VERSION "HNNBNNNYNNNNNNNNNNNNNNNNNNNNNNNNNNNNNNNNNN/4/%%%/4/'%**4NNN///"

NS_ :

BS_ :

BU_:  Airbag BAP_Tester ICAS1_Gateway ICAS1_KommunikationsServer LE1 LE2 Motor_BEV Schaltbetaetigung

BO_ 246 Motor_55: 32 Motor_BEV
 SG_ Motor_55_CRC  : 0|8@1+ (1.000000,0.000000) [0.000000|255.000000] "" ICAS1_Gateway
 SG_ Motor_55_BZ  : 8|4@1+ (1.000000,0.000000) [0.000000|15.000000] "" ICAS1_Gateway
 SG_ TS_Faktor_Radmomente  : 12|2@1+ (1.000000,0.000000) [0.000000|3.000000] "" ICAS1_Gateway
 SG_ TS_Status_MomRad_Ist  : 14|2@1+ (1.000000,0.000000) [0.000000|3.000000] "" ICAS1_Gateway
 SG_ TS_MomRad_verfuegb_maxReku_Summe  : 16|12@1+ (3.000000,-12279.000000) [-12279.000000|0.000000] "" ICAS1_Gateway
 SG_ TS_MomRad_Ist  : 28|13@1+ (3.000000,-12279.000000) [-12279.000000|12279.000000] "Unit_None" ICAS1_Gateway
 SG_ TS_MomRad_Soll_Summe  : 41|13@1+ (3.000000,-12279.000000) [-12279.000000|12279.000000] "Unit_None" ICAS1_Gateway
 SG_ TS_MomRad_Wunsch  : 54|13@1+ (3.000000,-12279.000000) [-12279.000000|12279.000000] "Unit_None" ICAS1_Gateway
 SG_ TS_MomRad_Wunsch_sek  : 67|13@1+ (3.000000,-12279.000000) [-12279.000000|12279.000000] "Unit_None" ICAS1_Gateway
 SG_ TS_MomRad_verfuegb_max  : 80|12@1+ (3.000000,0.000000) [0.000000|12279.000000] "Unit_None" ICAS1_Gateway
 SG_ TS_MomRad_verfuegb_max_sek  : 92|12@1+ (3.000000,0.000000) [0.000000|12279.000000] "Unit_None" ICAS1_Gateway
 SG_ TS_MomRad_verfuegb_maxReku  : 104|12@1+ (3.000000,-12279.000000) [-12279.000000|0.000000] "Unit_None" ICAS1_Gateway
 SG_ TS_MomRad_verfuegb_maxReku_sek  : 116|12@1+ (3.000000,-12279.000000) [-12279.000000|0.000000] "Unit_None" ICAS1_Gateway
 SG_ TS_MomRad_Ist_sek  : 128|13@1+ (3.000000,-12279.000000) [-12279.000000|12279.000000] "Unit_None" ICAS1_Gateway
 SG_ TS_Allrad_Anteil_sek  : 141|9@1+ (0.200000,0.000000) [0.000000|100.000000] "Unit_PerCent" ICAS1_Gateway
 SG_ FDR_Allrad_Anteil_max_sek  : 150|9@1+ (0.200000,0.000000) [0.000000|100.000000] "Unit_PerCent" ICAS1_Gateway
 SG_ FDR_Allrad_Anteil_min_sek  : 159|9@1+ (0.200000,0.000000) [0.000000|100.000000] "Unit_PerCent" ICAS1_Gateway
 SG_ FDR_MomRad_Eingriff  : 168|13@1+ (3.000000,-12279.000000) [-12279.000000|12279.000000] "Unit_NewtoMeter" ICAS1_Gateway
 SG_ FDR_Status_Eingriff  : 181|1@1+ (1.000000,0.000000) [0.000000|1.000000] "" ICAS1_Gateway
 SG_ FDR_MomRad_Eingriff_sek  : 182|13@1+ (3.000000,-12279.000000) [-12279.000000|12279.000000] "Unit_NewtoMeter" ICAS1_Gateway
 SG_ FDR_Status_Eingriff_sek  : 195|1@1+ (1.000000,0.000000) [0.000000|1.000000] "" ICAS1_Gateway

BO_ 190 Motor_56: 48 Motor_BEV
 SG_ Motor_56_CRC  : 0|8@1+ (1.000000,0.000000) [0.000000|255.000000] "" ICAS1_Gateway LE1 LE2
 SG_ Motor_56_BZ  : 8|4@1+ (1.000000,0.000000) [0.000000|15.000000] "" ICAS1_Gateway LE1 LE2
 SG_ MO_EM1_MinDrehzahl  : 12|14@1+ (2.000000,-10000.000000) [-10000.000000|22764.000000] "Unit_MinutInver" ICAS1_Gateway LE1
 SG_ MO_EM1_MaxDrehzahl  : 26|14@1+ (2.000000,-10000.000000) [-10000.000000|22764.000000] "Unit_MinutInver" ICAS1_Gateway LE1
 SG_ MO_EM1_DynLimit_AR  : 40|8@1+ (1.000000,0.000000) [0.000000|254.000000] "Unit_NewtoMeter" ICAS1_Gateway LE1
 SG_ MO_EM1_Periode_AR  : 48|8@1+ (0.001953,0.000000) [0.000000|0.496094] "Unit_Secon" ICAS1_Gateway LE1
 SG_ MO_EM1_SollMoment  : 56|12@1+ (0.500000,-1023.000000) [-1023.000000|1023.500000] "Unit_NewtoMeter" ICAS1_Gateway LE1
 SG_ MO_EM1_Sollmodus  : 68|4@1+ (1.000000,0.000000) [0.000000|15.000000] "" ICAS1_Gateway LE1
 SG_ MO_EM1_Min_Leistung  : 72|14@1+ (100.000000,-819000.000000) [-819000.000000|819100.000000] "Unit_Watt" ICAS1_Gateway LE1
 SG_ MO_EM1_Max_Leistung  : 86|14@1+ (100.000000,-819000.000000) [-819000.000000|819100.000000] "Unit_Watt" ICAS1_Gateway LE1
 SG_ MO_EM1_Min_Strom_Lim  : 100|13@1+ (0.500000,-2047.000000) [-2047.000000|2047.500000] "Unit_Amper" ICAS1_Gateway LE1
 SG_ MO_EM1_Max_Strom_Lim  : 113|13@1+ (0.500000,-2047.000000) [-2047.000000|2047.500000] "Unit_Amper" ICAS1_Gateway LE1
 SG_ MO_EM1_AR_Anf  : 126|3@1+ (1.000000,0.000000) [0.000000|7.000000] "" ICAS1_Gateway LE1
 SG_ MO_EM1_Kp_AR  : 129|9@1+ (0.003906,0.000000) [0.000000|1.992188] "Unit_NewtoMeterPerRPM" ICAS1_Gateway LE1
 SG_ MO_EM1_SollSpannung  : 138|12@1+ (0.500000,0.000000) [0.000000|2047.000000] "Unit_Volt" ICAS1_Gateway LE1
 SG_ MO_EM2_MinDrehzahl  : 156|14@1+ (2.000000,-10000.000000) [-10000.000000|22764.000000] "Unit_MinutInver" ICAS1_Gateway LE2
 SG_ MO_EM2_MaxDrehzahl  : 170|14@1+ (2.000000,-10000.000000) [-10000.000000|22764.000000] "Unit_MinutInver" ICAS1_Gateway LE2
 SG_ MO_EM2_DynLimit_AR  : 184|8@1+ (1.000000,0.000000) [0.000000|254.000000] "Unit_NewtoMeter" ICAS1_Gateway LE2
 SG_ MO_EM2_Periode_AR  : 192|8@1+ (0.001953,0.000000) [0.000000|0.496094] "Unit_Secon" ICAS1_Gateway LE2
 SG_ MO_EM2_SollMoment  : 200|12@1+ (0.500000,-1023.000000) [-1023.000000|1023.500000] "Unit_NewtoMeter" ICAS1_Gateway LE2
 SG_ MO_EM2_Sollmodus  : 212|4@1+ (1.000000,0.000000) [0.000000|15.000000] "" ICAS1_Gateway LE2
 SG_ MO_EM2_Min_Leistung  : 216|14@1+ (100.000000,-819000.000000) [-819000.000000|819100.000000] "Unit_Watt" ICAS1_Gateway LE2
 SG_ MO_EM2_Max_Leistung  : 230|14@1+ (100.000000,-819000.000000) [-819000.000000|819100.000000] "Unit_Watt" ICAS1_Gateway LE2
 SG_ MO_EM2_Min_Strom_Lim  : 244|13@1+ (0.500000,-2047.000000) [-2047.000000|2047.500000] "Unit_Amper" ICAS1_Gateway LE2
 SG_ MO_EM2_Max_Strom_Lim  : 257|13@1+ (0.500000,-2047.000000) [-2047.000000|2047.500000] "Unit_Amper" ICAS1_Gateway LE2
 SG_ MO_EM2_AR_Anf  : 270|3@1+ (1.000000,0.000000) [0.000000|7.000000] "" ICAS1_Gateway LE2
 SG_ MO_EM2_SollSpannung  : 282|12@1+ (0.500000,0.000000) [0.000000|2047.000000] "Unit_Volt" ICAS1_Gateway LE2
 SG_ MO_DC_Max_Strom_HV  : 296|8@1+ (0.200000,0.000000) [0.000000|50.800000] "Unit_Amper" ICAS1_Gateway
 SG_ MO_DC_SollSpannung_HV  : 304|8@1+ (2.000000,0.000000) [0.000000|508.000000] "Unit_Volt" ICAS1_Gateway
 SG_ MO_EM1_Max_Moment  : 312|12@1+ (0.500000,-1023.000000) [-1023.000000|1023.500000] "Unit_NewtoMeter" ICAS1_Gateway LE1
 SG_ MO_EM1_Min_Moment  : 324|12@1+ (0.500000,-1023.000000) [-1023.000000|1023.500000] "Unit_NewtoMeter" ICAS1_Gateway LE1
 SG_ MO_EM2_Max_Moment  : 336|12@1+ (0.500000,-1023.000000) [-1023.000000|1023.500000] "Unit_NewtoMeter" ICAS1_Gateway LE2
 SG_ MO_EM2_Min_Moment  : 348|12@1+ (0.500000,-1023.000000) [-1023.000000|1023.500000] "Unit_NewtoMeter" ICAS1_Gateway LE2

BO_ 2463978666 Motor_57: 32 Motor_BEV
 SG_ MO_EM1_Min_Spannung_Lim  : 12|10@1+ (1.000000,0.000000) [0.000000|1021.000000] "Unit_Volt" ICAS1_Gateway LE1
 SG_ MO_EM1_Max_Spannung_Lim  : 22|10@1+ (1.000000,0.000000) [0.000000|1021.000000] "Unit_Volt" ICAS1_Gateway LE1
 SG_ MO_EM1_Min_Leistung_Gesamt  : 32|13@1+ (200.000000,-819000.000000) [-819000.000000|818800.000000] "Unit_Watt" ICAS1_Gateway LE1
 SG_ MO_EM1_Max_Leistung_Gesamt  : 45|13@1+ (200.000000,-819000.000000) [-819000.000000|818800.000000] "Unit_Watt" ICAS1_Gateway LE1
 SG_ MO_EM2_Min_Leistung_Gesamt  : 58|13@1+ (200.000000,-819000.000000) [-819000.000000|818800.000000] "Unit_Watt" ICAS1_Gateway LE2
 SG_ MO_EM2_Max_Leistung_Gesamt  : 71|13@1+ (200.000000,-819000.000000) [-819000.000000|818800.000000] "Unit_Watt" ICAS1_Gateway LE2
 SG_ MO_EM2_Min_Spannung_Lim  : 84|10@1+ (1.000000,0.000000) [0.000000|1021.000000] "Unit_Volt" ICAS1_Gateway LE2
 SG_ MO_EM2_Max_Spannung_Lim  : 94|10@1+ (1.000000,0.000000) [0.000000|1021.000000] "Unit_Volt" ICAS1_Gateway LE2
 SG_ MO_EM1_Generator_Leistung  : 104|8@1+ (100.000000,0.000000) [0.000000|25300.000000] "Unit_Watt" ICAS1_Gateway LE1
 SG_ MO_Verbrauch_EM_Ges  : 120|15@1+ (10.000000,0.000000) [0.000000|327670.000000] "Unit_WattSecond" ICAS1_Gateway ICAS1_KommunikationsServer
 SG_ MO_Verbrauch_EM_Ges_Ueberlauf  : 135|1@1+ (1.000000,0.000000) [0.000000|1.000000] "" ICAS1_Gateway ICAS1_KommunikationsServer
 SG_ MO_Rekuperation_Ges_EM  : 136|15@1+ (10.000000,0.000000) [0.000000|327670.000000] "Unit_WattSecond" ICAS1_Gateway ICAS1_KommunikationsServer
 SG_ MO_Rekuperation_EM_Ges_Ueberlauf  : 151|1@1+ (1.000000,0.000000) [0.000000|1.000000] "" ICAS1_Gateway ICAS1_KommunikationsServer
 SG_ MO_Drehzahl_EM  : 152|13@1+ (8.000000,-32768.000000) [-32768.000000|32744.000000] "Unit_RevPerMinute" ICAS1_Gateway
 SG_ MO_Uebersetzung_EM  : 165|10@1+ (0.031250,0.000000) [0.031250|31.906250] "" ICAS1_Gateway
 SG_ MO_Drehzahl_EM_sek  : 175|13@1+ (8.000000,-32768.000000) [-32768.000000|32744.000000] "Unit_RevPerMinute" ICAS1_Gateway
 SG_ MO_Uebersetzung_EM_sek  : 188|10@1+ (0.031250,0.000000) [0.031250|31.906250] "" ICAS1_Gateway

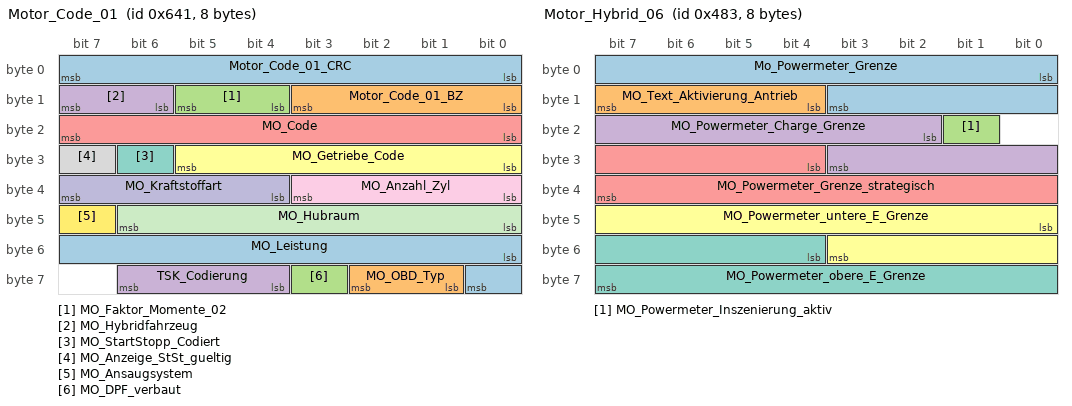
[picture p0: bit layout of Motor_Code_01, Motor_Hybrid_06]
BO_ 1601 Motor_Code_01: 8 Motor_BEV
 SG_ Motor_Code_01_CRC  : 0|8@1+ (1.000000,0.000000) [0.000000|255.000000] "" ICAS1_Gateway
 SG_ Motor_Code_01_BZ  : 8|4@1+ (1.000000,0.000000) [0.000000|15.000000] "" ICAS1_Gateway
 SG_ MO_Faktor_Momente_02  : 12|2@1+ (1.000000,0.000000) [1.000000|3.000000] "Unit_NewtoMeter" ICAS1_Gateway
 SG_ MO_Hybridfahrzeug  : 14|2@1+ (1.000000,0.000000) [0.000000|3.000000] "" ICAS1_Gateway
 SG_ MO_Code  : 16|8@1+ (1.000000,0.000000) [0.000000|255.000000] "" ICAS1_Gateway
 SG_ MO_Getriebe_Code  : 24|6@1+ (1.000000,0.000000) [0.000000|63.000000] "" ICAS1_Gateway
 SG_ MO_StartStopp_Codiert  : 30|1@1+ (1.000000,0.000000) [0.000000|1.000000] "" ICAS1_Gateway
 SG_ MO_Anzeige_StSt_gueltig  : 31|1@1+ (1.000000,0.000000) [0.000000|1.000000] "" ICAS1_Gateway
 SG_ MO_Anzahl_Zyl  : 32|4@1+ (1.000000,0.000000) [0.000000|15.000000] "" ICAS1_Gateway
 SG_ MO_Kraftstoffart  : 36|4@1+ (1.000000,0.000000) [0.000000|15.000000] "" ICAS1_Gateway ICAS1_KommunikationsServer
 SG_ MO_Hubraum  : 40|7@1+ (0.100000,0.000000) [0.000000|12.700000] "Unit_Liter" ICAS1_Gateway
 SG_ MO_Ansaugsystem  : 47|1@1+ (1.000000,0.000000) [0.000000|1.000000] "" ICAS1_Gateway
 SG_ MO_Leistung  : 48|9@1+ (1.000000,0.000000) [0.000000|511.000000] "Unit_KiloWatt" ICAS1_Gateway
 SG_ MO_OBD_Typ  : 57|2@1+ (1.000000,0.000000) [0.000000|3.000000] "" ICAS1_Gateway
 SG_ MO_DPF_verbaut  : 59|1@1+ (1.000000,0.000000) [0.000000|1.000000] "" ICAS1_Gateway
 SG_ TSK_Codierung  : 60|3@1+ (1.000000,0.000000) [0.000000|7.000000] "" ICAS1_Gateway

BO_ 1155 Motor_Hybrid_06: 8 Motor_BEV
 SG_ Mo_Powermeter_Grenze  : 0|12@1+ (1.000000,0.000000) [0.000000|4092.000000] "" ICAS1_KommunikationsServer
 SG_ MO_Text_Aktivierung_Antrieb  : 12|4@1+ (1.000000,0.000000) [0.000000|15.000000] "" ICAS1_KommunikationsServer
 SG_ MO_Powermeter_Inszenierung_aktiv  : 17|1@1+ (1.000000,0.000000) [0.000000|1.000000] "" Vector__XXX
 SG_ MO_Powermeter_Charge_Grenze  : 18|10@1+ (1.000000,0.000000) [0.000000|1021.000000] "Unit_None" ICAS1_KommunikationsServer
 SG_ MO_Powermeter_Grenze_strategisch  : 28|12@1+ (1.000000,0.000000) [0.000000|4093.000000] "Unit_None" ICAS1_KommunikationsServer
 SG_ MO_Powermeter_untere_E_Grenze  : 40|12@1+ (1.000000,0.000000) [0.000000|4093.000000] "Unit_None" Vector__XXX
 SG_ MO_Powermeter_obere_E_Grenze  : 52|12@1+ (1.000000,0.000000) [0.000000|4093.000000] "Unit_None" Vector__XXX

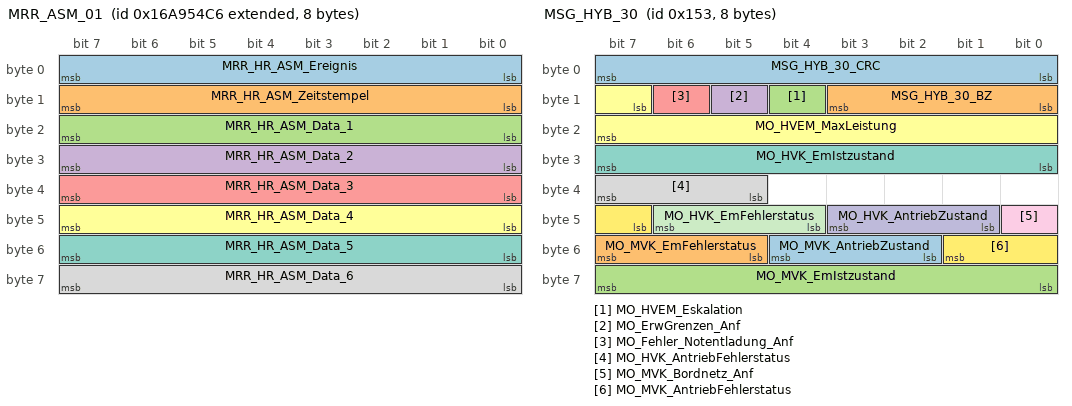
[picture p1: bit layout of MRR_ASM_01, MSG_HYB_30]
BO_ 2527679686 MRR_ASM_01: 8 ICAS1_Gateway
 SG_ MRR_HR_ASM_Ereignis  : 0|8@1+ (1.000000,0.000000) [1.000000|254.000000] "" Airbag
 SG_ MRR_HR_ASM_Zeitstempel  : 8|8@1+ (0.080000,0.000000) [0.000000|20.320000] "Unit_Secon" Airbag
 SG_ MRR_HR_ASM_Data_1  : 16|8@1+ (1.000000,0.000000) [0.000000|255.000000] "" Airbag
 SG_ MRR_HR_ASM_Data_2  : 24|8@1+ (1.000000,0.000000) [0.000000|255.000000] "" Airbag
 SG_ MRR_HR_ASM_Data_3  : 32|8@1+ (1.000000,0.000000) [0.000000|255.000000] "" Airbag
 SG_ MRR_HR_ASM_Data_4  : 40|8@1+ (1.000000,0.000000) [0.000000|255.000000] "" Airbag
 SG_ MRR_HR_ASM_Data_5  : 48|8@1+ (1.000000,0.000000) [0.000000|255.000000] "" Airbag
 SG_ MRR_HR_ASM_Data_6  : 56|8@1+ (1.000000,0.000000) [0.000000|255.000000] "" Airbag

BO_ 22 MSG3_WFS_Anfrage: 8 LE2
 SG_ WFS_MSG3_RND  : 0|32@1+ (1.000000,0.000000) [0.000000|4294967295.000000] "" ICAS1_Gateway
 SG_ WFS_MSG3_CRC  : 32|32@1+ (1.000000,0.000000) [0.000000|4294967295.000000] "" ICAS1_Gateway

BO_ 24 MSG4_WFS_Anfrage: 8 LE1
 SG_ WFS_MSG4_RND  : 0|32@1+ (1.000000,0.000000) [0.000000|4294967295.000000] "" ICAS1_Gateway
 SG_ WFS_MSG4_CRC  : 32|32@1+ (1.000000,0.000000) [0.000000|4294967295.000000] "" ICAS1_Gateway

BO_ 339 MSG_HYB_30: 8 Motor_BEV
 SG_ MSG_HYB_30_CRC  : 0|8@1+ (1.000000,0.000000) [0.000000|255.000000] "" Vector__XXX
 SG_ MSG_HYB_30_BZ  : 8|4@1+ (1.000000,0.000000) [0.000000|15.000000] "" Vector__XXX
 SG_ MO_HVEM_Eskalation  : 12|1@1+ (1.000000,0.000000) [0.000000|1.000000] "" ICAS1_Gateway
 SG_ MO_ErwGrenzen_Anf  : 13|1@1+ (1.000000,0.000000) [0.000000|1.000000] "" LE1 LE2
 SG_ MO_Fehler_Notentladung_Anf  : 14|1@1+ (1.000000,0.000000) [0.000000|1.000000] "" Vector__XXX
 SG_ MO_HVEM_MaxLeistung  : 15|9@1+ (50.000000,0.000000) [0.000000|25450.000000] "Unit_Watt" ICAS1_Gateway
 SG_ MO_HVK_EmIstzustand  : 24|8@1+ (1.000000,0.000000) [0.000000|255.000000] "" Vector__XXX
 SG_ MO_HVK_AntriebFehlerstatus  : 37|3@1+ (1.000000,0.000000) [0.000000|7.000000] "" Vector__XXX
 SG_ MO_MVK_Bordnetz_Anf  : 40|1@1+ (1.000000,0.000000) [0.000000|1.000000] "" Vector__XXX
 SG_ MO_HVK_AntriebZustand  : 41|3@1+ (1.000000,0.000000) [0.000000|7.000000] "" Vector__XXX
 SG_ MO_HVK_EmFehlerstatus  : 44|3@1+ (1.000000,0.000000) [0.000000|7.000000] "" Vector__XXX
 SG_ MO_MVK_AntriebFehlerstatus  : 47|3@1+ (1.000000,0.000000) [0.000000|7.000000] "" Vector__XXX
 SG_ MO_MVK_AntriebZustand  : 50|3@1+ (1.000000,0.000000) [0.000000|7.000000] "" Vector__XXX
 SG_ MO_MVK_EmFehlerstatus  : 53|3@1+ (1.000000,0.000000) [0.000000|7.000000] "" Vector__XXX
 SG_ MO_MVK_EmIstzustand  : 56|8@1+ (1.000000,0.000000) [0.000000|255.000000] "" Vector__XXX

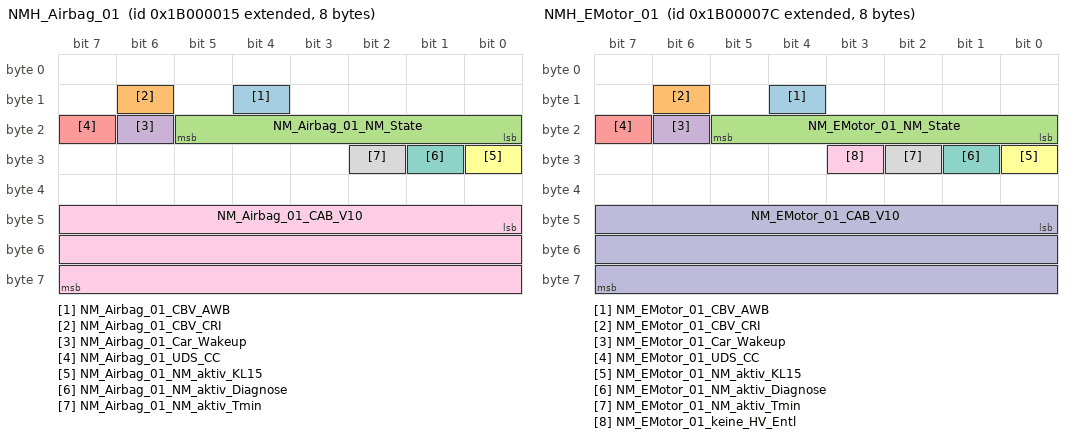
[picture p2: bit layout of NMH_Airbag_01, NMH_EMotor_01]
BO_ 2600468501 NMH_Airbag_01: 8 Airbag
 SG_ NM_Airbag_01_CBV_AWB  : 12|1@1+ (1.000000,0.000000) [0.000000|1.000000] "" ICAS1_Gateway
 SG_ NM_Airbag_01_CBV_CRI  : 14|1@1+ (1.000000,0.000000) [0.000000|1.000000] "" ICAS1_Gateway
 SG_ NM_Airbag_01_NM_State  : 16|6@1+ (1.000000,0.000000) [0.000000|63.000000] "" LE1 LE2 Motor_BEV Schaltbetaetigung
 SG_ NM_Airbag_01_Car_Wakeup  : 22|1@1+ (1.000000,0.000000) [0.000000|1.000000] "" ICAS1_Gateway
 SG_ NM_Airbag_01_UDS_CC  : 23|1@1+ (1.000000,0.000000) [0.000000|1.000000] "" Vector__XXX
 SG_ NM_Airbag_01_NM_aktiv_KL15  : 24|1@1+ (1.000000,0.000000) [0.000000|1.000000] "" Vector__XXX
 SG_ NM_Airbag_01_NM_aktiv_Diagnose  : 25|1@1+ (1.000000,0.000000) [0.000000|1.000000] "" Vector__XXX
 SG_ NM_Airbag_01_NM_aktiv_Tmin  : 26|1@1+ (1.000000,0.000000) [0.000000|1.000000] "" Vector__XXX
 SG_ NM_Airbag_01_CAB_V10  : 40|24@1+ (1.000000,0.000000) [0.000000|16777215.000000] "" ICAS1_Gateway

BO_ 2600468604 NMH_EMotor_01: 8 LE1
 SG_ NM_EMotor_01_CBV_AWB  : 12|1@1+ (1.000000,0.000000) [0.000000|1.000000] "" ICAS1_Gateway
 SG_ NM_EMotor_01_CBV_CRI  : 14|1@1+ (1.000000,0.000000) [0.000000|1.000000] "" ICAS1_Gateway
 SG_ NM_EMotor_01_NM_State  : 16|6@1+ (1.000000,0.000000) [0.000000|63.000000] "" Airbag LE2 Motor_BEV Schaltbetaetigung
 SG_ NM_EMotor_01_Car_Wakeup  : 22|1@1+ (1.000000,0.000000) [0.000000|1.000000] "" ICAS1_Gateway
 SG_ NM_EMotor_01_UDS_CC  : 23|1@1+ (1.000000,0.000000) [0.000000|1.000000] "" Vector__XXX
 SG_ NM_EMotor_01_NM_aktiv_KL15  : 24|1@1+ (1.000000,0.000000) [0.000000|1.000000] "" Vector__XXX
 SG_ NM_EMotor_01_NM_aktiv_Diagnose  : 25|1@1+ (1.000000,0.000000) [0.000000|1.000000] "" Vector__XXX
 SG_ NM_EMotor_01_NM_aktiv_Tmin  : 26|1@1+ (1.000000,0.000000) [0.000000|1.000000] "" Vector__XXX
 SG_ NM_EMotor_01_keine_HV_Entl  : 27|1@1+ (1.000000,0.000000) [0.000000|1.000000] "" Vector__XXX
 SG_ NM_EMotor_01_CAB_V10  : 40|24@1+ (1.000000,0.000000) [0.000000|16777215.000000] "" ICAS1_Gateway

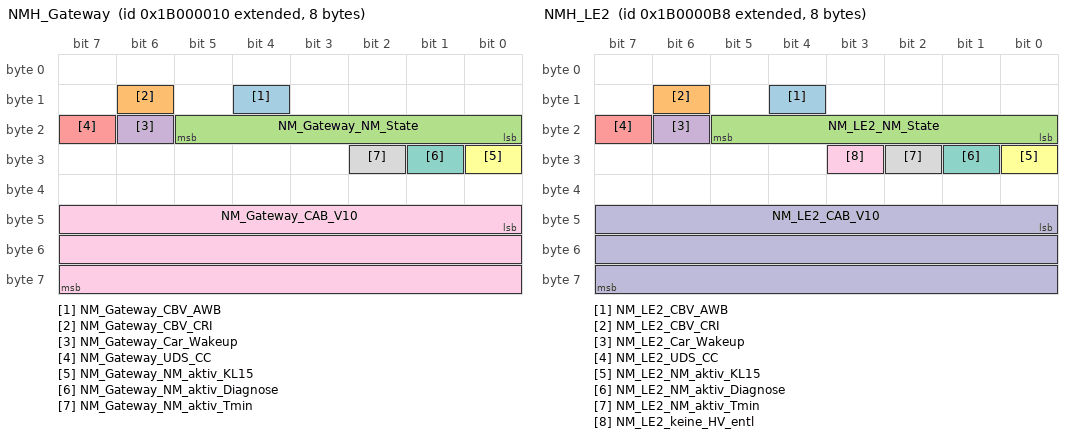
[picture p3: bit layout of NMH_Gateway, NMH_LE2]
BO_ 2600468496 NMH_Gateway: 8 ICAS1_Gateway
 SG_ NM_Gateway_CBV_AWB  : 12|1@1+ (1.000000,0.000000) [0.000000|1.000000] "" Vector__XXX
 SG_ NM_Gateway_CBV_CRI  : 14|1@1+ (1.000000,0.000000) [0.000000|1.000000] "" Vector__XXX
 SG_ NM_Gateway_NM_State  : 16|6@1+ (1.000000,0.000000) [0.000000|63.000000] "" Airbag LE1 LE2 Motor_BEV Schaltbetaetigung
 SG_ NM_Gateway_Car_Wakeup  : 22|1@1+ (1.000000,0.000000) [0.000000|1.000000] "" Vector__XXX
 SG_ NM_Gateway_UDS_CC  : 23|1@1+ (1.000000,0.000000) [0.000000|1.000000] "" Vector__XXX
 SG_ NM_Gateway_NM_aktiv_KL15  : 24|1@1+ (1.000000,0.000000) [0.000000|1.000000] "" Vector__XXX
 SG_ NM_Gateway_NM_aktiv_Diagnose  : 25|1@1+ (1.000000,0.000000) [0.000000|1.000000] "" Vector__XXX
 SG_ NM_Gateway_NM_aktiv_Tmin  : 26|1@1+ (1.000000,0.000000) [0.000000|1.000000] "" Vector__XXX
 SG_ NM_Gateway_CAB_V10  : 40|24@1+ (1.000000,0.000000) [0.000000|16777215.000000] "" Vector__XXX

BO_ 2600468664 NMH_LE2: 8 LE2
 SG_ NM_LE2_CBV_AWB  : 12|1@1+ (1.000000,0.000000) [0.000000|1.000000] "" ICAS1_Gateway
 SG_ NM_LE2_CBV_CRI  : 14|1@1+ (1.000000,0.000000) [0.000000|1.000000] "" ICAS1_Gateway
 SG_ NM_LE2_NM_State  : 16|6@1+ (1.000000,0.000000) [0.000000|63.000000] "" Airbag LE1 Motor_BEV Schaltbetaetigung
 SG_ NM_LE2_Car_Wakeup  : 22|1@1+ (1.000000,0.000000) [0.000000|1.000000] "" ICAS1_Gateway
 SG_ NM_LE2_UDS_CC  : 23|1@1+ (1.000000,0.000000) [0.000000|1.000000] "" Vector__XXX
 SG_ NM_LE2_NM_aktiv_KL15  : 24|1@1+ (1.000000,0.000000) [0.000000|1.000000] "" Vector__XXX
 SG_ NM_LE2_NM_aktiv_Diagnose  : 25|1@1+ (1.000000,0.000000) [0.000000|1.000000] "" Vector__XXX
 SG_ NM_LE2_NM_aktiv_Tmin  : 26|1@1+ (1.000000,0.000000) [0.000000|1.000000] "" Vector__XXX
 SG_ NM_LE2_keine_HV_entl  : 27|1@1+ (1.000000,0.000000) [0.000000|1.000000] "" Vector__XXX
 SG_ NM_LE2_CAB_V10  : 40|24@1+ (1.000000,0.000000) [0.000000|16777215.000000] "" ICAS1_Gateway

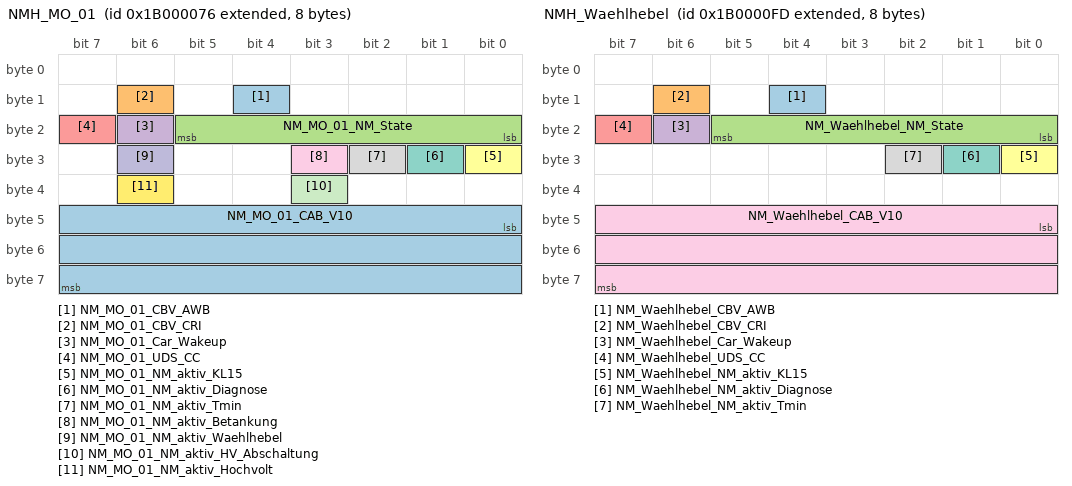
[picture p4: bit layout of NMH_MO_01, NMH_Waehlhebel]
BO_ 2600468598 NMH_MO_01: 8 Motor_BEV
 SG_ NM_MO_01_CBV_AWB  : 12|1@1+ (1.000000,0.000000) [0.000000|1.000000] "" ICAS1_Gateway
 SG_ NM_MO_01_CBV_CRI  : 14|1@1+ (1.000000,0.000000) [0.000000|1.000000] "" ICAS1_Gateway
 SG_ NM_MO_01_NM_State  : 16|6@1+ (1.000000,0.000000) [0.000000|63.000000] "" Airbag LE1 LE2 Schaltbetaetigung
 SG_ NM_MO_01_Car_Wakeup  : 22|1@1+ (1.000000,0.000000) [0.000000|1.000000] "" ICAS1_Gateway
 SG_ NM_MO_01_UDS_CC  : 23|1@1+ (1.000000,0.000000) [0.000000|1.000000] "" Vector__XXX
 SG_ NM_MO_01_NM_aktiv_KL15  : 24|1@1+ (1.000000,0.000000) [0.000000|1.000000] "" Vector__XXX
 SG_ NM_MO_01_NM_aktiv_Diagnose  : 25|1@1+ (1.000000,0.000000) [0.000000|1.000000] "" Vector__XXX
 SG_ NM_MO_01_NM_aktiv_Tmin  : 26|1@1+ (1.000000,0.000000) [0.000000|1.000000] "" Vector__XXX
 SG_ NM_MO_01_NM_aktiv_Betankung  : 27|1@1+ (1.000000,0.000000) [0.000000|1.000000] "" Vector__XXX
 SG_ NM_MO_01_NM_aktiv_Waehlhebel  : 30|1@1+ (1.000000,0.000000) [0.000000|1.000000] "" Vector__XXX
 SG_ NM_MO_01_NM_aktiv_HV_Abschaltung  : 35|1@1+ (1.000000,0.000000) [0.000000|1.000000] "" Vector__XXX
 SG_ NM_MO_01_NM_aktiv_Hochvolt  : 38|1@1+ (1.000000,0.000000) [0.000000|1.000000] "" Vector__XXX
 SG_ NM_MO_01_CAB_V10  : 40|24@1+ (1.000000,0.000000) [0.000000|16777215.000000] "" ICAS1_Gateway

BO_ 2600468733 NMH_Waehlhebel: 8 Schaltbetaetigung
 SG_ NM_Waehlhebel_CBV_AWB  : 12|1@1+ (1.000000,0.000000) [0.000000|1.000000] "" ICAS1_Gateway
 SG_ NM_Waehlhebel_CBV_CRI  : 14|1@1+ (1.000000,0.000000) [0.000000|1.000000] "" ICAS1_Gateway
 SG_ NM_Waehlhebel_NM_State  : 16|6@1+ (1.000000,0.000000) [0.000000|63.000000] "" Airbag LE1 LE2 Motor_BEV
 SG_ NM_Waehlhebel_Car_Wakeup  : 22|1@1+ (1.000000,0.000000) [0.000000|1.000000] "" ICAS1_Gateway
 SG_ NM_Waehlhebel_UDS_CC  : 23|1@1+ (1.000000,0.000000) [0.000000|1.000000] "" Vector__XXX
 SG_ NM_Waehlhebel_NM_aktiv_KL15  : 24|1@1+ (1.000000,0.000000) [0.000000|1.000000] "" Vector__XXX
 SG_ NM_Waehlhebel_NM_aktiv_Diagnose  : 25|1@1+ (1.000000,0.000000) [0.000000|1.000000] "" Vector__XXX
 SG_ NM_Waehlhebel_NM_aktiv_Tmin  : 26|1@1+ (1.000000,0.000000) [0.000000|1.000000] "" Vector__XXX
 SG_ NM_Waehlhebel_CAB_V10  : 40|24@1+ (1.000000,0.000000) [0.000000|16777215.000000] "" ICAS1_Gateway

BO_ 2621440533 OBDC_Airbag_01_Req_FD: 64 ICAS1_Gateway
 SG_ OBDC_Airbag_01_Req_FD_Data  : 0|512@1+ (1.000000,0.000000) [0.000000|13407807929942597099574024998205846127479365820592393377723561443721764030073546976801874298166903427690031858186486050853753882811946569946433649006084096.000000] "" Airbag

BO_ 2621571605 OBDC_Airbag_01_Resp_FD: 64 Airbag
 SG_ OBDC_Airbag_01_Resp_FD_Data  : 0|512@1+ (1.000000,0.000000) [0.000000|13407807929942597099574024998205846127479365820592393377723561443721764030073546976801874298166903427690031858186486050853753882811946569946433649006084096.000000] "" ICAS1_Gateway

BO_ 2621440636 OBDC_EMotor_01_Req_FD: 64 ICAS1_Gateway
 SG_ OBDC_EMotor_01_Req_FD_Data  : 0|512@1+ (1.000000,0.000000) [0.000000|13407807929942597099574024998205846127479365820592393377723561443721764030073546976801874298166903427690031858186486050853753882811946569946433649006084096.000000] "" LE1

BO_ 2621571708 OBDC_EMotor_01_Resp_FD: 64 LE1
 SG_ OBDC_EMotor_01_Resp_FD_Data  : 0|512@1+ (1.000000,0.000000) [0.000000|13407807929942597099574024998205846127479365820592393377723561443721764030073546976801874298166903427690031858186486050853753882811946569946433649006084096.000000] "" ICAS1_Gateway

BO_ 2621440696 OBDC_EMotor_02_Req_FD: 64 ICAS1_Gateway
 SG_ OBDC_EMotor_02_Req_FD_Data  : 0|512@1+ (1.000000,0.000000) [0.000000|13407807929942597099574024998205846127479365820592393377723561443721764030073546976801874298166903427690031858186486050853753882811946569946433649006084096.000000] "" LE2

BO_ 2621571768 OBDC_EMotor_02_Resp_FD: 64 LE2
 SG_ OBDC_EMotor_02_Resp_FD_Data  : 0|512@1+ (1.000000,0.000000) [0.000000|13407807929942597099574024998205846127479365820592393377723561443721764030073546976801874298166903427690031858186486050853753882811946569946433649006084096.000000] "" ICAS1_Gateway

BO_ 2621506048 OBDC_Funktionaler_Req_All_FD: 64 ICAS1_Gateway
 SG_ OBDC_Funktion_Req_All_FD_Data  : 0|512@1+ (1.000000,0.000000) [0.000000|13407807929942597099574024998205846127479365820592393377723561443721764030073546976801874298166903427690031858186486050853753882811946569946433649006084096.000000] "" Airbag LE1 LE2 Motor_BEV

BO_ 2621440630 OBDC_MO_01_Req_FD: 64 ICAS1_Gateway
 SG_ OBDC_MO_01_Req_FD_Data  : 0|512@1+ (1.000000,0.000000) [0.000000|13407807929942597099574024998205846127479365820592393377723561443721764030073546976801874298166903427690031858186486050853753882811946569946433649006084096.000000] "" Motor_BEV

BO_ 2621571702 OBDC_MO_01_Resp_FD: 64 Motor_BEV
 SG_ OBDC_MO_01_Resp_FD_Data  : 0|512@1+ (1.000000,0.000000) [0.000000|13407807929942597099574024998205846127479365820592393377723561443721764030073546976801874298166903427690031858186486050853753882811946569946433649006084096.000000] "" ICAS1_Gateway

BO_ 2564502513 OBDx_allOBD_Req: 8 ICAS1_Gateway
 SG_ OBDx_allOBD_Req_Data  : 0|64@1+ (1.000000,0.000000) [0.000000|18446744073709551616.000000] "" LE1 LE2 Motor_BEV

BO_ 2564425457 OBDx_LE1_Req: 8 ICAS1_Gateway
 SG_ OBDx_LE1_Req_Data  : 0|64@1+ (1.000000,0.000000) [0.000000|18446744073709551616.000000] "" LE1

BO_ 2564485382 OBDx_LE1_Resp: 8 LE1
 SG_ OBDx_LE1_Resp_Data  : 0|64@1+ (1.000000,0.000000) [0.000000|18446744073709551616.000000] "" ICAS1_Gateway

BO_ 2564425713 OBDx_LE2_Req: 8 ICAS1_Gateway
 SG_ OBDx_LE2_Req_Data  : 0|64@1+ (1.000000,0.000000) [0.000000|18446744073709551616.000000] "" LE2

BO_ 2564485383 OBDx_LE2_Resp: 8 LE2
 SG_ OBDx_LE2_Resp_Data  : 0|64@1+ (1.000000,0.000000) [0.000000|18446744073709551616.000000] "" ICAS1_Gateway

BO_ 2564424177 OBDx_MO_01_Req: 8 ICAS1_Gateway
 SG_ OBDx_MO_01_Req_Data  : 0|64@1+ (1.000000,0.000000) [0.000000|18446744073709551616.000000] "" Motor_BEV

BO_ 2564485377 OBDx_MO_01_Resp: 8 Motor_BEV
 SG_ OBDx_MO_01_Resp_Data  : 0|64@1+ (1.000000,0.000000) [0.000000|18446744073709551616.000000] "" ICAS1_Gateway

BO_ 627 OCC_01: 24 ICAS1_Gateway
 SG_ OCC_01_CRC  : 0|8@1+ (1.000000,0.000000) [0.000000|255.000000] "" Vector__XXX
 SG_ OCC_01_BZ  : 8|4@1+ (1.000000,0.000000) [0.000000|15.000000] "" Vector__XXX
 SG_ OCC_Stecker_Status  : 12|2@1+ (1.000000,0.000000) [0.000000|3.000000] "" Vector__XXX
 SG_ OCC_Status_Spgfreiheit  : 14|2@1+ (1.000000,0.000000) [0.000000|3.000000] "" Motor_BEV
 SG_ OCC_DC_IstStrom  : 16|11@1+ (0.100000,0.000000) [0.000000|204.500000] "Unit_Amper" Vector__XXX
 SG_ OCC_CC_Latchstatus_DC_GBT  : 27|3@1+ (1.000000,0.000000) [0.000000|7.000000] "" Vector__XXX
 SG_ OCC_Status_EoHVL  : 30|2@1+ (1.000000,0.000000) [0.000000|3.000000] "" Motor_BEV
 SG_ OCC_I_istAC_Netz_L1  : 32|9@1+ (0.100000,0.000000) [0.000000|50.800000] "Unit_Amper" Vector__XXX
 SG_ OCC_PP_Latchstatus_A  : 41|3@1+ (1.000000,0.000000) [0.000000|7.000000] "" Vector__XXX
 SG_ OCC_PP_Latchstatus_B  : 44|3@1+ (1.000000,0.000000) [0.000000|7.000000] "" Vector__XXX
 SG_ OCC_I_istAC_Netz_L2  : 47|9@1+ (0.100000,0.000000) [0.000000|50.800000] "Unit_Amper" Vector__XXX
 SG_ OCC_I_istAC_Netz_L3  : 56|9@1+ (0.100000,0.000000) [0.000000|50.800000] "Unit_Amper" Vector__XXX
 SG_ OCC_IstModus  : 65|3@1+ (1.000000,0.000000) [0.000000|7.000000] "" Motor_BEV
 SG_ OCC_CP_Status_A  : 68|2@1+ (1.000000,0.000000) [0.000000|3.000000] "" Vector__XXX
 SG_ OCC_CP_Status_B  : 70|2@1+ (1.000000,0.000000) [0.000000|3.000000] "" Vector__XXX
 SG_ OCC_IstSpannung_HV  : 72|10@1+ (1.000000,0.000000) [0.000000|1021.000000] "Unit_Volt" Vector__XXX
 SG_ OCC_PP_Status_A  : 82|2@1+ (1.000000,0.000000) [0.000000|3.000000] "" Vector__XXX
 SG_ OCC_PP_Status_B  : 84|2@1+ (1.000000,0.000000) [0.000000|3.000000] "" Vector__XXX
 SG_ OCC_CC_Status_DC_GBT  : 86|2@1+ (1.000000,0.000000) [0.000000|3.000000] "" Vector__XXX
 SG_ OCC_CC_Fehlerstatus_DC_GBT  : 88|4@1+ (1.000000,0.000000) [0.000000|15.000000] "" Vector__XXX
 SG_ OCC_Temp_Sensor_Fehlerstatus_DC  : 92|4@1+ (1.000000,0.000000) [0.000000|15.000000] "" Vector__XXX
 SG_ OCC_Temp_Sensor_Fehlerstatus_AC  : 96|3@1+ (1.000000,0.000000) [0.000000|7.000000] "" Vector__XXX
 SG_ OCC_Temp_Sensor_Status  : 99|3@1+ (1.000000,0.000000) [0.000000|7.000000] "" Vector__XXX

BO_ 2463978709 OCC_02: 32 ICAS1_Gateway
 SG_ OCC_CP_Tastgrad_A  : 12|10@1+ (0.100000,0.000000) [0.000000|100.000000] "Unit_PerCent" Vector__XXX
 SG_ OCC_CP_Tastgrad_B  : 22|10@1+ (0.100000,0.000000) [0.000000|100.000000] "Unit_PerCent" Vector__XXX
 SG_ OCC_CP_Frequenz_A  : 32|8@1+ (1.000000,880.000000) [880.000000|1132.000000] "Unit_Hertz" Vector__XXX
 SG_ OCC_CP_Frequenz_B  : 40|8@1+ (1.000000,880.000000) [880.000000|1132.000000] "Unit_Hertz" Vector__XXX
 SG_ OCC_CP_Spannung_A  : 48|9@1+ (0.100000,-25.000000) [-25.000000|25.900000] "Unit_Volt" Vector__XXX
 SG_ OCC_CP_Spannung_B  : 57|9@1+ (0.100000,-25.000000) [-25.000000|25.900000] "Unit_Volt" Vector__XXX
 SG_ OCC_CP_Fehlerstatus_A  : 66|3@1+ (1.000000,0.000000) [0.000000|7.000000] "" Vector__XXX
 SG_ OCC_CP_Fehlerstatus_B  : 69|3@1+ (1.000000,0.000000) [0.000000|7.000000] "" Vector__XXX
 SG_ OCC_Temp_Ladedose_A_AC  : 72|8@1+ (1.000000,-40.000000) [-40.000000|213.000000] "Unit_DegreCelsi" Vector__XXX
 SG_ OCC_Temp_Ladedose_A_DC_minus  : 80|8@1+ (1.000000,-40.000000) [-40.000000|213.000000] "Unit_DegreCelsi" Vector__XXX
 SG_ OCC_Temp_Ladedose_A_DC_plus  : 88|8@1+ (1.000000,-40.000000) [-40.000000|213.000000] "Unit_DegreCelsi" Vector__XXX
 SG_ OCC_U_istAC_Netz_L1  : 96|9@1+ (1.000000,0.000000) [0.000000|509.000000] "Unit_Volt" Vector__XXX
 SG_ OCC_U_istAC_Netz_L2  : 105|9@1+ (1.000000,0.000000) [0.000000|509.000000] "Unit_Volt" Vector__XXX
 SG_ OCC_U_istAC_Netz_L3  : 114|9@1+ (1.000000,0.000000) [0.000000|508.000000] "Unit_Volt" Vector__XXX
 SG_ OCC_StatusVerEntriegelungAktor_A  : 123|3@1+ (1.000000,0.000000) [0.000000|7.000000] "" Vector__XXX
 SG_ OCC_SteckerEntriegelung_Verbot_A  : 126|2@1+ (1.000000,0.000000) [0.000000|3.000000] "" Vector__XXX
 SG_ OCC_StatusVerEntriegelungAktor_B  : 128|3@1+ (1.000000,0.000000) [0.000000|7.000000] "" Vector__XXX
 SG_ OCC_SteckerEntriegelung_Verbot_B  : 131|2@1+ (1.000000,0.000000) [0.000000|3.000000] "" Vector__XXX
 SG_ OCC_Verriegelung_Status_A  : 133|3@1+ (1.000000,0.000000) [0.000000|7.000000] "" Vector__XXX
 SG_ OCC_Verriegelung_Status_B  : 136|3@1+ (1.000000,0.000000) [0.000000|7.000000] "" Vector__XXX
 SG_ OCC_RtmWarnLadeKommunikation  : 139|3@1+ (1.000000,0.000000) [0.000000|7.000000] "" Vector__XXX
 SG_ OCC_Ist_Wirkungsgrad  : 145|7@1+ (1.000000,0.000000) [0.000000|100.000000] "Unit_PerCent" Vector__XXX
 SG_ OCC_PP_Max_Strom_A  : 152|4@1+ (1.000000,0.000000) [0.000000|15.000000] "" Vector__XXX
 SG_ OCC_PP_Max_Strom_B  : 156|4@1+ (1.000000,0.000000) [0.000000|15.000000] "" Vector__XXX
 SG_ OCC_DC_MaxStrom  : 160|11@1+ (0.100000,0.000000) [0.000000|204.500000] "Unit_Amper" Vector__XXX
 SG_ OCC_Derating_Temperatur  : 171|1@1+ (1.000000,0.000000) [0.000000|1.000000] "" Vector__XXX
 SG_ OCC_Fehlerzustand  : 172|1@1+ (1.000000,0.000000) [0.000000|1.000000] "" Vector__XXX
 SG_ OCC_Ladest_Entriegelungs_Verbot  : 173|3@1+ (1.000000,0.000000) [0.000000|7.000000] "" Vector__XXX
 SG_ OCC_Netzfrequenz_EVU  : 176|9@1+ (0.100000,40.000000) [40.000000|80.000000] "Unit_Hertz" Vector__XXX
 SG_ OCC_Warnzustand  : 185|1@1+ (1.000000,0.000000) [0.000000|1.000000] "" Vector__XXX
 SG_ OCC_Kuehltemperatur  : 192|8@1+ (1.000000,-40.000000) [-40.000000|213.000000] "Unit_DegreCelsi" Motor_BEV
 SG_ OCC_PP_Fehlerstatus_A  : 200|4@1+ (1.000000,0.000000) [0.000000|15.000000] "" Vector__XXX
 SG_ OCC_PP_Fehlerstatus_B  : 204|4@1+ (1.000000,0.000000) [0.000000|15.000000] "" Vector__XXX

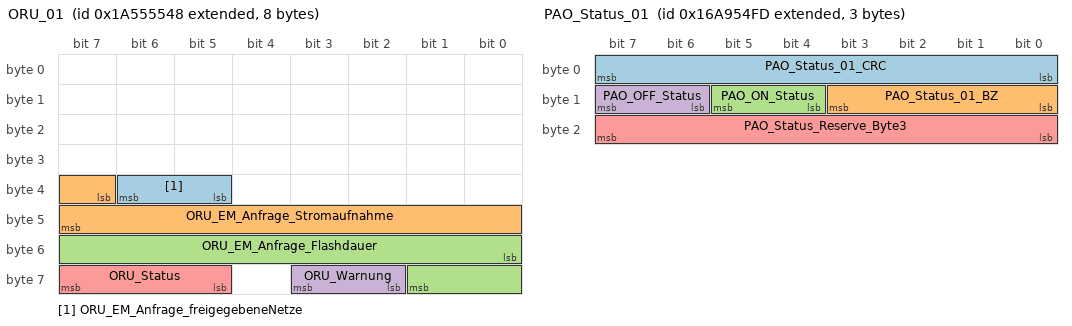
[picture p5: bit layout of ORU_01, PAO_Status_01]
BO_ 2589283656 ORU_01: 8 ICAS1_Gateway
 SG_ ORU_EM_Anfrage_freigegebeneNetze  : 37|2@1+ (1.000000,0.000000) [0.000000|3.000000] "" Vector__XXX
 SG_ ORU_EM_Anfrage_Stromaufnahme  : 39|9@1+ (0.100000,0.000000) [0.000000|51.100000] "Unit_Amper" Vector__XXX
 SG_ ORU_EM_Anfrage_Flashdauer  : 48|10@1+ (10.000000,0.000000) [0.000000|10230.000000] "Unit_Secon" Vector__XXX
 SG_ ORU_Warnung  : 58|2@1+ (1.000000,0.000000) [0.000000|3.000000] "" Vector__XXX
 SG_ ORU_Status  : 61|3@1+ (1.000000,0.000000) [0.000000|7.000000] "" Airbag LE1 LE2 Motor_BEV

BO_ 2527679741 PAO_Status_01: 3 ICAS1_Gateway
 SG_ PAO_Status_01_CRC  : 0|8@1+ (1.000000,0.000000) [0.000000|255.000000] "" Airbag
 SG_ PAO_Status_01_BZ  : 8|4@1+ (1.000000,0.000000) [0.000000|15.000000] "" Airbag
 SG_ PAO_ON_Status  : 12|2@1+ (1.000000,0.000000) [0.000000|3.000000] "" Airbag
 SG_ PAO_OFF_Status  : 14|2@1+ (1.000000,0.000000) [0.000000|3.000000] "" Airbag
 SG_ PAO_Status_Reserve_Byte3  : 16|8@1+ (1.000000,0.000000) [0.000000|255.000000] "" Vector__XXX

BO_ 518 Parken_01: 24 ICAS1_Gateway
 SG_ Parken_BKD_Anf  : 12|4@1+ (0.100000,0.000000) [0.000000|1.300000] "Unit_Secon" Vector__XXX
 SG_ Parken_Verz_Anf  : 16|7@1+ (0.100000,-12.600000) [-12.600000|-0.100000] "Unit_MeterPerSeconSquar" Vector__XXX
 SG_ Parken_Prefill_Anf  : 23|1@1+ (1.000000,0.000000) [0.000000|1.000000] "" Vector__XXX
 SG_ Parken_Warnruck_Anf  : 24|2@1+ (1.000000,0.000000) [0.000000|3.000000] "" Vector__XXX
 SG_ Parken_Verz_Anf_ASIL  : 26|2@1+ (1.000000,0.000000) [0.000000|3.000000] "" Vector__XXX
 SG_ Parken_Warnruckeln_Anf  : 28|2@1+ (1.000000,0.000000) [0.000000|3.000000] "" Vector__XXX
 SG_ Parken_beibehalten  : 30|2@1+ (1.000000,0.000000) [0.000000|3.000000] "" Vector__XXX
 SG_ Parken_Anforderung_HMS  : 32|3@1+ (1.000000,0.000000) [0.000000|7.000000] "" Vector__XXX
 SG_ Parken_Notstopp_Anf  : 40|2@1+ (1.000000,0.000000) [0.000000|3.000000] "" Vector__XXX
 SG_ Parken_Anhalteweg_Anf  : 42|10@1+ (0.010000,0.000000) [0.000000|10.210000] "Unit_Meter" Vector__XXX
 SG_ Parken_aktives_System  : 52|4@1+ (1.000000,0.000000) [0.000000|15.000000] "" Motor_BEV
 SG_ Parken_max_Beschleunigung  : 56|7@1+ (0.100000,-6.000000) [-5.900000|6.100000] "Unit_MeterPerSeconSquar" Motor_BEV
 SG_ Parken_Blinker_li_Anf  : 63|1@1+ (1.000000,0.000000) [0.000000|1.000000] "" Vector__XXX
 SG_ Parken_QFK_KruemmSoll  : 64|15@1+ (0.000007,0.000000) [0.000000|0.219539] "Unit_MeterInver" Vector__XXX
 SG_ Parken_QFK_KruemmSoll_VZ  : 79|1@1+ (1.000000,0.000000) [0.000000|1.000000] "" Vector__XXX
 SG_ Parken_QFK_Spuerb  : 80|8@1+ (0.400000,0.000000) [0.000000|100.000000] "Unit_PerCent" Vector__XXX
 SG_ Parken_QFK_AnfStat  : 88|4@1+ (1.000000,0.000000) [0.000000|15.000000] "" Vector__XXX
 SG_ Parken_QFK_Signal1  : 92|10@1+ (1.000000,0.000000) [0.000000|1023.000000] "" Vector__XXX
 SG_ Parken_QFK_Art1  : 102|3@1+ (1.000000,0.000000) [0.000000|7.000000] "" Vector__XXX
 SG_ Parken_QFK_Art2  : 105|3@1+ (1.000000,0.000000) [0.000000|7.000000] "" Vector__XXX
 SG_ Parken_QFK_Signal2  : 108|10@1+ (1.000000,0.000000) [0.000000|1023.000000] "" Vector__XXX
 SG_ Parken_Sollbeschleunigung  : 118|9@1+ (0.010000,-4.110000) [-4.100000|1.000000] "Unit_MeterPerSeconSquar" Motor_BEV
 SG_ Parken_Blinker_re_Anf  : 127|1@1+ (1.000000,0.000000) [0.000000|1.000000] "" Vector__XXX
 SG_ Parken_Status_IPA_TSK  : 128|4@1+ (1.000000,0.000000) [0.000000|15.000000] "" Motor_BEV
 SG_ Parken_erhoehtes_Moment  : 132|4@1+ (1.000000,0.000000) [0.000000|15.000000] "" Motor_BEV
 SG_ Parken_max_Geschwindigkeit  : 136|8@1+ (0.100000,0.000000) [0.100000|25.000000] "Unit_KiloMeterPerHour" Motor_BEV
 SG_ Parken_Soll_Anhalteweg_Anf  : 144|10@1+ (0.010000,0.000000) [0.000000|10.210000] "Unit_Meter" Vector__XXX
 SG_ Parken_Fahrstufenwunsch  : 154|3@1+ (1.000000,0.000000) [0.000000|7.000000] "" Motor_BEV
 SG_ IPA_TPA_Remote  : 157|2@1+ (1.000000,0.000000) [0.000000|3.000000] "" Vector__XXX
 SG_ IPA_TPA_Remote_Anf  : 159|1@1+ (1.000000,0.000000) [0.000000|1.000000] "" Vector__XXX
 SG_ IPA_TPA_Fehler  : 160|4@1+ (1.000000,0.000000) [0.000000|15.000000] "" Vector__XXX
 SG_ IPA_TPA_Abbruch  : 164|4@1+ (1.000000,0.000000) [0.000000|15.000000] "" Vector__XXX
 SG_ IPA_TPA_Status  : 168|4@1+ (1.000000,0.000000) [0.000000|15.000000] "" Vector__XXX

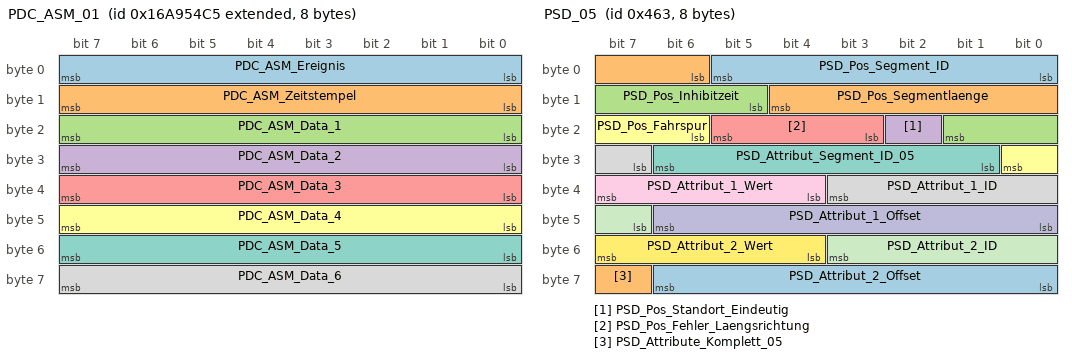
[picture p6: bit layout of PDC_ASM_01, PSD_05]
BO_ 2527679685 PDC_ASM_01: 8 ICAS1_Gateway
 SG_ PDC_ASM_Ereignis  : 0|8@1+ (1.000000,0.000000) [1.000000|254.000000] "" Airbag
 SG_ PDC_ASM_Zeitstempel  : 8|8@1+ (0.080000,0.000000) [0.000000|20.320000] "Unit_Secon" Airbag
 SG_ PDC_ASM_Data_1  : 16|8@1+ (1.000000,0.000000) [0.000000|255.000000] "" Airbag
 SG_ PDC_ASM_Data_2  : 24|8@1+ (1.000000,0.000000) [0.000000|255.000000] "" Airbag
 SG_ PDC_ASM_Data_3  : 32|8@1+ (1.000000,0.000000) [0.000000|255.000000] "" Airbag
 SG_ PDC_ASM_Data_4  : 40|8@1+ (1.000000,0.000000) [0.000000|255.000000] "" Airbag
 SG_ PDC_ASM_Data_5  : 48|8@1+ (1.000000,0.000000) [0.000000|255.000000] "" Airbag
 SG_ PDC_ASM_Data_6  : 56|8@1+ (1.000000,0.000000) [0.000000|255.000000] "" Airbag

BO_ 319 PreCrash_02: 8 Airbag
 SG_ PreCrash_Charisma_FahrPr  : 12|4@1+ (1.000000,0.000000) [0.000000|15.000000] "" ICAS1_Gateway
 SG_ PreCrash_Charisma_Status  : 16|2@1+ (1.000000,0.000000) [0.000000|3.000000] "" ICAS1_Gateway
 SG_ PreCrash_Schiebedach_schliessen  : 18|1@1+ (1.000000,0.000000) [0.000000|1.000000] "" ICAS1_Gateway
 SG_ PreCrash_Fenster_schliessen  : 19|1@1+ (1.000000,0.000000) [0.000000|1.000000] "" ICAS1_Gateway
 SG_ PreCrash_Blinken  : 20|3@1+ (1.000000,0.000000) [0.000000|7.000000] "" ICAS1_Gateway
 SG_ SC_PreSense_FCWP  : 23|1@1+ (1.000000,0.000000) [0.000000|1.000000] "" ICAS1_Gateway
 SG_ PreCrash_Tueren_Verriegeln  : 24|1@1+ (1.000000,0.000000) [0.000000|1.000000] "" ICAS1_Gateway
 SG_ PreCrash_FS_Laengsverstellung  : 25|1@1+ (1.000000,0.000000) [0.000000|1.000000] "" ICAS1_Gateway
 SG_ PreCrash_Anforderung_AFR  : 26|3@1+ (1.000000,0.000000) [0.000000|7.000000] "" ICAS1_Gateway
 SG_ SC_PreCrash_LED  : 29|2@1+ (1.000000,0.000000) [0.000000|3.000000] "" ICAS1_Gateway
 SG_ PreCrash_FS_Pneumatik_ansteuern  : 31|1@1+ (1.000000,0.000000) [0.000000|1.000000] "" ICAS1_Gateway
 SG_ PreCrash_BFS_Pneumatik_ansteuern  : 32|1@1+ (1.000000,0.000000) [0.000000|1.000000] "" ICAS1_Gateway
 SG_ PreCrash_Fo_Pneumatik_ansteuern  : 33|1@1+ (1.000000,0.000000) [0.000000|1.000000] "" ICAS1_Gateway
 SG_ PreCrash_FS_Sitzlehne_verfahren  : 34|3@1+ (1.000000,0.000000) [0.000000|7.000000] "" ICAS1_Gateway
 SG_ PreCrash_BFS_Sitzlehne_verfahren  : 37|3@1+ (1.000000,0.000000) [0.000000|7.000000] "" ICAS1_Gateway
 SG_ PreCrash_Fo_Sitzlehne_verfahren  : 40|3@1+ (1.000000,0.000000) [0.000000|7.000000] "" ICAS1_Gateway
 SG_ PreCrash_FS_KSV_verfahren  : 43|4@1+ (1.000000,0.000000) [0.000000|15.000000] "" ICAS1_Gateway
 SG_ PreCrash_BFS_KSV_verfahren  : 47|4@1+ (1.000000,0.000000) [0.000000|15.000000] "" ICAS1_Gateway
 SG_ PreCrash_Fo_KSV_verfahren  : 51|4@1+ (1.000000,0.000000) [0.000000|15.000000] "" ICAS1_Gateway
 SG_ PreCrash_BFS_Laengsverstellung  : 55|1@1+ (1.000000,0.000000) [0.000000|1.000000] "" ICAS1_Gateway
 SG_ SC_PreCrash_Warnung  : 56|4@1+ (1.000000,0.000000) [0.000000|15.000000] "" ICAS1_Gateway ICAS1_KommunikationsServer
 SG_ SC_PreCrash_Texte  : 60|4@1+ (1.000000,0.000000) [0.000000|15.000000] "" ICAS1_Gateway ICAS1_KommunikationsServer

BO_ 1122 PSD_04: 8 ICAS1_Gateway
 SG_ PSD_Segment_ID  : 0|6@1+ (1.000000,0.000000) [2.000000|63.000000] "" Motor_BEV
 SG_ PSD_Vorgaenger_Segment_ID  : 6|6@1+ (1.000000,0.000000) [2.000000|63.000000] "" Motor_BEV
 SG_ PSD_Segmentlaenge  : 12|7@1+ (2.000000,0.000000) [0.000000|254.000000] "Unit_Meter" Motor_BEV
 SG_ PSD_Strassenkategorie  : 19|3@1+ (1.000000,0.000000) [0.000000|7.000000] "" Motor_BEV
 SG_ PSD_Endkruemmung  : 22|8@1+ (1.000000,0.000000) [0.000000|254.000000] "Unit_None" Motor_BEV
 SG_ PSD_Endkruemmung_Vorz  : 30|1@1+ (1.000000,0.000000) [0.000000|1.000000] "" Motor_BEV
 SG_ PSD_Idenditaets_ID  : 31|6@1+ (1.000000,0.000000) [2.000000|63.000000] "" Vector__XXX
 SG_ PSD_ADAS_Qualitaet  : 37|1@1+ (1.000000,0.000000) [0.000000|1.000000] "" Motor_BEV
 SG_ PSD_wahrscheinlichster_Pfad  : 38|1@1+ (1.000000,0.000000) [0.000000|1.000000] "" Motor_BEV
 SG_ PSD_Geradester_Pfad  : 39|1@1+ (1.000000,0.000000) [0.000000|1.000000] "" Motor_BEV
 SG_ PSD_Fahrspuren_Anzahl  : 40|3@1+ (1.000000,0.000000) [0.000000|7.000000] "" Motor_BEV
 SG_ PSD_Bebauung  : 43|1@1+ (1.000000,0.000000) [0.000000|1.000000] "" Motor_BEV
 SG_ PSD_Segment_Komplett  : 44|1@1+ (1.000000,0.000000) [0.000000|1.000000] "" Motor_BEV
 SG_ PSD_Rampe  : 45|2@1+ (1.000000,0.000000) [0.000000|3.000000] "" Motor_BEV
 SG_ PSD_Anfangskruemmung  : 47|8@1+ (1.000000,0.000000) [0.000000|254.000000] "" Motor_BEV
 SG_ PSD_Anfangskruemmung_Vorz  : 55|1@1+ (1.000000,0.000000) [0.000000|1.000000] "" Motor_BEV
 SG_ PSD_Abzweigerichtung  : 56|1@1+ (1.000000,0.000000) [0.000000|1.000000] "" Motor_BEV
 SG_ PSD_Abzweigewinkel  : 57|7@1+ (1.417323,0.000000) [0.000000|180.000021] "" Motor_BEV

BO_ 1123 PSD_05: 8 ICAS1_Gateway
 SG_ PSD_Pos_Segment_ID  : 0|6@1+ (1.000000,0.000000) [2.000000|63.000000] "" Motor_BEV
 SG_ PSD_Pos_Segmentlaenge  : 6|7@1+ (2.000000,0.000000) [0.000000|254.000000] "Unit_Meter" Motor_BEV
 SG_ PSD_Pos_Inhibitzeit  : 13|5@1+ (10.000000,0.000000) [0.000000|310.000000] "Unit_MilliSecon" Motor_BEV
 SG_ PSD_Pos_Standort_Eindeutig  : 18|1@1+ (1.000000,0.000000) [0.000000|1.000000] "" Motor_BEV
 SG_ PSD_Pos_Fehler_Laengsrichtung  : 19|3@1+ (1.000000,0.000000) [0.000000|7.000000] "" Motor_BEV
 SG_ PSD_Pos_Fahrspur  : 22|3@1+ (1.000000,0.000000) [0.000000|7.000000] "" Motor_BEV
 SG_ PSD_Attribut_Segment_ID_05  : 25|6@1+ (1.000000,0.000000) [2.000000|63.000000] "" Motor_BEV
 SG_ PSD_Attribut_1_ID  : 31|5@1+ (1.000000,0.000000) [1.000000|31.000000] "" Motor_BEV
 SG_ PSD_Attribut_1_Wert  : 36|4@1+ (1.000000,0.000000) [0.000000|15.000000] "" Motor_BEV
 SG_ PSD_Attribut_1_Offset  : 40|7@1+ (2.000000,0.000000) [0.000000|254.000000] "Unit_Meter" Motor_BEV
 SG_ PSD_Attribut_2_ID  : 47|5@1+ (1.000000,0.000000) [1.000000|31.000000] "" Motor_BEV
 SG_ PSD_Attribut_2_Wert  : 52|4@1+ (1.000000,0.000000) [0.000000|15.000000] "" Motor_BEV
 SG_ PSD_Attribut_2_Offset  : 56|7@1+ (2.000000,0.000000) [0.000000|254.000000] "Unit_Meter" Motor_BEV
 SG_ PSD_Attribute_Komplett_05  : 63|1@1+ (1.000000,0.000000) [0.000000|1.000000] "" Motor_BEV

BO_ 1124 PSD_06: 8 ICAS1_Gateway
 SG_ PSD_06_Mux M : 0|3@1+ (1.000000,0.000000) [0.000000|7.000000] "" Motor_BEV
 SG_ PSD_Sys_Segment_ID m0 : 3|6@1+ (1.000000,0.000000) [2.000000|63.000000] "" Motor_BEV
 SG_ PSD_Attribut_Segment_ID m1 : 3|6@1+ (1.000000,0.000000) [2.000000|63.000000] "" Motor_BEV
 SG_ PSD_Ges_Segment_ID m2 : 3|6@1+ (1.000000,0.000000) [2.000000|63.000000] "" Motor_BEV
 SG_ PSD_Baum_Laenge_VZ m3 : 3|1@1+ (1.000000,0.000000) [0.000000|1.000000] "" Motor_BEV
 SG_ PSD_Steigung_1_Segment_ID m4 : 3|6@1+ (1.000000,0.000000) [2.000000|63.000000] "" Motor_BEV
 SG_ PSD_Baum_Laenge m3 : 4|25@1+ (0.000010,0.000000) [0.000000|180.000000] "Unit_DegreOfArc" Motor_BEV
 SG_ PSD_Sys_Laendercode m0 : 9|8@1+ (1.000000,0.000000) [0.000000|255.000000] "" Motor_BEV
 SG_ PSD_Attribut_3_ID m1 : 9|5@1+ (1.000000,0.000000) [1.000000|31.000000] "" Motor_BEV
 SG_ PSD_Ges_Offset m2 : 9|7@1+ (2.000000,0.000000) [0.000000|254.000000] "Unit_Meter" Motor_BEV
 SG_ PSD_Steigung_1_A_Steigung m4 : 9|7@1+ (0.120000,0.000000) [0.000000|15.000000] "Unit_PerCent" Motor_BEV
 SG_ PSD_Attribut_3_Offset m1 : 14|7@1+ (2.000000,0.000000) [0.000000|254.000000] "Unit_Meter" Motor_BEV
 SG_ PSD_Ges_Geschwindigkeit m2 : 16|5@1+ (1.000000,0.000000) [0.000000|31.000000] "" Motor_BEV
 SG_ PSD_Steigung_1_A_Vorz m4 : 16|1@1+ (1.000000,0.000000) [0.000000|1.000000] "" Motor_BEV
 SG_ PSD_Sys_Geschwindigkeit_Einheit m0 : 17|1@1+ (1.000000,0.000000) [0.000000|1.000000] "" Motor_BEV
 SG_ PSD_Steigung_1_A_Offset m4 : 17|7@1+ (2.000000,0.000000) [0.000000|254.000000] "Unit_Meter" Motor_BEV
 SG_ PSD_Sys_Verkehrsrichtung m0 : 18|1@1+ (1.000000,0.000000) [0.000000|1.000000] "" Motor_BEV
 SG_ PSD_Sys_Geometrieguete m0 : 19|2@1+ (1.000000,0.000000) [0.000000|3.000000] "" Motor_BEV
 SG_ PSD_Sys_Mapmatchingguete m0 : 21|2@1+ (1.000000,0.000000) [0.000000|3.000000] "" Motor_BEV
 SG_ PSD_Attribut_3_Wert m1 : 21|4@1+ (1.000000,0.000000) [0.000000|15.000000] "" Motor_BEV
 SG_ PSD_Ges_Typ m2 : 21|2@1+ (1.000000,0.000000) [0.000000|3.000000] "" Motor_BEV
 SG_ PSD_Sys_Alter_Karte m0 : 23|3@1+ (1.000000,0.000000) [0.000000|7.000000] "" Motor_BEV
 SG_ PSD_Ges_Spur_Geschw_Begrenzung m2 : 23|6@1+ (1.000000,0.000000) [0.000000|63.000000] "" Motor_BEV
 SG_ PSD_Steigung_1_B_Steigung m4 : 24|7@1+ (0.120000,0.000000) [0.000000|15.000000] "Unit_PerCent" Motor_BEV
 SG_ PSD_Attribut_4_ID m1 : 25|5@1+ (1.000000,0.000000) [1.000000|31.000000] "" Motor_BEV
 SG_ PSD_Sys_Zielfuehrung m0 : 26|1@1+ (1.000000,0.000000) [0.000000|1.000000] "" Motor_BEV
 SG_ PSD_Sys_US_State m0 : 27|6@1+ (1.000000,0.000000) [0.000000|63.000000] "" Motor_BEV
 SG_ PSD_Ges_Geschwindigkeit_Gespann m2 : 29|2@1+ (1.000000,0.000000) [0.000000|3.000000] "" Motor_BEV
 SG_ PSD_Baum_Breite_VZ m3 : 29|1@1+ (1.000000,0.000000) [0.000000|1.000000] "" Motor_BEV
 SG_ PSD_Attribut_4_Wert m1 : 30|4@1+ (1.000000,0.000000) [0.000000|15.000000] "" Motor_BEV
 SG_ PSD_Baum_Breite m3 : 30|24@1+ (0.000010,0.000000) [0.000000|90.000000] "Unit_DegreOfArc" Motor_BEV
 SG_ PSD_Ges_Geschwindigkeit_Witter m2 : 31|2@1+ (1.000000,0.000000) [0.000000|3.000000] "" Motor_BEV
 SG_ PSD_Steigung_1_B_Vorz m4 : 31|1@1+ (1.000000,0.000000) [0.000000|1.000000] "" Motor_BEV
 SG_ PSD_Steigung_1_B_Offset m4 : 32|7@1+ (2.000000,0.000000) [0.000000|254.000000] "Unit_Meter" Motor_BEV
 SG_ PSD_Sys_Quali_Geometrien m0 : 33|3@1+ (1.000000,0.000000) [0.000000|7.000000] "Unit_None" Vector__XXX
 SG_ PSD_Ges_Geschwindigkeit_Tag_Anf m2 : 33|3@1+ (1.000000,0.000000) [0.000000|7.000000] "" Motor_BEV
 SG_ PSD_Attribut_4_Offset m1 : 34|7@1+ (2.000000,0.000000) [0.000000|254.000000] "Unit_Meter" Motor_BEV
 SG_ PSD_Sys_Quali_Ortsinfo m0 : 36|2@1+ (1.000000,0.000000) [0.000000|3.000000] "Unit_None" Vector__XXX
 SG_ PSD_Ges_Geschwindigkeit_Tag_Ende m2 : 36|3@1+ (1.000000,0.000000) [0.000000|7.000000] "" Motor_BEV
 SG_ PSD_Sys_Quali_verfuegbar m0 : 38|1@1+ (1.000000,0.000000) [0.000000|1.000000] "" Vector__XXX
 SG_ PSD_Sys_Zielfuehrung_geaendert m0 : 39|1@1+ (1.000000,0.000000) [0.000000|1.000000] "" Motor_BEV
 SG_ PSD_Ges_Geschwindigkeit_Std_Anf m2 : 39|5@1+ (1.000000,0.000000) [0.000000|24.000000] "Unit_Hours" Motor_BEV
 SG_ PSD_Steigung_1_Attribute_kompl m4 : 39|1@1+ (1.000000,0.000000) [0.000000|1.000000] "" Motor_BEV
 SG_ PSD_Sys_Geometrieguete_erweitert m0 : 40|8@1+ (1.000000,0.000000) [0.000000|255.000000] "" Vector__XXX
 SG_ PSD_Steigung_2_Segment_ID m4 : 40|6@1+ (1.000000,0.000000) [2.000000|63.000000] "" Motor_BEV
 SG_ PSD_Attribut_5_ID m1 : 41|5@1+ (1.000000,0.000000) [1.000000|31.000000] "" Motor_BEV
 SG_ PSD_Ges_Geschwindigkeit_Std_Ende m2 : 44|5@1+ (1.000000,0.000000) [0.000000|24.000000] "Unit_Hours" Motor_BEV
 SG_ PSD_Attribut_5_Offset m1 : 46|7@1+ (2.000000,0.000000) [0.000000|254.000000] "Unit_Meter" Motor_BEV
 SG_ PSD_Steigung_2_Steigung m4 : 46|7@1+ (0.120000,0.000000) [0.000000|15.000000] "Unit_PerCent" Motor_BEV
 SG_ PSD_Sys_Quali_sonstige_Attribute m0 : 48|3@1+ (1.000000,0.000000) [0.000000|7.000000] "Unit_None" Vector__XXX
 SG_ PSD_Ges_Ueberholverbot m2 : 49|2@1+ (1.000000,0.000000) [0.000000|3.000000] "" Vector__XXX
 SG_ PSD_Sys_Quali_Steigungen m0 : 51|3@1+ (1.000000,0.000000) [0.000000|7.000000] "" Vector__XXX
 SG_ PSD_Ges_Wechselverkehrszeichen m2 : 51|3@1+ (1.000000,0.000000) [0.000000|7.000000] "" Vector__XXX
 SG_ PSD_Attribut_5_Wert m1 : 53|4@1+ (1.000000,0.000000) [0.000000|15.000000] "" Motor_BEV
 SG_ PSD_Steigung_2_Vorz m4 : 53|1@1+ (1.000000,0.000000) [0.000000|1.000000] "" Motor_BEV
 SG_ PSD_Sys_Quali_Strassenkennz m0 : 54|3@1+ (1.000000,0.000000) [0.000000|7.000000] "Unit_None" Vector__XXX
 SG_ PSD_Wechselverkehrszeichen_Typ m2 : 54|2@1+ (1.000000,0.000000) [0.000000|3.000000] "" Vector__XXX
 SG_ PSD_Baum_Ausrichtung m3 : 54|10@1+ (0.351562,0.000000) [0.000000|359.648438] "Unit_DegreOfArc" Vector__XXX
 SG_ PSD_Steigung_2_Offset m4 : 54|7@1+ (2.000000,0.000000) [0.000000|254.000000] "Unit_Meter" Motor_BEV
 SG_ PSD_Ges_Gesetzlich_Kategorie m2 : 56|3@1+ (1.000000,0.000000) [0.000000|7.000000] "" Motor_BEV
 SG_ PSD_Sys_Quali_Tempolimits m0 : 57|3@1+ (1.000000,0.000000) [0.000000|7.000000] "Unit_None" Vector__XXX
 SG_ PSD_Attribute_Komplett_06 m1 : 57|1@1+ (1.000000,0.000000) [0.000000|1.000000] "" Motor_BEV
 SG_ PSD_Ges_Gesetzlich_Zusatz m2 : 59|2@1+ (1.000000,0.000000) [0.000000|3.000000] "" Motor_BEV
 SG_ PSD_Sys_Quali_Vorfahrtsregelung m0 : 60|3@1+ (1.000000,0.000000) [0.000000|7.000000] "Unit_None" Vector__XXX
 SG_ PSD_Ges_Verkehrszeichen_Quelle m2 : 61|2@1+ (1.000000,0.000000) [0.000000|3.000000] "" Motor_BEV
 SG_ PSD_Steigung_2_Attribute_kompl m4 : 61|1@1+ (1.000000,0.000000) [0.000000|1.000000] "" Motor_BEV
 SG_ PSD_Ges_Attribute_Komplett m2 : 63|1@1+ (1.000000,0.000000) [0.000000|1.000000] "" Motor_BEV

BO_ 591 RDR1_Objekte_02: 64 ICAS1_Gateway
 SG_ RDR1_relevanter_Fehler  : 12|1@1+ (1.000000,0.000000) [0.000000|1.000000] "" Motor_BEV
 SG_ RDR1_Blindheit_erkannt  : 13|1@1+ (1.000000,0.000000) [0.000000|1.000000] "" Motor_BEV
 SG_ RDR1_relev_Nichtverfuegbarkeit  : 14|1@1+ (1.000000,0.000000) [0.000000|1.000000] "" Motor_BEV
 SG_ RDR1_Obj_01_Nummer  : 16|6@1+ (1.000000,0.000000) [0.000000|63.000000] "" Vector__XXX
 SG_ RDR1_Obj_02_Nummer  : 22|6@1+ (1.000000,0.000000) [0.000000|63.000000] "" Vector__XXX
 SG_ RDR1_Obj_03_Nummer  : 28|6@1+ (1.000000,0.000000) [0.000000|63.000000] "" Vector__XXX
 SG_ RDR1_Obj_04_Nummer  : 34|6@1+ (1.000000,0.000000) [0.000000|63.000000] "" Vector__XXX
 SG_ RDR1_Obj_05_Nummer  : 40|6@1+ (1.000000,0.000000) [0.000000|63.000000] "" Vector__XXX
 SG_ RDR1_Obj_06_Nummer  : 46|6@1+ (1.000000,0.000000) [0.000000|63.000000] "" Vector__XXX
 SG_ RDR1_Verkehrssinn  : 52|2@1+ (1.000000,0.000000) [0.000000|3.000000] "" Vector__XXX
 SG_ RDR1_Objekte_02_Datenalter  : 54|10@1+ (0.000977,0.000000) [0.000000|0.998047] "Unit_Secon" Vector__XXX
 SG_ RDR1_Obj_01_dx_v  : 64|12@1+ (0.062500,0.000000) [0.000000|255.937500] "Unit_Meter" Motor_BEV
 SG_ RDR1_Obj_01_dy_v  : 76|10@1+ (0.062500,-32.000000) [-32.000000|31.937500] "Unit_Meter" Motor_BEV
 SG_ RDR1_Obj_01_vx_v  : 86|10@1+ (0.250000,-128.000000) [-128.000000|127.750000] "Unit_MeterPerSecon" Motor_BEV
 SG_ RDR1_Obj_02_dx_v  : 96|12@1+ (0.062500,0.000000) [0.000000|255.937500] "Unit_Meter" Vector__XXX
 SG_ RDR1_Obj_02_dy_v  : 108|10@1+ (0.062500,-32.000000) [-32.000000|31.937500] "Unit_Meter" Vector__XXX
 SG_ RDR1_Obj_02_vx_v  : 118|10@1+ (0.250000,-128.000000) [-128.000000|127.750000] "Unit_MeterPerSecon" Vector__XXX
 SG_ RDR1_Obj_03_dx_v  : 128|12@1+ (0.062500,0.000000) [0.000000|255.937500] "Unit_Meter" Vector__XXX
 SG_ RDR1_Obj_03_dy_v  : 140|10@1+ (0.062500,-32.000000) [-32.000000|31.937500] "Unit_Meter" Vector__XXX
 SG_ RDR1_Obj_03_vx_v  : 150|10@1+ (0.250000,-128.000000) [-128.000000|127.750000] "Unit_MeterPerSecon" Vector__XXX
 SG_ RDR1_Obj_04_dx_v  : 160|12@1+ (0.062500,0.000000) [0.000000|255.937500] "Unit_Meter" Motor_BEV
 SG_ RDR1_Obj_04_dy_v  : 172|10@1+ (0.062500,-32.000000) [-32.000000|31.937500] "Unit_Meter" Vector__XXX
 SG_ RDR1_Obj_04_vx_v  : 182|10@1+ (0.250000,-128.000000) [-128.000000|127.750000] "Unit_MeterPerSecon" Motor_BEV
 SG_ RDR1_Obj_05_dx_v  : 192|12@1+ (0.062500,0.000000) [0.000000|255.937500] "Unit_Meter" Vector__XXX
 SG_ RDR1_Obj_05_dy_v  : 204|10@1+ (0.062500,-32.000000) [-32.000000|31.937500] "Unit_Meter" Vector__XXX
 SG_ RDR1_Obj_05_vx_v  : 214|10@1+ (0.250000,-128.000000) [-128.000000|127.750000] "Unit_MeterPerSecon" Vector__XXX
 SG_ RDR1_Obj_06_dx_v  : 224|12@1+ (0.062500,0.000000) [0.000000|255.937500] "Unit_Meter" Vector__XXX
 SG_ RDR1_Obj_06_dy_v  : 236|10@1+ (0.062500,-32.000000) [-32.000000|31.937500] "Unit_Meter" Vector__XXX
 SG_ RDR1_Obj_06_vx_v  : 246|10@1+ (0.250000,-128.000000) [-128.000000|127.750000] "Unit_MeterPerSecon" Vector__XXX
 SG_ RDR1_Obj_01_ax_v  : 256|8@1+ (0.125000,-16.000000) [-16.000000|15.750000] "Unit_MeterPerSeconSquar" Motor_BEV
 SG_ RDR1_Obj_01_ax_StdA  : 264|6@1+ (0.125000,0.000000) [0.000000|7.750000] "Unit_MeterPerSeconSquar" Motor_BEV
 SG_ RDR1_Obj_01_vx_StdA  : 270|7@1+ (0.031250,0.000000) [0.000000|3.937500] "Unit_MeterPerSecon" Motor_BEV
 SG_ RDR1_Obj_01_dx_StdA  : 277|7@1+ (0.050000,0.000000) [0.000000|6.300000] "Unit_Meter" Motor_BEV
 SG_ RDR1_Obj_01_dy_StdA  : 284|7@1+ (0.062500,0.000000) [0.000000|7.875000] "Unit_Meter" Motor_BEV

BO_ 2033 Request_Airbag_Deployment: 8 ICAS1_Gateway
 SG_ Request_Airbag_Deployment  : 0|64@1+ (1.000000,0.000000) [0.000000|18446744073709551616.000000] "" Airbag

BO_ 2041 Response_Airbag_Deployment: 8 Airbag
 SG_ Response_Airbag_Deployment  : 0|64@1+ (1.000000,0.000000) [0.000000|18446744073709551616.000000] "" ICAS1_Gateway

BO_ 980 SMLS_01: 8 ICAS1_Gateway
 SG_ SMLS_01_CRC  : 0|8@1+ (1.000000,0.000000) [0.000000|255.000000] "" Vector__XXX
 SG_ SMLS_01_BZ  : 8|4@1+ (1.000000,0.000000) [0.000000|15.000000] "" Vector__XXX
 SG_ BH_Blinker_li  : 12|1@1+ (1.000000,0.000000) [0.000000|1.000000] "" Motor_BEV
 SG_ BH_Blinker_re  : 13|1@1+ (1.000000,0.000000) [0.000000|1.000000] "" Motor_BEV
 SG_ BH_Lichthupe  : 14|1@1+ (1.000000,0.000000) [0.000000|1.000000] "" Vector__XXX
 SG_ BH_Fernlicht  : 15|1@1+ (1.000000,0.000000) [0.000000|1.000000] "" Vector__XXX
 SG_ WH_Tipwischen  : 16|1@1+ (1.000000,0.000000) [0.000000|1.000000] "" Vector__XXX
 SG_ WH_Intervall  : 17|1@1+ (1.000000,0.000000) [0.000000|1.000000] "" Vector__XXX
 SG_ WH_WischerStufe1  : 18|1@1+ (1.000000,0.000000) [0.000000|1.000000] "" Vector__XXX
 SG_ WH_WischerStufe2  : 19|1@1+ (1.000000,0.000000) [0.000000|1.000000] "" Vector__XXX
 SG_ WH_Frontwaschen  : 20|1@1+ (1.000000,0.000000) [0.000000|1.000000] "" Vector__XXX
 SG_ WH_Heckintervall  : 21|1@1+ (1.000000,0.000000) [0.000000|1.000000] "" Vector__XXX
 SG_ WH_Heckwaschen  : 22|1@1+ (1.000000,0.000000) [0.000000|1.000000] "" Vector__XXX
 SG_ WH_Intervallstufen  : 23|4@1+ (1.000000,0.000000) [0.000000|15.000000] "" Vector__XXX
 SG_ FAS_Taster  : 27|1@1+ (1.000000,0.000000) [0.000000|1.000000] "" Vector__XXX
 SG_ FAS_Taster_Fehler  : 28|1@1+ (1.000000,0.000000) [0.000000|1.000000] "" Vector__XXX
 SG_ SMLS_Hupe  : 29|1@1+ (1.000000,0.000000) [0.000000|1.000000] "" Vector__XXX
 SG_ LRH_on_off  : 30|2@1+ (1.000000,0.000000) [0.000000|3.000000] "" Vector__XXX
 SG_ LSS_Tastencode  : 32|8@1+ (1.000000,0.000000) [0.000000|255.000000] "" Vector__XXX
 SG_ LRH_aktiv  : 40|1@1+ (1.000000,0.000000) [0.000000|1.000000] "" Vector__XXX
 SG_ SMLS_P_verriegelt  : 41|2@1+ (1.000000,0.000000) [0.000000|3.000000] "" Vector__XXX
 SG_ SMLS_P_verriegelt_plausibel  : 43|1@1+ (1.000000,0.000000) [0.000000|1.000000] "" Vector__XXX
 SG_ WH_SRA  : 44|1@1+ (1.000000,0.000000) [0.000000|1.000000] "" Vector__XXX
 SG_ WH_Wischer_Fehler  : 45|1@1+ (1.000000,0.000000) [0.000000|1.000000] "" Vector__XXX
 SG_ BH_Blinker_Fehler  : 46|1@1+ (1.000000,0.000000) [0.000000|1.000000] "" Vector__XXX
 SG_ SMLS_PTT  : 47|1@1+ (1.000000,0.000000) [0.000000|1.000000] "" Vector__XXX
 SG_ WH_Tipwischen_lang  : 48|1@1+ (1.000000,0.000000) [0.000000|1.000000] "" Vector__XXX

BO_ 2464153718 SOK_FoD_MO_01_Req_Chal_01: 8 Motor_BEV
 SG_ SOK_FoD_MO_01_Req_Challenge  : 0|64@1+ (1.000000,0.000000) [0.000000|18446744073709551616.000000] "Unit_None" ICAS1_Gateway

BO_ 2464284790 SOK_FoD_MO_01_Resp_Chal_01: 8 ICAS1_Gateway
 SG_ SOK_FoD_MO_01_Resp_Challenge  : 0|64@1+ (1.000000,0.000000) [0.000000|18446744073709551616.000000] "Unit_None" Motor_BEV

BO_ 1413 Systeminfo_01: 8 ICAS1_Gateway
 SG_ SI_Sammel_SG_Fehler  : 0|6@1+ (1.000000,0.000000) [0.000000|60.000000] "" Vector__XXX
 SG_ SI_P_Mode_gueltig  : 6|1@1+ (1.000000,0.000000) [0.000000|1.000000] "" Vector__XXX
 SG_ SI_Diagnose_Aktiv  : 7|1@1+ (1.000000,0.000000) [0.000000|1.000000] "" Vector__XXX
 SG_ SI_QRS_Mode  : 8|1@1+ (1.000000,0.000000) [0.000000|1.000000] "" Airbag Motor_BEV
 SG_ SI_T_Mode  : 9|1@1+ (1.000000,0.000000) [0.000000|1.000000] "" Motor_BEV
 SG_ SI_NWDF  : 10|1@1+ (1.000000,0.000000) [0.000000|1.000000] "" Vector__XXX
 SG_ SI_NWDF_gueltig  : 11|1@1+ (1.000000,0.000000) [0.000000|1.000000] "" Vector__XXX
 SG_ SI_Sammelfehler  : 12|1@1+ (1.000000,0.000000) [0.000000|1.000000] "" Vector__XXX
 SG_ GW_KD_Fehler  : 13|1@1+ (1.000000,0.000000) [0.000000|1.000000] "" Vector__XXX
 SG_ SI_T_Schutz  : 14|1@1+ (1.000000,0.000000) [0.000000|1.000000] "" Motor_BEV
 SG_ SI_P_Mode  : 15|1@1+ (1.000000,0.000000) [0.000000|1.000000] "" Vector__XXX
 SG_ SI_BUS_01  : 16|1@1+ (1.000000,0.000000) [0.000000|1.000000] "" Vector__XXX
 SG_ SI_BUS_02  : 17|1@1+ (1.000000,0.000000) [0.000000|1.000000] "" Vector__XXX
 SG_ SI_BUS_03  : 18|1@1+ (1.000000,0.000000) [0.000000|1.000000] "" Vector__XXX
 SG_ SI_BUS_04  : 19|1@1+ (1.000000,0.000000) [0.000000|1.000000] "" Vector__XXX
 SG_ SI_BUS_05  : 20|1@1+ (1.000000,0.000000) [0.000000|1.000000] "" Vector__XXX
 SG_ SI_BUS_06  : 21|1@1+ (1.000000,0.000000) [0.000000|1.000000] "" Vector__XXX
 SG_ SI_BUS_07  : 22|1@1+ (1.000000,0.000000) [0.000000|1.000000] "" Vector__XXX
 SG_ SI_BUS_08  : 23|1@1+ (1.000000,0.000000) [0.000000|1.000000] "" Vector__XXX
 SG_ SI_BUS_09  : 24|1@1+ (1.000000,0.000000) [0.000000|1.000000] "" Vector__XXX
 SG_ SI_BUS_10  : 25|1@1+ (1.000000,0.000000) [0.000000|1.000000] "" Vector__XXX
 SG_ SI_BUS_11  : 26|1@1+ (1.000000,0.000000) [0.000000|1.000000] "" Vector__XXX
 SG_ SI_BUS_12  : 27|1@1+ (1.000000,0.000000) [0.000000|1.000000] "" Vector__XXX
 SG_ SI_BUS_13  : 28|1@1+ (1.000000,0.000000) [0.000000|1.000000] "" Vector__XXX
 SG_ SI_BUS_14  : 29|1@1+ (1.000000,0.000000) [0.000000|1.000000] "" Vector__XXX
 SG_ SI_BUS_15  : 30|1@1+ (1.000000,0.000000) [0.000000|1.000000] "" Vector__XXX
 SG_ SI_Bus_Identifikation  : 32|8@1+ (1.000000,0.000000) [0.000000|255.000000] "" Vector__XXX
 SG_ SI_CAB_V10  : 40|24@1+ (1.000000,0.000000) [0.000000|16777215.000000] "" Vector__XXX

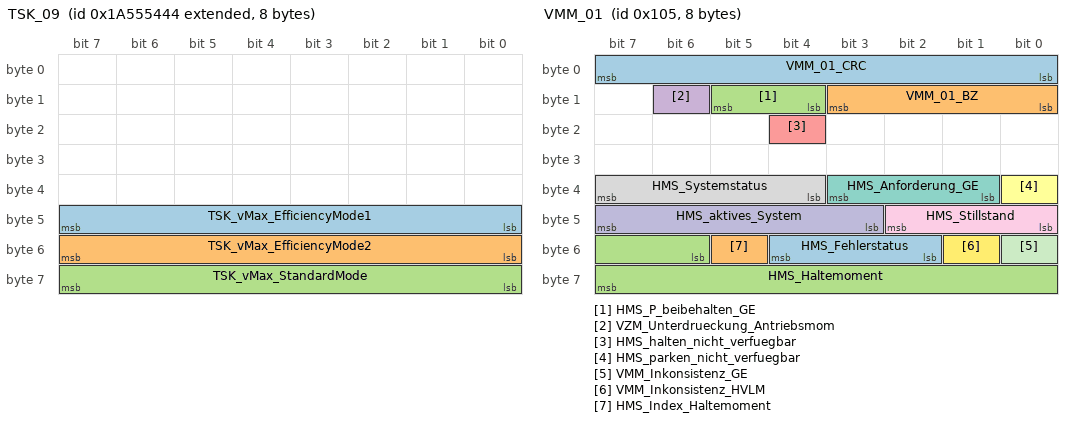
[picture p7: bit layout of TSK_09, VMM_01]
BO_ 2589283396 TSK_09: 8 Motor_BEV
 SG_ TSK_vMax_EfficiencyMode1  : 40|8@1+ (1.000000,0.000000) [0.000000|253.000000] "Unit_KiloMeterPerHour" ICAS1_Gateway
 SG_ TSK_vMax_EfficiencyMode2  : 48|8@1+ (1.000000,0.000000) [0.000000|253.000000] "Unit_KiloMeterPerHour" ICAS1_Gateway
 SG_ TSK_vMax_StandardMode  : 56|8@1+ (1.000000,0.000000) [0.000000|253.000000] "Unit_KiloMeterPerHour" ICAS1_Gateway

BO_ 1019 TSK_Ausrollkurve_01: 8 Motor_BEV
 SG_ TSK_Ausrollkurve_Schub_Reku_01 m0 : 0|7@1+ (2.000000,0.000000) [0.000000|252.000000] "Unit_KiloMeterPerHour" ICAS1_Gateway
 SG_ TSK_Ausrollkurve_Schub_Reku_05 m1 : 0|7@1+ (2.000000,0.000000) [0.000000|252.000000] "Unit_KiloMeterPerHour" ICAS1_Gateway
 SG_ TSK_Ausrollkurve_Schub_Reku_09 m2 : 0|7@1+ (2.000000,0.000000) [0.000000|252.000000] "Unit_KiloMeterPerHour" ICAS1_Gateway
 SG_ TSK_Ausrollkurve_Schub_Reku_13 m3 : 0|7@1+ (2.000000,0.000000) [0.000000|252.000000] "Unit_KiloMeterPerHour" ICAS1_Gateway
 SG_ TSK_Ausrollkurve_Schub_Reku_17 m4 : 0|7@1+ (2.000000,0.000000) [0.000000|252.000000] "Unit_KiloMeterPerHour" ICAS1_Gateway
 SG_ TSK_Ausrollkurve_Schub_Reku_02 m0 : 7|7@1+ (2.000000,0.000000) [0.000000|252.000000] "Unit_KiloMeterPerHour" ICAS1_Gateway
 SG_ TSK_Ausrollkurve_Schub_Reku_06 m1 : 7|7@1+ (2.000000,0.000000) [0.000000|252.000000] "Unit_KiloMeterPerHour" ICAS1_Gateway
 SG_ TSK_Ausrollkurve_Schub_Reku_10 m2 : 7|7@1+ (2.000000,0.000000) [0.000000|252.000000] "Unit_KiloMeterPerHour" ICAS1_Gateway
 SG_ TSK_Ausrollkurve_Schub_Reku_14 m3 : 7|7@1+ (2.000000,0.000000) [0.000000|252.000000] "Unit_KiloMeterPerHour" ICAS1_Gateway
 SG_ TSK_Ausrollkurve_Schub_Reku_18 m4 : 7|7@1+ (2.000000,0.000000) [0.000000|252.000000] "Unit_KiloMeterPerHour" ICAS1_Gateway
 SG_ TSK_Ausrollkurve_Schub_Reku_03 m0 : 14|7@1+ (2.000000,0.000000) [0.000000|252.000000] "Unit_KiloMeterPerHour" ICAS1_Gateway
 SG_ TSK_Ausrollkurve_Schub_Reku_07 m1 : 14|7@1+ (2.000000,0.000000) [0.000000|252.000000] "Unit_KiloMeterPerHour" ICAS1_Gateway
 SG_ TSK_Ausrollkurve_Schub_Reku_11 m2 : 14|7@1+ (2.000000,0.000000) [0.000000|252.000000] "Unit_KiloMeterPerHour" ICAS1_Gateway
 SG_ TSK_Ausrollkurve_Schub_Reku_15 m3 : 14|7@1+ (2.000000,0.000000) [0.000000|252.000000] "Unit_KiloMeterPerHour" ICAS1_Gateway
 SG_ TSK_Ausrollkurve_Schub_Reku_19 m4 : 14|7@1+ (2.000000,0.000000) [0.000000|252.000000] "Unit_KiloMeterPerHour" ICAS1_Gateway
 SG_ TSK_Ausrollkurve_Schub_Reku_04 m0 : 21|7@1+ (2.000000,0.000000) [0.000000|252.000000] "Unit_KiloMeterPerHour" ICAS1_Gateway
 SG_ TSK_Ausrollkurve_Schub_Reku_08 m1 : 21|7@1+ (2.000000,0.000000) [0.000000|252.000000] "Unit_KiloMeterPerHour" ICAS1_Gateway
 SG_ TSK_Ausrollkurve_Schub_Reku_12 m2 : 21|7@1+ (2.000000,0.000000) [0.000000|252.000000] "Unit_KiloMeterPerHour" ICAS1_Gateway
 SG_ TSK_Ausrollkurve_Schub_Reku_16 m3 : 21|7@1+ (2.000000,0.000000) [0.000000|252.000000] "Unit_KiloMeterPerHour" ICAS1_Gateway
 SG_ TSK_Ausrollkurve_Schub_Reku_20 m4 : 21|7@1+ (2.000000,0.000000) [0.000000|252.000000] "Unit_KiloMeterPerHour" ICAS1_Gateway
 SG_ TSK_Ausrollkurve_Segeln_01 m0 : 28|7@1+ (2.000000,0.000000) [0.000000|252.000000] "Unit_KiloMeterPerHour" ICAS1_Gateway
 SG_ TSK_Ausrollkurve_Segeln_05 m1 : 28|7@1+ (2.000000,0.000000) [0.000000|252.000000] "Unit_KiloMeterPerHour" ICAS1_Gateway
 SG_ TSK_Ausrollkurve_Segeln_09 m2 : 28|7@1+ (2.000000,0.000000) [0.000000|252.000000] "Unit_KiloMeterPerHour" ICAS1_Gateway
 SG_ TSK_Ausrollkurve_Segeln_13 m3 : 28|7@1+ (2.000000,0.000000) [0.000000|252.000000] "Unit_KiloMeterPerHour" ICAS1_Gateway
 SG_ TSK_Ausrollkurve_Segeln_17 m4 : 28|7@1+ (2.000000,0.000000) [0.000000|252.000000] "Unit_KiloMeterPerHour" ICAS1_Gateway
 SG_ TSK_Ausrollkurve_Segeln_02 m0 : 35|7@1+ (2.000000,0.000000) [0.000000|252.000000] "Unit_KiloMeterPerHour" ICAS1_Gateway
 SG_ TSK_Ausrollkurve_Segeln_06 m1 : 35|7@1+ (2.000000,0.000000) [0.000000|252.000000] "Unit_KiloMeterPerHour" ICAS1_Gateway
 SG_ TSK_Ausrollkurve_Segeln_10 m2 : 35|7@1+ (2.000000,0.000000) [0.000000|252.000000] "Unit_KiloMeterPerHour" ICAS1_Gateway
 SG_ TSK_Ausrollkurve_Segeln_14 m3 : 35|7@1+ (2.000000,0.000000) [0.000000|252.000000] "Unit_KiloMeterPerHour" ICAS1_Gateway
 SG_ TSK_Ausrollkurve_Segeln_18 m4 : 35|7@1+ (2.000000,0.000000) [0.000000|252.000000] "Unit_KiloMeterPerHour" ICAS1_Gateway
 SG_ TSK_Ausrollkurve_Segeln_03 m0 : 42|7@1+ (2.000000,0.000000) [0.000000|252.000000] "Unit_KiloMeterPerHour" ICAS1_Gateway
 SG_ TSK_Ausrollkurve_Segeln_07 m1 : 42|7@1+ (2.000000,0.000000) [0.000000|252.000000] "Unit_KiloMeterPerHour" ICAS1_Gateway
 SG_ TSK_Ausrollkurve_Segeln_11 m2 : 42|7@1+ (2.000000,0.000000) [0.000000|252.000000] "Unit_KiloMeterPerHour" ICAS1_Gateway
 SG_ TSK_Ausrollkurve_Segeln_15 m3 : 42|7@1+ (2.000000,0.000000) [0.000000|252.000000] "Unit_KiloMeterPerHour" ICAS1_Gateway
 SG_ TSK_Ausrollkurve_Segeln_19 m4 : 42|7@1+ (2.000000,0.000000) [0.000000|252.000000] "Unit_KiloMeterPerHour" ICAS1_Gateway
 SG_ TSK_Ausrollkurve_Segeln_04 m0 : 49|7@1+ (2.000000,0.000000) [0.000000|252.000000] "Unit_KiloMeterPerHour" ICAS1_Gateway
 SG_ TSK_Ausrollkurve_Segeln_08 m1 : 49|7@1+ (2.000000,0.000000) [0.000000|252.000000] "Unit_KiloMeterPerHour" ICAS1_Gateway
 SG_ TSK_Ausrollkurve_Segeln_12 m2 : 49|7@1+ (2.000000,0.000000) [0.000000|252.000000] "Unit_KiloMeterPerHour" ICAS1_Gateway
 SG_ TSK_Ausrollkurve_Segeln_16 m3 : 49|7@1+ (2.000000,0.000000) [0.000000|252.000000] "Unit_KiloMeterPerHour" ICAS1_Gateway
 SG_ TSK_Ausrollkurve_Segeln_20 m4 : 49|7@1+ (2.000000,0.000000) [0.000000|252.000000] "Unit_KiloMeterPerHour" ICAS1_Gateway
 SG_ TSK_Ausrollkurve_Mux M : 56|3@1+ (1.000000,0.000000) [0.000000|7.000000] "" ICAS1_Gateway
 SG_ TSK_Ausrollkurve_Reku  : 59|1@1+ (1.000000,0.000000) [0.000000|1.000000] "" ICAS1_Gateway
 SG_ TSK_Ausrollkurve_Schrittweite  : 60|1@1+ (1.000000,0.000000) [0.000000|1.000000] "" ICAS1_Gateway
 SG_ TSK_Ausrollkurve_Zaehler  : 61|2@1+ (1.000000,0.000000) [0.000000|3.000000] "" ICAS1_Gateway

BO_ 1716 VIN_01: 8 ICAS1_Gateway
 SG_ VIN_01_MUX M : 0|2@1+ (1.000000,0.000000) [0.000000|3.000000] "" Airbag Motor_BEV
 SG_ KS_Geheimnis_1 m0 : 8|8@1+ (1.000000,0.000000) [0.000000|255.000000] "" Airbag
 SG_ VIN_4 m1 : 8|8@1+ (1.000000,0.000000) [0.000000|255.000000] "" Airbag Motor_BEV
 SG_ VIN_11 m2 : 8|8@1+ (1.000000,0.000000) [0.000000|255.000000] "" Airbag Motor_BEV
 SG_ KS_Geheimnis_2 m0 : 16|8@1+ (1.000000,0.000000) [0.000000|255.000000] "" Airbag
 SG_ VIN_5 m1 : 16|8@1+ (1.000000,0.000000) [0.000000|255.000000] "" Airbag Motor_BEV
 SG_ VIN_12 m2 : 16|8@1+ (1.000000,0.000000) [0.000000|255.000000] "" Airbag Motor_BEV
 SG_ KS_Geheimnis_3 m0 : 24|8@1+ (1.000000,0.000000) [0.000000|255.000000] "" Airbag
 SG_ VIN_6 m1 : 24|8@1+ (1.000000,0.000000) [0.000000|255.000000] "" Airbag Motor_BEV
 SG_ VIN_13 m2 : 24|8@1+ (1.000000,0.000000) [0.000000|255.000000] "" Airbag Motor_BEV
 SG_ KS_Geheimnis_4 m0 : 32|8@1+ (1.000000,0.000000) [0.000000|255.000000] "" Airbag
 SG_ VIN_7 m1 : 32|8@1+ (1.000000,0.000000) [0.000000|255.000000] "" Airbag Motor_BEV
 SG_ VIN_14 m2 : 32|8@1+ (1.000000,0.000000) [0.000000|255.000000] "" Airbag Motor_BEV
 SG_ VIN_1 m0 : 40|8@1+ (1.000000,0.000000) [0.000000|255.000000] "" Airbag Motor_BEV
 SG_ VIN_8 m1 : 40|8@1+ (1.000000,0.000000) [0.000000|255.000000] "" Airbag Motor_BEV
 SG_ VIN_15 m2 : 40|8@1+ (1.000000,0.000000) [0.000000|255.000000] "" Airbag Motor_BEV
 SG_ VIN_2 m0 : 48|8@1+ (1.000000,0.000000) [0.000000|255.000000] "" Airbag Motor_BEV
 SG_ VIN_9 m1 : 48|8@1+ (1.000000,0.000000) [0.000000|255.000000] "" Airbag Motor_BEV
 SG_ VIN_16 m2 : 48|8@1+ (1.000000,0.000000) [0.000000|255.000000] "" Airbag Motor_BEV
 SG_ VIN_3 m0 : 56|8@1+ (1.000000,0.000000) [0.000000|255.000000] "" Airbag Motor_BEV
 SG_ VIN_10 m1 : 56|8@1+ (1.000000,0.000000) [0.000000|255.000000] "" Airbag Motor_BEV
 SG_ VIN_17 m2 : 56|8@1+ (1.000000,0.000000) [0.000000|255.000000] "" Airbag Motor_BEV

BO_ 261 VMM_01: 8 ICAS1_Gateway
 SG_ VMM_01_CRC  : 0|8@1+ (1.000000,0.000000) [0.000000|255.000000] "" Motor_BEV
 SG_ VMM_01_BZ  : 8|4@1+ (1.000000,0.000000) [0.000000|15.000000] "" Motor_BEV
 SG_ HMS_P_beibehalten_GE  : 12|2@1+ (1.000000,0.000000) [0.000000|3.000000] "" Vector__XXX
 SG_ VZM_Unterdrueckung_Antriebsmom  : 14|1@1+ (1.000000,0.000000) [0.000000|1.000000] "" Airbag Motor_BEV
 SG_ HMS_halten_nicht_verfuegbar  : 20|1@1+ (1.000000,0.000000) [0.000000|1.000000] "" Vector__XXX
 SG_ HMS_parken_nicht_verfuegbar  : 32|1@1+ (1.000000,0.000000) [0.000000|1.000000] "" Vector__XXX
 SG_ HMS_Anforderung_GE  : 33|3@1+ (1.000000,0.000000) [0.000000|7.000000] "" Vector__XXX
 SG_ HMS_Systemstatus  : 36|4@1+ (1.000000,0.000000) [0.000000|15.000000] "" Motor_BEV
 SG_ HMS_Stillstand  : 40|3@1+ (1.000000,0.000000) [0.000000|7.000000] "" Motor_BEV
 SG_ HMS_aktives_System  : 43|5@1+ (1.000000,0.000000) [0.000000|31.000000] "" Motor_BEV
 SG_ VMM_Inkonsistenz_GE  : 48|1@1+ (1.000000,0.000000) [0.000000|1.000000] "" Motor_BEV
 SG_ VMM_Inkonsistenz_HVLM  : 49|1@1+ (1.000000,0.000000) [0.000000|1.000000] "" Motor_BEV
 SG_ HMS_Fehlerstatus  : 50|3@1+ (1.000000,0.000000) [0.000000|7.000000] "" Vector__XXX
 SG_ HMS_Index_Haltemoment  : 53|1@1+ (1.000000,0.000000) [0.000000|1.000000] "" Motor_BEV
 SG_ HMS_Haltemoment  : 54|10@1+ (10.000000,0.000000) [0.000000|10210.000000] "Unit_NewtoMeter" Motor_BEV

BO_ 313 VMM_02: 32 ICAS1_Gateway
 SG_ VMM_02_CRC  : 0|8@1+ (1.000000,0.000000) [0.000000|255.000000] "" Motor_BEV
 SG_ VMM_02_BZ  : 8|4@1+ (1.000000,0.000000) [0.000000|15.000000] "" Motor_BEV
 SG_ VZM_aktiver_Basisservice  : 12|3@1+ (1.000000,0.000000) [0.000000|7.000000] "" Motor_BEV
 SG_ VZM_Anhalteweg_nicht_verfuegbar  : 15|1@1+ (1.000000,0.000000) [0.000000|1.000000] "" Motor_BEV
 SG_ VZM_Fahrer_bremst  : 16|1@1+ (1.000000,0.000000) [0.000000|1.000000] "" Motor_BEV
 SG_ VZM_QBit_Fahrer_bremst  : 17|1@1+ (1.000000,0.000000) [0.000000|1.000000] "" Motor_BEV
 SG_ VMM_MKB_codiert  : 18|1@1+ (1.000000,0.000000) [0.000000|1.000000] "" Airbag
 SG_ VMM_Inkonsistenz_EBKV  : 19|1@1+ (1.000000,0.000000) [0.000000|1.000000] "" Vector__XXX
 SG_ VMM_Notstopp_Status  : 20|3@1+ (1.000000,0.000000) [0.000000|7.000000] "" Motor_BEV
 SG_ VZM_Warnruck_nicht_verfuegbar  : 23|1@1+ (1.000000,0.000000) [0.000000|1.000000] "" Motor_BEV
 SG_ VZM_Warnruckeln_nicht_verfuegbar  : 24|1@1+ (1.000000,0.000000) [0.000000|1.000000] "" Motor_BEV
 SG_ VZM_Bkd_nicht_verfuegbar  : 25|1@1+ (1.000000,0.000000) [0.000000|1.000000] "" Motor_BEV
 SG_ VMM_Bremslicht_defekt  : 26|1@1+ (1.000000,0.000000) [0.000000|1.000000] "" Motor_BEV
 SG_ VZM_Fahrer_bremst_deutlich  : 27|1@1+ (1.000000,0.000000) [0.000000|1.000000] "" Airbag Motor_BEV
 SG_ VZM_TSK_SRBM_Anf  : 28|1@1+ (1.000000,0.000000) [0.000000|1.000000] "" Motor_BEV
 SG_ VZM_TSK_SRBM_nicht_verfuegbar  : 29|1@1+ (1.000000,0.000000) [0.000000|1.000000] "" Motor_BEV
 SG_ VZM_Verz_Reg_aktiv  : 30|5@1+ (1.000000,0.000000) [0.000000|31.000000] "" Motor_BEV
 SG_ VZM_Verz_Reg_nicht_verfuegbar  : 35|1@1+ (1.000000,0.000000) [0.000000|1.000000] "" Motor_BEV
 SG_ VMM_Inkonsistenz_KAS  : 36|1@1+ (1.000000,0.000000) [0.000000|1.000000] "" Motor_BEV
 SG_ VMM_Bremslicht_unplausibel  : 37|1@1+ (1.000000,0.000000) [0.000000|1.000000] "" Motor_BEV
 SG_ VMM_Inkonsistenz_ACC  : 38|1@1+ (1.000000,0.000000) [0.000000|1.000000] "" Motor_BEV
 SG_ VMM_Inkonsistenz_AWV_PCF  : 39|1@1+ (1.000000,0.000000) [0.000000|1.000000] "" Motor_BEV
 SG_ VMM_Inkonsistenz_ARA  : 40|1@1+ (1.000000,0.000000) [0.000000|1.000000] "" Motor_BEV
 SG_ VMM_Inkonsistenz_ParkAssist  : 41|1@1+ (1.000000,0.000000) [0.000000|1.000000] "" Motor_BEV
 SG_ VMM_Inkonsistenz_FAS_VK  : 42|1@1+ (1.000000,0.000000) [0.000000|1.000000] "" Motor_BEV
 SG_ VMM_Inkonsistenz_NV  : 43|1@1+ (1.000000,0.000000) [0.000000|1.000000] "" Motor_BEV
 SG_ VMM_Inkonsistenz_RCTA  : 44|1@1+ (1.000000,0.000000) [0.000000|1.000000] "" Motor_BEV
 SG_ VMM_Inkonsistenz_TSK  : 45|1@1+ (1.000000,0.000000) [0.000000|1.000000] "" Motor_BEV
 SG_ VMM_Inkonsistenz_MO  : 46|1@1+ (1.000000,0.000000) [0.000000|1.000000] "" Motor_BEV
 SG_ VMM_Inkonsistenz_AEB  : 47|1@1+ (1.000000,0.000000) [0.000000|1.000000] "" Vector__XXX
 SG_ VMM_Fahrer_Bremskraft_bestimmend  : 48|1@1+ (1.000000,0.000000) [0.000000|1.000000] "" Motor_BEV
 SG_ VMM_Inkonsistenz_EA  : 49|1@1+ (1.000000,0.000000) [0.000000|1.000000] "" Motor_BEV
 SG_ VZM_Status_Wegregelung  : 50|2@1+ (1.000000,0.000000) [0.000000|3.000000] "" Motor_BEV
 SG_ VZM_Verz_ASIL_Verfuegbarkeit  : 52|3@1+ (1.000000,0.000000) [0.000000|7.000000] "" Motor_BEV
 SG_ VZM_aktives_System  : 55|5@1+ (1.000000,0.000000) [0.000000|31.000000] "" Airbag Motor_BEV
 SG_ VZM_Verz_Begrenzung  : 60|1@1+ (1.000000,0.000000) [0.000000|1.000000] "" Motor_BEV
 SG_ VZM_Systemstatus  : 61|3@1+ (1.000000,0.000000) [0.000000|7.000000] "" Motor_BEV
 SG_ VZM_SRBM_Soll  : 64|12@1+ (8.000000,0.000000) [0.000000|32744.000000] "Unit_NewtoMeter" Motor_BEV
 SG_ VZM_SRBM_Ist  : 76|12@1+ (8.000000,0.000000) [0.000000|32744.000000] "Unit_NewtoMeter" Motor_BEV
 SG_ VZM_SRBM_max_Gradient  : 88|7@1+ (50.000000,0.000000) [0.000000|6250.000000] "Unit_NewtoMeterPerSecon" Motor_BEV
 SG_ VMM_Inkonsistenz_KAM  : 95|1@1+ (1.000000,0.000000) [0.000000|1.000000] "" Vector__XXX

BO_ 2463978663 VZE_04: 32 ICAS1_Gateway
 SG_ VZE_Anzeigemodus  : 0|2@1+ (1.000000,0.000000) [0.000000|3.000000] "" Vector__XXX
 SG_ VZE_Hinweistext  : 2|3@1+ (1.000000,0.000000) [1.000000|7.000000] "" Motor_BEV
 SG_ VZE_Verkehrszeichen_Einheit  : 8|1@1+ (1.000000,0.000000) [0.000000|1.000000] "" Vector__XXX
 SG_ VZE_Anzeigeunterdrueck_Zeichen_3  : 9|1@1+ (1.000000,0.000000) [0.000000|1.000000] "" Vector__XXX
 SG_ VZE_Anzeigeunterdrueck_Zeichen_2  : 10|1@1+ (1.000000,0.000000) [0.000000|1.000000] "" Vector__XXX
 SG_ VZE_Verkehrszeichen_1  : 11|8@1+ (1.000000,0.000000) [1.000000|255.000000] "" Motor_BEV
 SG_ VZE_Verkehrszeichen_2  : 19|8@1+ (1.000000,0.000000) [1.000000|255.000000] "" Vector__XXX
 SG_ VZE_Verkehrszeichen_3  : 27|8@1+ (1.000000,0.000000) [1.000000|255.000000] "" Vector__XXX
 SG_ VZE_Warnung_Verkehrszeichen_1  : 35|1@1+ (1.000000,0.000000) [0.000000|1.000000] "" Vector__XXX
 SG_ VZE_Warnung_Verkehrszeichen_2  : 36|1@1+ (1.000000,0.000000) [0.000000|1.000000] "" Vector__XXX
 SG_ VZE_Warnung_Verkehrszeichen_3  : 37|1@1+ (1.000000,0.000000) [0.000000|1.000000] "" Vector__XXX
 SG_ VZE_Zusatzschild_1  : 38|4@1+ (1.000000,0.000000) [1.000000|15.000000] "" Vector__XXX
 SG_ VZE_Zusatzschild_2  : 42|4@1+ (1.000000,0.000000) [1.000000|15.000000] "" Vector__XXX
 SG_ VZE_Zusatzschild_3  : 46|4@1+ (1.000000,0.000000) [1.000000|15.000000] "" Vector__XXX
 SG_ VZE_Anzeigeunterdrueck_Zeichen_1  : 50|1@1+ (1.000000,0.000000) [0.000000|1.000000] "" Vector__XXX
 SG_ VZE_Zeichen_01_KameraWied  : 51|1@1+ (1.000000,0.000000) [0.000000|1.000000] "" Motor_BEV
 SG_ VZE_Zeichen_02_KameraWied  : 52|1@1+ (1.000000,0.000000) [0.000000|1.000000] "" Vector__XXX
 SG_ VZE_Zeichen_03_KameraWied  : 53|1@1+ (1.000000,0.000000) [0.000000|1.000000] "" Vector__XXX
 SG_ VZE_Zeichen_01_Kamera  : 54|1@1+ (1.000000,0.000000) [0.000000|1.000000] "" Motor_BEV
 SG_ VZE_Zeichen_01_Karte  : 55|1@1+ (1.000000,0.000000) [0.000000|1.000000] "" Vector__XXX
 SG_ VZE_Zeichen_01_Gesetz  : 56|1@1+ (1.000000,0.000000) [0.000000|1.000000] "" Vector__XXX
 SG_ VZE_Zeichen_02_Kamera  : 57|1@1+ (1.000000,0.000000) [0.000000|1.000000] "" Vector__XXX
 SG_ VZE_Zeichen_02_Karte  : 58|1@1+ (1.000000,0.000000) [0.000000|1.000000] "" Vector__XXX
 SG_ VZE_Zeichen_02_Gesetz  : 59|1@1+ (1.000000,0.000000) [0.000000|1.000000] "" Vector__XXX
 SG_ VZE_Zeichen_03_Kamera  : 60|1@1+ (1.000000,0.000000) [0.000000|1.000000] "" Vector__XXX
 SG_ VZE_Zeichen_03_Karte  : 61|1@1+ (1.000000,0.000000) [0.000000|1.000000] "" Vector__XXX
 SG_ VZE_Zeichen_03_Gesetz  : 62|1@1+ (1.000000,0.000000) [0.000000|1.000000] "" Vector__XXX
 SG_ VZE_Gong  : 63|1@1+ (1.000000,0.000000) [0.000000|1.000000] "" Vector__XXX
 SG_ VZE_Anzeigeunterdrueck_Zeichen_5  : 72|1@1+ (1.000000,0.000000) [0.000000|1.000000] "" Vector__XXX
 SG_ VZE_Zeichen_05_KameraWied  : 73|1@1+ (1.000000,0.000000) [0.000000|1.000000] "" Vector__XXX
 SG_ VZE_Zeichen_05_Kamera  : 74|1@1+ (1.000000,0.000000) [0.000000|1.000000] "" Vector__XXX
 SG_ VZE_Verkehrszeichen_4  : 75|8@1+ (1.000000,0.000000) [1.000000|255.000000] "" Motor_BEV
 SG_ VZE_Verkehrszeichen_5  : 83|8@1+ (1.000000,0.000000) [1.000000|255.000000] "" Motor_BEV
 SG_ VZE_Anhaenger_Vmax  : 91|4@1+ (10.000000,10.000000) [10.000000|140.000000] "Unit_KiloMeterPerHour" Vector__XXX
 SG_ VZE_Zeichen_04_Gesetz  : 95|1@1+ (1.000000,0.000000) [0.000000|1.000000] "" Vector__XXX
 SG_ VZE_Zeichen_04_Kamera  : 96|1@1+ (1.000000,0.000000) [0.000000|1.000000] "" Vector__XXX
 SG_ VZE_Zeichen_04_KameraWied  : 97|1@1+ (1.000000,0.000000) [0.000000|1.000000] "" Vector__XXX
 SG_ VZE_Zeichen_04_Karte  : 98|1@1+ (1.000000,0.000000) [0.000000|1.000000] "" Vector__XXX
 SG_ VZE_Warnung_Verkehrszeichen_4  : 99|1@1+ (1.000000,0.000000) [0.000000|1.000000] "" Vector__XXX
 SG_ VZE_Warnung_Verkehrszeichen_5  : 100|1@1+ (1.000000,0.000000) [0.000000|1.000000] "" Vector__XXX
 SG_ VZE_Zeichen_05_Gesetz  : 101|1@1+ (1.000000,0.000000) [0.000000|1.000000] "" Vector__XXX
 SG_ VZE_Zusatzschild_4  : 102|4@1+ (1.000000,0.000000) [1.000000|15.000000] "" Vector__XXX
 SG_ VZE_Zusatzschild_5  : 106|4@1+ (1.000000,0.000000) [1.000000|15.000000] "" Vector__XXX
 SG_ VZE_Baustelle  : 110|2@1+ (1.000000,0.000000) [0.000000|3.000000] "" Vector__XXX
 SG_ VZE_Zeichen_05_Karte  : 112|1@1+ (1.000000,0.000000) [0.000000|1.000000] "" Vector__XXX
 SG_ VZE_Zeichen_05_Entfernung  : 113|7@1+ (1.000000,0.000000) [1.000000|127.000000] "Unit_Meter" Motor_BEV
 SG_ VZE_Zeichen_05_Entfernung_StdA  : 120|7@1+ (1.000000,0.000000) [1.000000|127.000000] "Unit_Meter" Motor_BEV
 SG_ VZE_Anzeigeunterdrueck_Zeichen_4  : 127|1@1+ (1.000000,0.000000) [0.000000|1.000000] "" Vector__XXX
 SG_ VZE_Verkehrszeichen_6  : 128|8@1+ (1.000000,0.000000) [1.000000|255.000000] "Unit_None" Motor_BEV
 SG_ VZE_Zusatzschild_6  : 136|4@1+ (1.000000,0.000000) [1.000000|15.000000] "" Vector__XXX
 SG_ VZE_Zeichen_06_Entfernung  : 140|7@1+ (1.000000,0.000000) [1.000000|127.000000] "Unit_Meter" Motor_BEV
 SG_ VZE_Zeichen_06_Entfernung_StdA  : 147|7@1+ (1.000000,0.000000) [1.000000|127.000000] "Unit_Meter" Motor_BEV
 SG_ VZE_Umweltinfo_Naesse  : 154|1@1+ (1.000000,0.000000) [0.000000|1.000000] "" Motor_BEV
 SG_ VZE_Umweltinfo_Nebel  : 155|1@1+ (1.000000,0.000000) [0.000000|1.000000] "" Motor_BEV
 SG_ VZE_Umweltinfo_Anhaengerbetrieb  : 156|1@1+ (1.000000,0.000000) [0.000000|1.000000] "" Vector__XXX
 SG_ VZE_Erweiterte_Information  : 157|8@1+ (1.000000,0.000000) [1.000000|255.000000] "Unit_None" Vector__XXX
 SG_ VZE_Tempowarnung_Status  : 165|1@1+ (1.000000,0.000000) [0.000000|1.000000] "" Vector__XXX
 SG_ VZE_Tempowarnung_Einheit  : 166|1@1+ (1.000000,0.000000) [0.000000|1.000000] "" Vector__XXX
 SG_ VZE_Tempowarnung_Offset  : 167|5@1+ (1.000000,0.000000) [1.000000|31.000000] "" Vector__XXX
 SG_ VZE_FoD_Status  : 206|2@1+ (1.000000,0.000000) [0.000000|3.000000] "" Vector__XXX
 SG_ VZE_Anzeige_ZS_1  : 208|4@1+ (1.000000,0.000000) [1.000000|15.000000] "Unit_None" Vector__XXX
 SG_ VZE_Anzeige_ZS_2  : 212|4@1+ (1.000000,0.000000) [1.000000|15.000000] "Unit_None" Vector__XXX
 SG_ VZE_Anzeige_ZS_3  : 216|4@1+ (1.000000,0.000000) [1.000000|15.000000] "Unit_None" Vector__XXX
 SG_ VZE_Hinweistext_03  : 220|4@1+ (1.000000,0.000000) [1.000000|15.000000] "" Vector__XXX
 SG_ VZE_Land  : 224|5@1+ (1.000000,0.000000) [1.000000|31.000000] "" Vector__XXX
 SG_ VZE_Warnung_VZ_1  : 229|1@1+ (1.000000,0.000000) [0.000000|1.000000] "" Vector__XXX
 SG_ VZE_Warnung_VZ_2  : 230|1@1+ (1.000000,0.000000) [0.000000|1.000000] "" Vector__XXX
 SG_ VZE_Warnung_VZ_3  : 231|1@1+ (1.000000,0.000000) [0.000000|1.000000] "" Vector__XXX
 SG_ VZE_Anzeige_VZ_1  : 232|8@1+ (1.000000,0.000000) [1.000000|255.000000] "" Vector__XXX
 SG_ VZE_Anzeige_VZ_2  : 240|8@1+ (1.000000,0.000000) [1.000000|255.000000] "Unit_None" Vector__XXX
 SG_ VZE_Anzeige_VZ_3  : 248|8@1+ (1.000000,0.000000) [1.000000|255.000000] "Unit_None" Vector__XXX

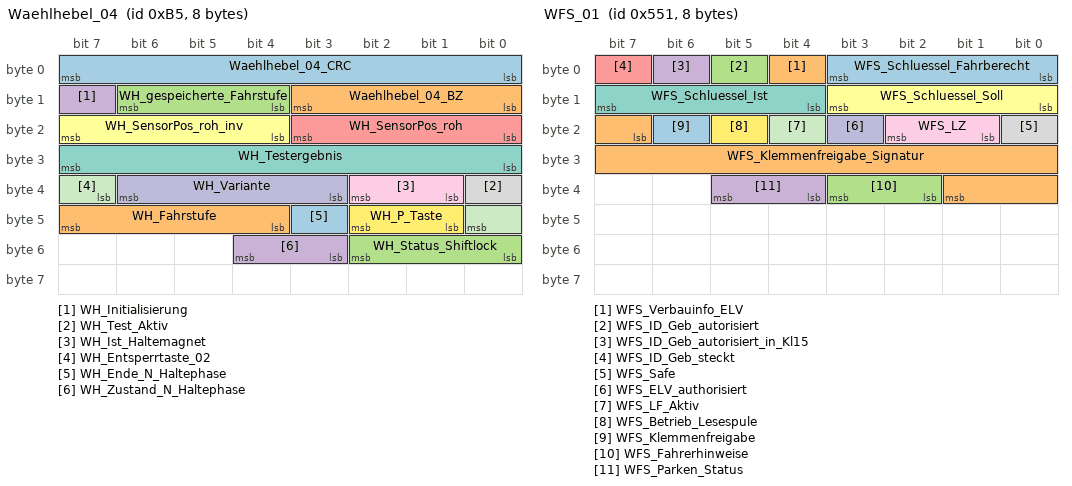
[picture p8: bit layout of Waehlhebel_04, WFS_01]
BO_ 181 Waehlhebel_04: 8 ICAS1_Gateway
 SG_ Waehlhebel_04_CRC  : 0|8@1+ (1.000000,0.000000) [0.000000|255.000000] "" Motor_BEV
 SG_ Waehlhebel_04_BZ  : 8|4@1+ (1.000000,0.000000) [0.000000|15.000000] "" Motor_BEV
 SG_ WH_gespeicherte_Fahrstufe  : 12|3@1+ (1.000000,0.000000) [0.000000|7.000000] "" Vector__XXX
 SG_ WH_Initialisierung  : 15|1@1+ (1.000000,0.000000) [0.000000|1.000000] "" Motor_BEV
 SG_ WH_SensorPos_roh  : 16|4@1+ (1.000000,0.000000) [0.000000|15.000000] "" Motor_BEV
 SG_ WH_SensorPos_roh_inv  : 20|4@1+ (1.000000,0.000000) [0.000000|15.000000] "" Motor_BEV
 SG_ WH_Testergebnis  : 24|8@1+ (1.000000,0.000000) [0.000000|255.000000] "" Vector__XXX
 SG_ WH_Test_Aktiv  : 32|1@1+ (1.000000,0.000000) [0.000000|1.000000] "" Vector__XXX
 SG_ WH_Ist_Haltemagnet  : 33|2@1+ (1.000000,0.000000) [0.000000|3.000000] "" Motor_BEV
 SG_ WH_Variante  : 35|4@1+ (1.000000,0.000000) [0.000000|15.000000] "" Motor_BEV
 SG_ WH_Entsperrtaste_02  : 39|2@1+ (1.000000,0.000000) [0.000000|3.000000] "" Motor_BEV
 SG_ WH_P_Taste  : 41|2@1+ (1.000000,0.000000) [0.000000|3.000000] "" Motor_BEV
 SG_ WH_Ende_N_Haltephase  : 43|1@1+ (1.000000,0.000000) [0.000000|1.000000] "" Vector__XXX
 SG_ WH_Fahrstufe  : 44|4@1+ (1.000000,0.000000) [0.000000|15.000000] "" Motor_BEV
 SG_ WH_Status_Shiftlock  : 48|3@1+ (1.000000,0.000000) [0.000000|7.000000] "" Motor_BEV
 SG_ WH_Zustand_N_Haltephase  : 51|2@1+ (1.000000,0.000000) [0.000000|3.000000] "" Vector__XXX

BO_ 2463978687 Waehlhebel_06: 8 ICAS1_Gateway
 SG_ WH_Fehler_Haltemagnet_Status  : 41|1@1+ (1.000000,0.000000) [0.000000|1.000000] "" Motor_BEV
 SG_ WH_Fehler_CRC_SBM  : 42|1@1+ (1.000000,0.000000) [0.000000|1.000000] "" Motor_BEV
 SG_ WH_Fehler_CRC_SBM_Status  : 43|1@1+ (1.000000,0.000000) [0.000000|1.000000] "" Motor_BEV
 SG_ WH_Fehler_Timeout_SBM  : 44|1@1+ (1.000000,0.000000) [0.000000|1.000000] "" Motor_BEV
 SG_ WH_Fehler_Timeout_SBM_Status  : 45|1@1+ (1.000000,0.000000) [0.000000|1.000000] "" Motor_BEV
 SG_ WH_Fehler_Ueberspannung  : 46|1@1+ (1.000000,0.000000) [0.000000|1.000000] "" Motor_BEV
 SG_ WH_Fehler_Ueberspannung_Status  : 47|1@1+ (1.000000,0.000000) [0.000000|1.000000] "" Motor_BEV
 SG_ WH_Fehler_BZ_SBM  : 48|1@1+ (1.000000,0.000000) [0.000000|1.000000] "" Motor_BEV
 SG_ WH_Fehler_BZ_SBM_Status  : 49|1@1+ (1.000000,0.000000) [0.000000|1.000000] "" Motor_BEV
 SG_ WH_Fehler_Unterspannung  : 50|1@1+ (1.000000,0.000000) [0.000000|1.000000] "" Motor_BEV
 SG_ WH_Fehler_Unterspannung_Status  : 51|1@1+ (1.000000,0.000000) [0.000000|1.000000] "" Motor_BEV
 SG_ WH_Fehler_Ausleuchtung  : 52|1@1+ (1.000000,0.000000) [0.000000|1.000000] "" Motor_BEV
 SG_ WH_Fehler_Ausleuchtung_Status  : 53|1@1+ (1.000000,0.000000) [0.000000|1.000000] "" Motor_BEV
 SG_ WH_Fehler_Entsperrtaste  : 54|1@1+ (1.000000,0.000000) [0.000000|1.000000] "" Motor_BEV
 SG_ WH_Fehler_Entsperrtaste_Status  : 55|1@1+ (1.000000,0.000000) [0.000000|1.000000] "" Motor_BEV
 SG_ WH_Fehler_P_Taste  : 56|1@1+ (1.000000,0.000000) [0.000000|1.000000] "" Motor_BEV
 SG_ WH_Fehler_P_Taste_Status  : 57|1@1+ (1.000000,0.000000) [0.000000|1.000000] "" Motor_BEV
 SG_ WH_Fehler_Sensor_einfach  : 58|1@1+ (1.000000,0.000000) [0.000000|1.000000] "" Motor_BEV
 SG_ WH_Fehler_Sensor_einfach_Status  : 59|1@1+ (1.000000,0.000000) [0.000000|1.000000] "" Motor_BEV
 SG_ WH_Fehler_Sensor_mehrfach  : 60|1@1+ (1.000000,0.000000) [0.000000|1.000000] "" Motor_BEV
 SG_ WH_Fehler_Sensor_mehrfach_Status  : 61|1@1+ (1.000000,0.000000) [0.000000|1.000000] "" Motor_BEV
 SG_ WH_Fehler_Shiftlock  : 62|1@1+ (1.000000,0.000000) [0.000000|1.000000] "" Motor_BEV
 SG_ WH_Fehler_Shiftlock_Status  : 63|1@1+ (1.000000,0.000000) [0.000000|1.000000] "" Motor_BEV

BO_ 916 WBA_03: 8 Motor_BEV
 SG_ WBA_03_CRC  : 0|8@1+ (1.000000,0.000000) [0.000000|255.000000] "" ICAS1_Gateway
 SG_ WBA_03_BZ  : 8|4@1+ (1.000000,0.000000) [0.000000|15.000000] "" ICAS1_Gateway
 SG_ WBA_Fahrstufe_02  : 12|4@1+ (1.000000,0.000000) [0.000000|15.000000] "" ICAS1_Gateway ICAS1_KommunikationsServer
 SG_ WBA_ZielFahrstufe  : 16|4@1+ (1.000000,0.000000) [0.000000|15.000000] "" ICAS1_Gateway
 SG_ WBA_GE_Warnung_02  : 20|4@1+ (1.000000,0.000000) [0.000000|15.000000] "" ICAS1_Gateway
 SG_ WBA_eing_Gang_02  : 24|4@1+ (1.000000,0.000000) [0.000000|15.000000] "" ICAS1_Gateway
 SG_ WBA_GE_Texte  : 28|3@1+ (1.000000,0.000000) [0.000000|7.000000] "" ICAS1_Gateway
 SG_ WBA_Segeln_aktiv  : 31|1@1+ (1.000000,0.000000) [0.000000|1.000000] "" ICAS1_Gateway
 SG_ WBA_Schaltschema_02  : 32|3@1+ (1.000000,0.000000) [0.000000|7.000000] "" ICAS1_Gateway
 SG_ WBA_Schaltschema_FS_inaktiv  : 35|2@1+ (1.000000,0.000000) [0.000000|3.000000] "" ICAS1_Gateway
 SG_ WBA_GE_Zusatzwarnungen  : 37|3@1+ (1.000000,0.000000) [0.000000|7.000000] "" ICAS1_Gateway
 SG_ GE_Sollgang  : 40|4@1+ (1.000000,0.000000) [0.000000|15.000000] "" ICAS1_Gateway
 SG_ GE_Tipschaltempf_verfuegbar  : 44|1@1+ (1.000000,0.000000) [0.000000|1.000000] "" ICAS1_Gateway
 SG_ WBA_GE_Texte_02  : 45|3@1+ (1.000000,0.000000) [0.000000|7.000000] "" ICAS1_Gateway
 SG_ WBA_Schaltschema_Tippgasse  : 48|1@1+ (1.000000,0.000000) [0.000000|1.000000] "" ICAS1_Gateway
 SG_ WBA_Schaltschema_Fahreraktion  : 49|1@1+ (1.000000,0.000000) [0.000000|1.000000] "" ICAS1_Gateway
 SG_ WBA_Schaltschema_FS_vorwaerts  : 50|2@1+ (1.000000,0.000000) [0.000000|3.000000] "" ICAS1_Gateway
 SG_ WBA_Shiftlock_Lampe  : 52|1@1+ (1.000000,0.000000) [0.000000|1.000000] "" ICAS1_Gateway
 SG_ WBA_Anforderung_Akustik  : 53|1@1+ (1.000000,0.000000) [0.000000|1.000000] "" ICAS1_Gateway
 SG_ WBA_Blinken  : 54|1@1+ (1.000000,0.000000) [0.000000|1.000000] "" ICAS1_Gateway
 SG_ GE_Wiederstart_Anz_Std  : 55|1@1+ (1.000000,0.000000) [0.000000|1.000000] "" ICAS1_Gateway
 SG_ GE_Stoppverbot_Anz_01  : 56|1@1+ (1.000000,0.000000) [0.000000|1.000000] "" ICAS1_Gateway
 SG_ GE_Stoppverbot_Anz_02  : 57|1@1+ (1.000000,0.000000) [0.000000|1.000000] "" ICAS1_Gateway
 SG_ GE_Stoppverbot_Anz_03  : 58|1@1+ (1.000000,0.000000) [0.000000|1.000000] "" ICAS1_Gateway
 SG_ GE_Stoppverbot_Anz_04  : 59|1@1+ (1.000000,0.000000) [0.000000|1.000000] "" ICAS1_Gateway
 SG_ GE_Stoppverbot_Anz_05  : 60|1@1+ (1.000000,0.000000) [0.000000|1.000000] "" ICAS1_Gateway
 SG_ GE_Stoppverbot_Anz_06  : 61|1@1+ (1.000000,0.000000) [0.000000|1.000000] "" ICAS1_Gateway
 SG_ GE_Stoppverbot_Anz_07  : 62|1@1+ (1.000000,0.000000) [0.000000|1.000000] "" ICAS1_Gateway
 SG_ GE_Stoppverbot_Anz_Std  : 63|1@1+ (1.000000,0.000000) [0.000000|1.000000] "" ICAS1_Gateway

BO_ 1361 WFS_01: 8 ICAS1_Gateway
 SG_ WFS_Schluessel_Fahrberecht  : 0|4@1+ (1.000000,0.000000) [0.000000|15.000000] "" Vector__XXX
 SG_ WFS_Verbauinfo_ELV  : 4|1@1+ (1.000000,0.000000) [0.000000|1.000000] "" Vector__XXX
 SG_ WFS_ID_Geb_autorisiert  : 5|1@1+ (1.000000,0.000000) [0.000000|1.000000] "" Vector__XXX
 SG_ WFS_ID_Geb_autorisiert_in_Kl15  : 6|1@1+ (1.000000,0.000000) [0.000000|1.000000] "" Vector__XXX
 SG_ WFS_ID_Geb_steckt  : 7|1@1+ (1.000000,0.000000) [0.000000|1.000000] "" Vector__XXX
 SG_ WFS_Schluessel_Soll  : 8|4@1+ (1.000000,0.000000) [0.000000|15.000000] "" Vector__XXX
 SG_ WFS_Schluessel_Ist  : 12|4@1+ (1.000000,0.000000) [0.000000|15.000000] "" Vector__XXX
 SG_ WFS_Safe  : 16|1@1+ (1.000000,0.000000) [0.000000|1.000000] "" Vector__XXX
 SG_ WFS_LZ  : 17|2@1+ (1.000000,0.000000) [0.000000|3.000000] "" Vector__XXX
 SG_ WFS_ELV_authorisiert  : 19|1@1+ (1.000000,0.000000) [0.000000|1.000000] "" Vector__XXX
 SG_ WFS_LF_Aktiv  : 20|1@1+ (1.000000,0.000000) [0.000000|1.000000] "" Vector__XXX
 SG_ WFS_Betrieb_Lesespule  : 21|1@1+ (1.000000,0.000000) [0.000000|1.000000] "" Vector__XXX
 SG_ WFS_Klemmenfreigabe  : 22|1@1+ (1.000000,0.000000) [0.000000|1.000000] "" Motor_BEV
 SG_ WFS_Klemmenfreigabe_Signatur  : 23|11@1+ (1.000000,0.000000) [0.000000|2047.000000] "" Vector__XXX
 SG_ WFS_Fahrerhinweise  : 34|2@1+ (1.000000,0.000000) [0.000000|3.000000] "" Vector__XXX
 SG_ WFS_Parken_Status  : 36|2@1+ (1.000000,0.000000) [0.000000|3.000000] "" Vector__XXX

BO_ 2617028096 XCP_Airbag_CRO_01: 64 Vector__XXX
 SG_ XCP_Airbag_CRO_01_Data  : 0|512@1+ (1.000000,0.000000) [0.000000|13407807929942597099574024998205846127479365820592393377723561443721764030073546976801874298166903427690031858186486050853753882811946569946433649006084096.000000] "" Airbag

BO_ 2617028097 XCP_Airbag_DTO_01: 64 Airbag
 SG_ XCP_Airbag_DTO_01_Data  : 0|512@1+ (1.000000,0.000000) [0.000000|13407807929942597099574024998205846127479365820592393377723561443721764030073546976801874298166903427690031858186486050853753882811946569946433649006084096.000000] "" Vector__XXX

BO_ 2617239040 XCP_EMotor_01_CRO_01: 64 Vector__XXX
 SG_ XCP_EMotor_01_CRO_01_Data  : 0|64@1+ (1.000000,0.000000) [0.000000|18446744073709551616.000000] "" LE1

BO_ 2617239041 XCP_EMotor_01_DTO_01: 64 LE1
 SG_ XCP_EMotor_01_DTO_01_Data  : 0|64@1+ (1.000000,0.000000) [0.000000|18446744073709551616.000000] "" Vector__XXX

BO_ 2617239042 XCP_EMotor_01_DTO_02: 64 LE1
 SG_ XCP_EMotor_01_DTO_02_Data  : 0|64@1+ (1.000000,0.000000) [0.000000|18446744073709551616.000000] "" Vector__XXX

BO_ 2617239043 XCP_EMotor_01_DTO_03: 64 LE1
 SG_ XCP_EMotor_01_DTO_03_Data  : 0|64@1+ (1.000000,0.000000) [0.000000|18446744073709551616.000000] "" Vector__XXX

BO_ 2617239044 XCP_EMotor_01_DTO_04: 64 LE1
 SG_ XCP_EMotor_01_DTO_04_Data  : 0|64@1+ (1.000000,0.000000) [0.000000|18446744073709551616.000000] "" Vector__XXX

BO_ 2617122304 XCP_EMotor_02_CRO_01: 64 Vector__XXX
 SG_ XCP_EMotor_02_CRO_01_Data  : 0|64@1+ (1.000000,0.000000) [0.000000|18446744073709551616.000000] "" LE2

BO_ 2617122305 XCP_EMotor_02_DTO_01: 64 LE2
 SG_ XCP_EMotor_02_DTO_01_Data  : 0|64@1+ (1.000000,0.000000) [0.000000|18446744073709551616.000000] "" Vector__XXX

BO_ 2617122306 XCP_EMotor_02_DTO_02: 64 LE2
 SG_ XCP_EMotor_02_DTO_02_Data  : 0|64@1+ (1.000000,0.000000) [0.000000|18446744073709551616.000000] "" Vector__XXX

BO_ 2617122307 XCP_EMotor_02_DTO_03: 64 LE2
 SG_ XCP_EMotor_02_DTO_03_Data  : 0|64@1+ (1.000000,0.000000) [0.000000|18446744073709551616.000000] "" Vector__XXX

BO_ 2617122308 XCP_EMotor_02_DTO_04: 64 LE2
 SG_ XCP_EMotor_02_DTO_04_Data  : 0|64@1+ (1.000000,0.000000) [0.000000|18446744073709551616.000000] "" Vector__XXX

BO_ 2617226768 XCP_Motor_CRO_01: 64 Vector__XXX
 SG_ XCP_Motor_CRO_01_Data  : 0|64@1+ (1.000000,0.000000) [0.000000|18446744073709551616.000000] "" Motor_BEV

BO_ 2617226769 XCP_Motor_DTO_01: 64 Motor_BEV
 SG_ XCP_Motor_DTO_01_Data  : 0|64@1+ (1.000000,0.000000) [0.000000|18446744073709551616.000000] "" Vector__XXX

BO_ 1411 ZV_02: 8 ICAS1_Gateway
 SG_ ZV_verriegeln_Anf  : 0|1@1+ (1.000000,0.000000) [0.000000|1.000000] "" Vector__XXX
 SG_ ZV_STSG_HFS_Anf  : 1|1@1+ (1.000000,0.000000) [0.000000|1.000000] "" Vector__XXX
 SG_ ZV_STSG_HBFS_Anf  : 2|1@1+ (1.000000,0.000000) [0.000000|1.000000] "" Vector__XXX
 SG_ ZV_Anf_Challenge_Auth  : 3|1@1+ (1.000000,0.000000) [0.000000|1.000000] "" Vector__XXX
 SG_ BCM_FH_Freigabe  : 12|1@1+ (1.000000,0.000000) [0.000000|1.000000] "" Vector__XXX
 SG_ BCM_Komfortfkt_Freigabe  : 13|1@1+ (1.000000,0.000000) [0.000000|1.000000] "" Vector__XXX
 SG_ BCM_HSK_Freigabe  : 14|1@1+ (1.000000,0.000000) [0.000000|1.000000] "" Vector__XXX
 SG_ BCM_Verdeck_Freigabe  : 15|1@1+ (1.000000,0.000000) [0.000000|1.000000] "" Vector__XXX
 SG_ ZV_verriegelt_intern_ist  : 16|1@1+ (1.000000,0.000000) [0.000000|1.000000] "" Vector__XXX
 SG_ ZV_verriegelt_extern_ist  : 17|1@1+ (1.000000,0.000000) [0.000000|1.000000] "" Airbag
 SG_ ZV_verriegelt_intern_soll  : 18|1@1+ (1.000000,0.000000) [0.000000|1.000000] "" Vector__XXX
 SG_ ZV_verriegelt_extern_soll  : 19|1@1+ (1.000000,0.000000) [0.000000|1.000000] "" Airbag
 SG_ ZV_gesafet_extern_ist  : 20|1@1+ (1.000000,0.000000) [0.000000|1.000000] "" Vector__XXX
 SG_ ZV_gesafet_extern_soll  : 21|1@1+ (1.000000,0.000000) [0.000000|1.000000] "" Vector__XXX
 SG_ ZV_Einzeltuerentriegelung  : 22|1@1+ (1.000000,0.000000) [0.000000|1.000000] "" Vector__XXX
 SG_ ZV_Heckeinzelentriegelung  : 23|1@1+ (1.000000,0.000000) [0.000000|1.000000] "" Vector__XXX
 SG_ ZV_FT_offen  : 24|1@1+ (1.000000,0.000000) [0.000000|1.000000] "" Motor_BEV
 SG_ ZV_BT_offen  : 25|1@1+ (1.000000,0.000000) [0.000000|1.000000] "" Motor_BEV
 SG_ ZV_HFS_offen  : 26|1@1+ (1.000000,0.000000) [0.000000|1.000000] "" Motor_BEV
 SG_ ZV_HBFS_offen  : 27|1@1+ (1.000000,0.000000) [0.000000|1.000000] "" Motor_BEV
 SG_ ZV_HD_offen  : 28|1@1+ (1.000000,0.000000) [0.000000|1.000000] "" Motor_BEV
 SG_ ZV_HS_offen  : 29|1@1+ (1.000000,0.000000) [0.000000|1.000000] "" Vector__XXX
 SG_ IRUE_aktiv  : 30|1@1+ (1.000000,0.000000) [0.000000|1.000000] "" Vector__XXX
 SG_ DWA_aktiv  : 31|1@1+ (1.000000,0.000000) [0.000000|1.000000] "" Vector__XXX
 SG_ FFB_HDF_Taste  : 34|1@1+ (1.000000,0.000000) [0.000000|1.000000] "" Vector__XXX
 SG_ FFB_Panik_Taste  : 35|1@1+ (1.000000,0.000000) [0.000000|1.000000] "" Vector__XXX
 SG_ FFB_Auf_Taste  : 36|1@1+ (1.000000,0.000000) [0.000000|1.000000] "" Vector__XXX
 SG_ FFB_Zu_Taste  : 37|1@1+ (1.000000,0.000000) [0.000000|1.000000] "" Vector__XXX
 SG_ FFB_CarFinder  : 38|1@1+ (1.000000,0.000000) [0.000000|1.000000] "" Vector__XXX
 SG_ FFB_Komfortoeffnen  : 39|1@1+ (1.000000,0.000000) [0.000000|1.000000] "" Vector__XXX
 SG_ FFB_Komfortschliessen  : 40|1@1+ (1.000000,0.000000) [0.000000|1.000000] "" Vector__XXX
 SG_ FBS_IDG_in_Reichweite  : 41|1@1+ (1.000000,0.000000) [0.000000|1.000000] "" Vector__XXX
 SG_ ZV_Schluessel_Zugang  : 42|4@1+ (1.000000,0.000000) [0.000000|15.000000] "" Vector__XXX
 SG_ ZV_SafeFunktion_aktiv  : 46|1@1+ (1.000000,0.000000) [0.000000|1.000000] "" Vector__XXX
 SG_ FBS_Warn_Schluessel_Batt  : 47|1@1+ (1.000000,0.000000) [0.000000|1.000000] "" Vector__XXX
 SG_ ZV_Oeffnungsmodus  : 48|2@1+ (1.000000,0.000000) [0.000000|3.000000] "" Vector__XXX
 SG_ ZV_ist_Zustand_verfuegbar  : 54|1@1+ (1.000000,0.000000) [0.000000|1.000000] "" Vector__XXX
 SG_ IRUE_Taster_Fkts_LED  : 55|1@1+ (1.000000,0.000000) [0.000000|1.000000] "" Vector__XXX
 SG_ ZV_Tankklappe_offen  : 56|1@1+ (1.000000,0.000000) [0.000000|1.000000] "" Vector__XXX
 SG_ ZV_Rollo_auf  : 57|1@1+ (1.000000,0.000000) [0.000000|1.000000] "" Vector__XXX
 SG_ ZV_Rollo_zu  : 58|1@1+ (1.000000,0.000000) [0.000000|1.000000] "" Vector__XXX
 SG_ ZV_SAD_auf  : 59|1@1+ (1.000000,0.000000) [0.000000|1.000000] "" Vector__XXX
 SG_ ZV_SAD_zu  : 60|1@1+ (1.000000,0.000000) [0.000000|1.000000] "" Vector__XXX
 SG_ ZV_verriegelt_soll  : 62|2@1+ (1.000000,0.000000) [0.000000|3.000000] "" Vector__XXX

CM_ BO_ 339 "CAN-Botschaft";
CM_ SG_ 190 MO_EM1_Sollmodus "Werte:
Anforderung der Betriebsart der E-Maschine
0: Standby; Kommunikation aktiv; aktiver Kurzschluss
1: Momentenregelung
2: Drehzahlregelung (interner Regelkreis)
3: Spannungsregelung
4: Drehzahlregelung (externer Regelkreis)
5: nicht verfügbar";
CM_ SG_ 190 MO_EM2_Sollmodus "Werte:
Anforderung der Betriebsart der E-Maschine
0: Standby; Kommunikation aktiv; aktiver Kurzschluss
1: Momentenregelung
2: Drehzahlregelung (interner Regelkreis)
3: Spannungsregelung
4: Drehzahlregelung (externer Regelkreis)
5: nicht verfügbar";
CM_ SG_ 518 Parken_QFK_KruemmSoll "Krümmungsanforderung";
CM_ SG_ 1124 PSD_Sys_Laendercode "Ländercode
";
CM_ SG_ 591 RDR1_Blindheit_erkannt "Blindheitserkennung";
CM_ SG_ 980 WH_SRA "Scheinwerferreinigungsanlage

derzeit nur bei PAG umgesetzt";
CM_ SG_ 1716 VIN_01_MUX "Achtung:
Die Botschaft ist nicht linear gemultiplext!!!
Sondern 0,1,0,2,0, usw.";
CM_ SG_ 1716 VIN_4 "Initwert:
0x2D bei Fahrzeugen mit Wegfahrsperrengeneration >= 5
0x58 bei Fahrzeugen mit Wegfahrsperrengeneration < 5 (z.B. WFS-4)";
CM_ SG_ 1716 VIN_11 "Initwert:
0x2D bei Fahrzeugen mit Wegfahrsperrengeneration >= 5
0x58 bei Fahrzeugen mit Wegfahrsperrengeneration < 5 (z.B. WFS-4)";
CM_ SG_ 1716 VIN_5 "Initwert:
0x2D bei Fahrzeugen mit Wegfahrsperrengeneration >= 5
0x58 bei Fahrzeugen mit Wegfahrsperrengeneration < 5 (z.B. WFS-4)";
CM_ SG_ 1716 VIN_12 "Initwert:
0x2D bei Fahrzeugen mit Wegfahrsperrengeneration >= 5
0x58 bei Fahrzeugen mit Wegfahrsperrengeneration < 5 (z.B. WFS-4)";
CM_ SG_ 1716 VIN_6 "Initwert:
0x2D bei Fahrzeugen mit Wegfahrsperrengeneration >= 5
0x58 bei Fahrzeugen mit Wegfahrsperrengeneration < 5 (z.B. WFS-4)";
CM_ SG_ 1716 VIN_13 "Initwert:
0x2D bei Fahrzeugen mit Wegfahrsperrengeneration >= 5
0x58 bei Fahrzeugen mit Wegfahrsperrengeneration < 5 (z.B. WFS-4)";
CM_ SG_ 1716 VIN_7 "Initwert:
0x2D bei Fahrzeugen mit Wegfahrsperrengeneration >= 5
0x58 bei Fahrzeugen mit Wegfahrsperrengeneration < 5 (z.B. WFS-4)";
CM_ SG_ 1716 VIN_14 "Initwert:
0x2D bei Fahrzeugen mit Wegfahrsperrengeneration >= 5
0x58 bei Fahrzeugen mit Wegfahrsperrengeneration < 5 (z.B. WFS-4)";
CM_ SG_ 1716 VIN_1 "Initwert:
0x2D bei Fahrzeugen mit Wegfahrsperrengeneration >= 5
0x58 bei Fahrzeugen mit Wegfahrsperrengeneration < 5 (z.B. WFS-4)";
CM_ SG_ 1716 VIN_8 "Initwert:
0x2D bei Fahrzeugen mit Wegfahrsperrengeneration >= 5
0x58 bei Fahrzeugen mit Wegfahrsperrengeneration < 5 (z.B. WFS-4)";
CM_ SG_ 1716 VIN_15 "Initwert:
0x2D bei Fahrzeugen mit Wegfahrsperrengeneration >= 5
0x58 bei Fahrzeugen mit Wegfahrsperrengeneration < 5 (z.B. WFS-4)";
CM_ SG_ 1716 VIN_2 "Initwert:
0x2D bei Fahrzeugen mit Wegfahrsperrengeneration >= 5
0x58 bei Fahrzeugen mit Wegfahrsperrengeneration < 5 (z.B. WFS-4)";
CM_ SG_ 1716 VIN_9 "Initwert:
0x2D bei Fahrzeugen mit Wegfahrsperrengeneration >= 5
0x58 bei Fahrzeugen mit Wegfahrsperrengeneration < 5 (z.B. WFS-4)";
CM_ SG_ 1716 VIN_16 "Initwert:
0x2D bei Fahrzeugen mit Wegfahrsperrengeneration >= 5
0x58 bei Fahrzeugen mit Wegfahrsperrengeneration < 5 (z.B. WFS-4)";
CM_ SG_ 1716 VIN_3 "Initwert:
0x2D bei Fahrzeugen mit Wegfahrsperrengeneration >= 5
0x58 bei Fahrzeugen mit Wegfahrsperrengeneration < 5 (z.B. WFS-4)";
CM_ SG_ 1716 VIN_10 "Initwert:
0x2D bei Fahrzeugen mit Wegfahrsperrengeneration >= 5
0x58 bei Fahrzeugen mit Wegfahrsperrengeneration < 5 (z.B. WFS-4)";
CM_ SG_ 1716 VIN_17 "Initwert:
0x2D bei Fahrzeugen mit Wegfahrsperrengeneration >= 5
0x58 bei Fahrzeugen mit Wegfahrsperrengeneration < 5 (z.B. WFS-4)";
CM_ SG_ 1411 BCM_HSK_Freigabe "Handschuhkastenfreigabe";
CM_ SG_ 1411 ZV_Heckeinzelentriegelung "Heckdeckeleinzelentriegelung";
BA_DEF_ BO_ "DiagRequest" ENUM "No", "Yes";
BA_DEF_ BO_ "DiagResponse" ENUM "No", "Yes";
BA_DEF_ BO_ "DiagState" ENUM "No", "Yes";
BA_DEF_ BO_ "GenMsgChkConstant" HEX 0 4095;
BA_DEF_ BO_ "GenMsgCycleTime" INT 0 65535;
BA_DEF_ BO_ "GenMsgCycleTimeFast" INT 0 65535;
BA_DEF_ BO_ "GenMsgDelayTime" INT 0 100000;
BA_DEF_ BO_ "GenMsgILSupport" ENUM "No", "Yes";
BA_DEF_ BO_ "GenMsgNrOfRepetition" INT 0 100;
BA_DEF_ BO_ "GenMsgPDUConstants" STRING;
BA_DEF_ BO_ "GenMsgSendType" ENUM "Cyclic", "not_used", "not_used", "not_used", "not_used", "not_used", "not_used", "IfActive", "NoMsgSendType";
BA_DEF_ BO_ "GenMsgStartDelayTime" INT 0 100000;
BA_DEF_ BO_ "NmMessage" ENUM "No", "Yes";
BA_DEF_ BO_ "NmhMessage" ENUM "No", "Yes";
BA_DEF_ BO_ "MsgType" ENUM "Application", "NM", "NMH", "TP2.0", "ISO-TP", "BAP", "EID", "KS";
BA_DEF_ BO_ "VAGTP20_API" HEX 0 255;
BA_DEF_ BO_ "VAGTP20_DynConnection" ENUM "No", "Yes";
BA_DEF_ BO_ "VAGTP20_DynSetup" ENUM "No", "Yes";
BA_DEF_ BO_ "VAGTP20_StatConnection" ENUM "No", "Yes";
BA_DEF_ BO_ "CANFD_BRS" ENUM "0", "1";
BA_DEF_ BO_ "VFrameFormat" ENUM "StandardCAN", "ExtendedCAN", "reserved", "reserved", "reserved", "reserved", "reserved", "reserved", "reserved", "reserved", "reserved", "reserved", "reserved", "reserved", "StandardCAN_FD", "ExtendedCAN_FD";
BA_DEF_ SG_ "GenSigSendType" ENUM "Cyclic", "OnWrite", "OnWriteWithRepetition", "OnChange", "OnChangeWithRepetition", "IfActive", "IfActiveWithRepetition", "NoSigSendType", "OnChangeAndIfActive", "OnChangeAndIfActiveWithRepetition";
BA_DEF_ SG_ "GenSigFuncType" ENUM "NoFunction", "MsgCounter", "CRC-8", "XOR", "XOR-2", "DatedBit", "SW-Kl15", "CHK", "Constant", "Protocol", "CRC-8-SAE_J1850";
BA_DEF_ SG_ "GenSigSwitchedByIgnition" ENUM "No", "Yes";
BA_DEF_DEF_  "DiagRequest" "No";
BA_DEF_DEF_  "DiagResponse" "No";
BA_DEF_DEF_  "DiagState" "No";
BA_DEF_DEF_  "GenMsgChkConstant" 0;
BA_DEF_DEF_  "GenMsgCycleTime" 0;
BA_DEF_DEF_  "GenMsgCycleTimeFast" 0;
BA_DEF_DEF_  "GenMsgDelayTime" 0;
BA_DEF_DEF_  "GenMsgILSupport" "No";
BA_DEF_DEF_  "GenMsgNrOfRepetition" 0;
BA_DEF_DEF_  "GenMsgPDUConstants" "";
BA_DEF_DEF_  "GenMsgSendType" "NoMsgSendType";
BA_DEF_DEF_  "GenMsgStartDelayTime" 0;
BA_DEF_DEF_  "NmMessage" "No";
BA_DEF_DEF_  "NmhMessage" "No";
BA_DEF_DEF_  "MsgType" "Application";
BA_DEF_DEF_  "VAGTP20_API" 0;
BA_DEF_DEF_  "VAGTP20_DynConnection" "No";
BA_DEF_DEF_  "VAGTP20_DynSetup" "No";
BA_DEF_DEF_  "VAGTP20_StatConnection" "No";
BA_DEF_DEF_  "CANFD_BRS" "1";
BA_DEF_DEF_  "VFrameFormat" "StandardCAN";
BA_DEF_DEF_  "GenSigSendType" "NoSigSendType";
BA_DEF_DEF_  "GenSigFuncType" "NoFunction";
BA_DEF_DEF_  "GenSigSwitchedByIgnition" "Yes";
BA_ "GenMsgCycleTime" BO_ 246 10;
BA_ "GenMsgILSupport" BO_ 246 "Yes";
BA_ "GenMsgPDUConstants" BO_ 246 "0x89,0xd6,0xf6,0xdd,0xe7,0x74,0x0f,0xd2,0x26,0x5a,0x44,0x70,0xd5,0x67,0x79,0x3d";
BA_ "GenMsgSendType" BO_ 246 "Cyclic";
BA_ "VFrameFormat" BO_ 246 "StandardCAN_FD";
BA_ "GenMsgCycleTime" BO_ 190 10;
BA_ "GenMsgILSupport" BO_ 190 "Yes";
BA_ "GenMsgPDUConstants" BO_ 190 "0x18,0x71,0x10,0x8d,0xd7,0xaa,0xb0,0x78,0xac,0x12,0xae,0x0c,0xdd,0xf1,0x85,0x68";
BA_ "GenMsgSendType" BO_ 190 "Cyclic";
BA_ "VFrameFormat" BO_ 190 "StandardCAN_FD";
BA_ "GenMsgCycleTime" BO_ 2463978666 100;
BA_ "GenMsgILSupport" BO_ 2463978666 "Yes";
BA_ "GenMsgSendType" BO_ 2463978666 "Cyclic";
BA_ "VFrameFormat" BO_ 2463978666 "ExtendedCAN_FD";
BA_ "GenMsgChkConstant" BO_ 1601 71;
BA_ "GenMsgCycleTime" BO_ 1601 1000;
BA_ "GenMsgILSupport" BO_ 1601 "Yes";
BA_ "GenMsgPDUConstants" BO_ 1601 "0x47,0x47,0x47,0x47,0x47,0x47,0x47,0x47,0x47,0x47,0x47,0x47,0x47,0x47,0x47,0x47";
BA_ "GenMsgSendType" BO_ 1601 "Cyclic";
BA_ "VFrameFormat" BO_ 1601 "StandardCAN_FD";
BA_ "GenMsgCycleTime" BO_ 1155 500;
BA_ "GenMsgDelayTime" BO_ 1155 50;
BA_ "GenMsgILSupport" BO_ 1155 "Yes";
BA_ "GenMsgSendType" BO_ 1155 "Cyclic";
BA_ "VFrameFormat" BO_ 1155 "StandardCAN_FD";
BA_ "GenMsgCycleTime" BO_ 2527679686 2000;
BA_ "GenMsgDelayTime" BO_ 2527679686 100;
BA_ "GenMsgILSupport" BO_ 2527679686 "Yes";
BA_ "GenMsgSendType" BO_ 2527679686 "Cyclic";
BA_ "VFrameFormat" BO_ 2527679686 "ExtendedCAN_FD";
BA_ "GenMsgILSupport" BO_ 22 "Yes";
BA_ "VFrameFormat" BO_ 22 "StandardCAN_FD";
BA_ "GenMsgILSupport" BO_ 24 "Yes";
BA_ "VFrameFormat" BO_ 24 "StandardCAN_FD";
BA_ "GenMsgCycleTime" BO_ 339 200;
BA_ "GenMsgDelayTime" BO_ 339 10;
BA_ "GenMsgILSupport" BO_ 339 "Yes";
BA_ "GenMsgPDUConstants" BO_ 339 "0x03,0x13,0x23,0x7a,0x40,0x51,0x68,0xba,0xa8,0xbe,0x55,0x02,0x11,0x31,0x76,0xec";
BA_ "GenMsgSendType" BO_ 339 "Cyclic";
BA_ "VFrameFormat" BO_ 339 "StandardCAN_FD";
BA_ "GenMsgCycleTime" BO_ 2600468501 200;
BA_ "GenMsgCycleTimeFast" BO_ 2600468501 10;
BA_ "NmhMessage" BO_ 2600468501 "Yes";
BA_ "MsgType" BO_ 2600468501 "NMH";
BA_ "CANFD_BRS" BO_ 2600468501 "0";
BA_ "VFrameFormat" BO_ 2600468501 "ExtendedCAN";
BA_ "GenMsgCycleTime" BO_ 2600468604 200;
BA_ "GenMsgCycleTimeFast" BO_ 2600468604 10;
BA_ "NmhMessage" BO_ 2600468604 "Yes";
BA_ "MsgType" BO_ 2600468604 "NMH";
BA_ "CANFD_BRS" BO_ 2600468604 "0";
BA_ "VFrameFormat" BO_ 2600468604 "ExtendedCAN";
BA_ "GenMsgCycleTime" BO_ 2600468496 200;
BA_ "GenMsgCycleTimeFast" BO_ 2600468496 10;
BA_ "NmhMessage" BO_ 2600468496 "Yes";
BA_ "MsgType" BO_ 2600468496 "NMH";
BA_ "CANFD_BRS" BO_ 2600468496 "0";
BA_ "VFrameFormat" BO_ 2600468496 "ExtendedCAN";
BA_ "GenMsgCycleTime" BO_ 2600468664 200;
BA_ "GenMsgCycleTimeFast" BO_ 2600468664 10;
BA_ "NmhMessage" BO_ 2600468664 "Yes";
BA_ "MsgType" BO_ 2600468664 "NMH";
BA_ "CANFD_BRS" BO_ 2600468664 "0";
BA_ "VFrameFormat" BO_ 2600468664 "ExtendedCAN";
BA_ "GenMsgCycleTime" BO_ 2600468598 200;
BA_ "GenMsgCycleTimeFast" BO_ 2600468598 10;
BA_ "NmhMessage" BO_ 2600468598 "Yes";
BA_ "MsgType" BO_ 2600468598 "NMH";
BA_ "CANFD_BRS" BO_ 2600468598 "0";
BA_ "VFrameFormat" BO_ 2600468598 "ExtendedCAN";
BA_ "GenMsgCycleTime" BO_ 2600468733 200;
BA_ "GenMsgCycleTimeFast" BO_ 2600468733 10;
BA_ "NmhMessage" BO_ 2600468733 "Yes";
BA_ "MsgType" BO_ 2600468733 "NMH";
BA_ "CANFD_BRS" BO_ 2600468733 "0";
BA_ "VFrameFormat" BO_ 2600468733 "ExtendedCAN";
BA_ "DiagRequest" BO_ 2621440533 "Yes";
BA_ "MsgType" BO_ 2621440533 "ISO-TP";
BA_ "VFrameFormat" BO_ 2621440533 "ExtendedCAN_FD";
BA_ "DiagResponse" BO_ 2621571605 "Yes";
BA_ "MsgType" BO_ 2621571605 "ISO-TP";
BA_ "VFrameFormat" BO_ 2621571605 "ExtendedCAN_FD";
BA_ "DiagRequest" BO_ 2621440636 "Yes";
BA_ "MsgType" BO_ 2621440636 "ISO-TP";
BA_ "VFrameFormat" BO_ 2621440636 "ExtendedCAN_FD";
BA_ "DiagResponse" BO_ 2621571708 "Yes";
BA_ "MsgType" BO_ 2621571708 "ISO-TP";
BA_ "VFrameFormat" BO_ 2621571708 "ExtendedCAN_FD";
BA_ "DiagRequest" BO_ 2621440696 "Yes";
BA_ "MsgType" BO_ 2621440696 "ISO-TP";
BA_ "VFrameFormat" BO_ 2621440696 "ExtendedCAN_FD";
BA_ "DiagResponse" BO_ 2621571768 "Yes";
BA_ "MsgType" BO_ 2621571768 "ISO-TP";
BA_ "VFrameFormat" BO_ 2621571768 "ExtendedCAN_FD";
BA_ "DiagState" BO_ 2621506048 "Yes";
BA_ "MsgType" BO_ 2621506048 "ISO-TP";
BA_ "VFrameFormat" BO_ 2621506048 "ExtendedCAN_FD";
BA_ "DiagRequest" BO_ 2621440630 "Yes";
BA_ "MsgType" BO_ 2621440630 "ISO-TP";
BA_ "VFrameFormat" BO_ 2621440630 "ExtendedCAN_FD";
BA_ "DiagResponse" BO_ 2621571702 "Yes";
BA_ "MsgType" BO_ 2621571702 "ISO-TP";
BA_ "VFrameFormat" BO_ 2621571702 "ExtendedCAN_FD";
BA_ "DiagState" BO_ 2564502513 "Yes";
BA_ "MsgType" BO_ 2564502513 "ISO-TP";
BA_ "VFrameFormat" BO_ 2564502513 "ExtendedCAN_FD";
BA_ "DiagRequest" BO_ 2564425457 "Yes";
BA_ "MsgType" BO_ 2564425457 "ISO-TP";
BA_ "VFrameFormat" BO_ 2564425457 "ExtendedCAN_FD";
BA_ "DiagResponse" BO_ 2564485382 "Yes";
BA_ "MsgType" BO_ 2564485382 "ISO-TP";
BA_ "VFrameFormat" BO_ 2564485382 "ExtendedCAN_FD";
BA_ "DiagRequest" BO_ 2564425713 "Yes";
BA_ "MsgType" BO_ 2564425713 "ISO-TP";
BA_ "VFrameFormat" BO_ 2564425713 "ExtendedCAN_FD";
BA_ "DiagResponse" BO_ 2564485383 "Yes";
BA_ "MsgType" BO_ 2564485383 "ISO-TP";
BA_ "VFrameFormat" BO_ 2564485383 "ExtendedCAN_FD";
BA_ "DiagRequest" BO_ 2564424177 "Yes";
BA_ "MsgType" BO_ 2564424177 "ISO-TP";
BA_ "VFrameFormat" BO_ 2564424177 "ExtendedCAN_FD";
BA_ "DiagResponse" BO_ 2564485377 "Yes";
BA_ "MsgType" BO_ 2564485377 "ISO-TP";
BA_ "VFrameFormat" BO_ 2564485377 "ExtendedCAN_FD";
BA_ "GenMsgCycleTime" BO_ 627 100;
BA_ "GenMsgDelayTime" BO_ 627 10;
BA_ "GenMsgILSupport" BO_ 627 "Yes";
BA_ "GenMsgPDUConstants" BO_ 627 "0xc6,0x40,0x32,0xbe,0xc7,0x76,0x16,0x17,0x05,0xd8,0xab,0x52,0x45,0x35,0xf1,0x1d";
BA_ "GenMsgSendType" BO_ 627 "Cyclic";
BA_ "VFrameFormat" BO_ 627 "StandardCAN_FD";
BA_ "GenMsgCycleTime" BO_ 2463978709 500;
BA_ "GenMsgDelayTime" BO_ 2463978709 50;
BA_ "GenMsgILSupport" BO_ 2463978709 "Yes";
BA_ "GenMsgSendType" BO_ 2463978709 "Cyclic";
BA_ "VFrameFormat" BO_ 2463978709 "ExtendedCAN_FD";
BA_ "GenMsgCycleTime" BO_ 2589283656 500;
BA_ "GenMsgDelayTime" BO_ 2589283656 100;
BA_ "GenMsgILSupport" BO_ 2589283656 "Yes";
BA_ "GenMsgSendType" BO_ 2589283656 "Cyclic";
BA_ "VFrameFormat" BO_ 2589283656 "ExtendedCAN_FD";
BA_ "GenMsgCycleTime" BO_ 2527679741 240;
BA_ "GenMsgILSupport" BO_ 2527679741 "Yes";
BA_ "GenMsgPDUConstants" BO_ 2527679741 "0x9d,0xe8,0x36,0xa1,0xca,0x3b,0x1d,0x33,0xe0,0xd5,0xbb,0x5f,0xae,0x3c,0x31,0x9f";
BA_ "GenMsgSendType" BO_ 2527679741 "Cyclic";
BA_ "VFrameFormat" BO_ 2527679741 "ExtendedCAN_FD";
BA_ "GenMsgCycleTime" BO_ 518 20;
BA_ "GenMsgILSupport" BO_ 518 "Yes";
BA_ "GenMsgSendType" BO_ 518 "Cyclic";
BA_ "VFrameFormat" BO_ 518 "StandardCAN_FD";
BA_ "GenMsgCycleTime" BO_ 2527679685 2000;
BA_ "GenMsgDelayTime" BO_ 2527679685 100;
BA_ "GenMsgILSupport" BO_ 2527679685 "Yes";
BA_ "GenMsgSendType" BO_ 2527679685 "Cyclic";
BA_ "VFrameFormat" BO_ 2527679685 "ExtendedCAN_FD";
BA_ "GenMsgCycleTime" BO_ 319 200;
BA_ "GenMsgDelayTime" BO_ 319 20;
BA_ "GenMsgILSupport" BO_ 319 "Yes";
BA_ "GenMsgSendType" BO_ 319 "Cyclic";
BA_ "CANFD_BRS" BO_ 319 "0";
BA_ "GenMsgCycleTime" BO_ 1122 150;
BA_ "GenMsgILSupport" BO_ 1122 "Yes";
BA_ "GenMsgSendType" BO_ 1122 "Cyclic";
BA_ "VFrameFormat" BO_ 1122 "StandardCAN_FD";
BA_ "GenMsgCycleTime" BO_ 1123 150;
BA_ "GenMsgILSupport" BO_ 1123 "Yes";
BA_ "GenMsgSendType" BO_ 1123 "Cyclic";
BA_ "VFrameFormat" BO_ 1123 "StandardCAN_FD";
BA_ "GenMsgCycleTime" BO_ 1124 150;
BA_ "GenMsgILSupport" BO_ 1124 "Yes";
BA_ "GenMsgSendType" BO_ 1124 "Cyclic";
BA_ "VFrameFormat" BO_ 1124 "StandardCAN_FD";
BA_ "GenMsgCycleTime" BO_ 591 40;
BA_ "GenMsgILSupport" BO_ 591 "Yes";
BA_ "GenMsgSendType" BO_ 591 "Cyclic";
BA_ "VFrameFormat" BO_ 591 "StandardCAN_FD";
BA_ "DiagRequest" BO_ 2033 "Yes";
BA_ "MsgType" BO_ 2033 "ISO-TP";
BA_ "CANFD_BRS" BO_ 2033 "0";
BA_ "DiagResponse" BO_ 2041 "Yes";
BA_ "MsgType" BO_ 2041 "ISO-TP";
BA_ "CANFD_BRS" BO_ 2041 "0";
BA_ "GenMsgCycleTime" BO_ 980 1000;
BA_ "GenMsgCycleTimeFast" BO_ 980 100;
BA_ "GenMsgDelayTime" BO_ 980 50;
BA_ "GenMsgILSupport" BO_ 980 "Yes";
BA_ "GenMsgNrOfRepetition" BO_ 980 5;
BA_ "GenMsgPDUConstants" BO_ 980 "0xc3,0x79,0xbf,0xdb,0xe9,0x11,0x46,0x86,0x69,0xb6,0x9b,0x29,0x15,0x9c,0x45,0x0d";
BA_ "GenMsgSendType" BO_ 980 "Cyclic";
BA_ "VFrameFormat" BO_ 980 "StandardCAN_FD";
BA_ "GenMsgDelayTime" BO_ 2464153718 50;
BA_ "GenMsgILSupport" BO_ 2464153718 "Yes";
BA_ "VFrameFormat" BO_ 2464153718 "ExtendedCAN_FD";
BA_ "GenMsgDelayTime" BO_ 2464284790 50;
BA_ "GenMsgILSupport" BO_ 2464284790 "Yes";
BA_ "VFrameFormat" BO_ 2464284790 "ExtendedCAN_FD";
BA_ "GenMsgCycleTime" BO_ 1413 1000;
BA_ "GenMsgDelayTime" BO_ 1413 10;
BA_ "GenMsgILSupport" BO_ 1413 "Yes";
BA_ "GenMsgSendType" BO_ 1413 "Cyclic";
BA_ "VFrameFormat" BO_ 1413 "StandardCAN_FD";
BA_ "GenMsgCycleTime" BO_ 2589283396 500;
BA_ "GenMsgILSupport" BO_ 2589283396 "Yes";
BA_ "GenMsgSendType" BO_ 2589283396 "Cyclic";
BA_ "VFrameFormat" BO_ 2589283396 "ExtendedCAN_FD";
BA_ "GenMsgCycleTime" BO_ 1019 80;
BA_ "GenMsgILSupport" BO_ 1019 "Yes";
BA_ "GenMsgSendType" BO_ 1019 "Cyclic";
BA_ "VFrameFormat" BO_ 1019 "StandardCAN_FD";
BA_ "GenMsgCycleTime" BO_ 1716 200;
BA_ "GenMsgILSupport" BO_ 1716 "Yes";
BA_ "GenMsgSendType" BO_ 1716 "Cyclic";
BA_ "VFrameFormat" BO_ 1716 "StandardCAN_FD";
BA_ "GenMsgCycleTime" BO_ 261 20;
BA_ "GenMsgILSupport" BO_ 261 "Yes";
BA_ "GenMsgPDUConstants" BO_ 261 "0xde,0x0e,0xa7,0x1d,0xc3,0x83,0xbd,0x82,0x8c,0xa2,0x0c,0x7b,0x4d,0x3c,0x58,0x79";
BA_ "GenMsgSendType" BO_ 261 "Cyclic";
BA_ "VFrameFormat" BO_ 261 "StandardCAN_FD";
BA_ "GenMsgCycleTime" BO_ 313 20;
BA_ "GenMsgILSupport" BO_ 313 "Yes";
BA_ "GenMsgPDUConstants" BO_ 313 "0xed,0x03,0x1c,0x13,0xc6,0x23,0x78,0x7a,0x8b,0x40,0x14,0x51,0xbf,0x68,0x32,0xba";
BA_ "GenMsgSendType" BO_ 313 "Cyclic";
BA_ "VFrameFormat" BO_ 313 "StandardCAN_FD";
BA_ "GenMsgCycleTime" BO_ 2463978663 200;
BA_ "GenMsgDelayTime" BO_ 2463978663 40;
BA_ "GenMsgILSupport" BO_ 2463978663 "Yes";
BA_ "GenMsgSendType" BO_ 2463978663 "Cyclic";
BA_ "VFrameFormat" BO_ 2463978663 "ExtendedCAN_FD";
BA_ "GenMsgChkConstant" BO_ 181 228;
BA_ "GenMsgCycleTime" BO_ 181 10;
BA_ "GenMsgILSupport" BO_ 181 "Yes";
BA_ "GenMsgPDUConstants" BO_ 181 "0xe4,0xe4,0xe4,0xe4,0xe4,0xe4,0xe4,0xe4,0xe4,0xe4,0xe4,0xe4,0xe4,0xe4,0xe4,0xe4";
BA_ "GenMsgSendType" BO_ 181 "Cyclic";
BA_ "VFrameFormat" BO_ 181 "StandardCAN_FD";
BA_ "GenMsgCycleTime" BO_ 2463978687 1000;
BA_ "GenMsgDelayTime" BO_ 2463978687 100;
BA_ "GenMsgILSupport" BO_ 2463978687 "Yes";
BA_ "GenMsgSendType" BO_ 2463978687 "Cyclic";
BA_ "VFrameFormat" BO_ 2463978687 "ExtendedCAN_FD";
BA_ "GenMsgCycleTime" BO_ 916 160;
BA_ "GenMsgDelayTime" BO_ 916 10;
BA_ "GenMsgILSupport" BO_ 916 "Yes";
BA_ "GenMsgPDUConstants" BO_ 916 "0x47,0x94,0x92,0x6a,0x67,0xb5,0x0d,0x38,0xe3,0x8a,0x5d,0xb4,0x54,0xab,0xae,0x27";
BA_ "GenMsgSendType" BO_ 916 "Cyclic";
BA_ "VFrameFormat" BO_ 916 "StandardCAN_FD";
BA_ "GenMsgCycleTime" BO_ 1361 200;
BA_ "GenMsgDelayTime" BO_ 1361 50;
BA_ "GenMsgILSupport" BO_ 1361 "Yes";
BA_ "GenMsgSendType" BO_ 1361 "Cyclic";
BA_ "VFrameFormat" BO_ 1361 "StandardCAN_FD";
BA_ "MsgType" BO_ 2617028096 "EID";
BA_ "VFrameFormat" BO_ 2617028096 "ExtendedCAN_FD";
BA_ "MsgType" BO_ 2617028097 "EID";
BA_ "VFrameFormat" BO_ 2617028097 "ExtendedCAN_FD";
BA_ "MsgType" BO_ 2617239040 "EID";
BA_ "VFrameFormat" BO_ 2617239040 "ExtendedCAN_FD";
BA_ "MsgType" BO_ 2617239041 "EID";
BA_ "VFrameFormat" BO_ 2617239041 "ExtendedCAN_FD";
BA_ "MsgType" BO_ 2617239042 "EID";
BA_ "VFrameFormat" BO_ 2617239042 "ExtendedCAN_FD";
BA_ "MsgType" BO_ 2617239043 "EID";
BA_ "VFrameFormat" BO_ 2617239043 "ExtendedCAN_FD";
BA_ "MsgType" BO_ 2617239044 "EID";
BA_ "VFrameFormat" BO_ 2617239044 "ExtendedCAN_FD";
BA_ "MsgType" BO_ 2617122304 "EID";
BA_ "VFrameFormat" BO_ 2617122304 "ExtendedCAN_FD";
BA_ "MsgType" BO_ 2617122305 "EID";
BA_ "VFrameFormat" BO_ 2617122305 "ExtendedCAN_FD";
BA_ "MsgType" BO_ 2617122306 "EID";
BA_ "VFrameFormat" BO_ 2617122306 "ExtendedCAN_FD";
BA_ "MsgType" BO_ 2617122307 "EID";
BA_ "VFrameFormat" BO_ 2617122307 "ExtendedCAN_FD";
BA_ "MsgType" BO_ 2617122308 "EID";
BA_ "VFrameFormat" BO_ 2617122308 "ExtendedCAN_FD";
BA_ "MsgType" BO_ 2617226768 "EID";
BA_ "VFrameFormat" BO_ 2617226768 "ExtendedCAN_FD";
BA_ "MsgType" BO_ 2617226769 "EID";
BA_ "VFrameFormat" BO_ 2617226769 "ExtendedCAN_FD";
BA_ "GenMsgCycleTime" BO_ 1411 200;
BA_ "GenMsgCycleTimeFast" BO_ 1411 50;
BA_ "GenMsgDelayTime" BO_ 1411 20;
BA_ "GenMsgILSupport" BO_ 1411 "Yes";
BA_ "GenMsgNrOfRepetition" BO_ 1411 3;
BA_ "GenMsgSendType" BO_ 1411 "Cyclic";
BA_ "VFrameFormat" BO_ 1411 "StandardCAN_FD";
BA_ "GenMsgCycleTime" BO_ 246 10;
BA_ "GenMsgILSupport" BO_ 246 "Yes";
BA_ "GenMsgPDUConstants" BO_ 246 "0x89,0xd6,0xf6,0xdd,0xe7,0x74,0x0f,0xd2,0x26,0x5a,0x44,0x70,0xd5,0x67,0x79,0x3d";
BA_ "GenMsgSendType" BO_ 246 "Cyclic";
BA_ "VFrameFormat" BO_ 246 "StandardCAN_FD";
BA_ "GenMsgCycleTime" BO_ 190 10;
BA_ "GenMsgILSupport" BO_ 190 "Yes";
BA_ "GenMsgPDUConstants" BO_ 190 "0x18,0x71,0x10,0x8d,0xd7,0xaa,0xb0,0x78,0xac,0x12,0xae,0x0c,0xdd,0xf1,0x85,0x68";
BA_ "GenMsgSendType" BO_ 190 "Cyclic";
BA_ "VFrameFormat" BO_ 190 "StandardCAN_FD";
BA_ "GenMsgCycleTime" BO_ 2463978666 100;
BA_ "GenMsgILSupport" BO_ 2463978666 "Yes";
BA_ "GenMsgSendType" BO_ 2463978666 "Cyclic";
BA_ "VFrameFormat" BO_ 2463978666 "ExtendedCAN_FD";
BA_ "GenMsgChkConstant" BO_ 1601 71;
BA_ "GenMsgCycleTime" BO_ 1601 1000;
BA_ "GenMsgILSupport" BO_ 1601 "Yes";
BA_ "GenMsgPDUConstants" BO_ 1601 "0x47,0x47,0x47,0x47,0x47,0x47,0x47,0x47,0x47,0x47,0x47,0x47,0x47,0x47,0x47,0x47";
BA_ "GenMsgSendType" BO_ 1601 "Cyclic";
BA_ "VFrameFormat" BO_ 1601 "StandardCAN_FD";
BA_ "GenMsgCycleTime" BO_ 1155 500;
BA_ "GenMsgDelayTime" BO_ 1155 50;
BA_ "GenMsgILSupport" BO_ 1155 "Yes";
BA_ "GenMsgSendType" BO_ 1155 "Cyclic";
BA_ "VFrameFormat" BO_ 1155 "StandardCAN_FD";
BA_ "GenMsgCycleTime" BO_ 2527679686 2000;
BA_ "GenMsgDelayTime" BO_ 2527679686 100;
BA_ "GenMsgILSupport" BO_ 2527679686 "Yes";
BA_ "GenMsgSendType" BO_ 2527679686 "Cyclic";
BA_ "VFrameFormat" BO_ 2527679686 "ExtendedCAN_FD";
BA_ "GenMsgILSupport" BO_ 22 "Yes";
BA_ "VFrameFormat" BO_ 22 "StandardCAN_FD";
BA_ "GenMsgILSupport" BO_ 24 "Yes";
BA_ "VFrameFormat" BO_ 24 "StandardCAN_FD";
BA_ "GenMsgCycleTime" BO_ 339 200;
BA_ "GenMsgDelayTime" BO_ 339 10;
BA_ "GenMsgILSupport" BO_ 339 "Yes";
BA_ "GenMsgPDUConstants" BO_ 339 "0x03,0x13,0x23,0x7a,0x40,0x51,0x68,0xba,0xa8,0xbe,0x55,0x02,0x11,0x31,0x76,0xec";
BA_ "GenMsgSendType" BO_ 339 "Cyclic";
BA_ "VFrameFormat" BO_ 339 "StandardCAN_FD";
BA_ "GenMsgCycleTime" BO_ 2600468501 200;
BA_ "GenMsgCycleTimeFast" BO_ 2600468501 10;
BA_ "NmhMessage" BO_ 2600468501 "Yes";
BA_ "MsgType" BO_ 2600468501 "NMH";
BA_ "CANFD_BRS" BO_ 2600468501 "0";
BA_ "VFrameFormat" BO_ 2600468501 "ExtendedCAN";
BA_ "GenMsgCycleTime" BO_ 2600468604 200;
BA_ "GenMsgCycleTimeFast" BO_ 2600468604 10;
BA_ "NmhMessage" BO_ 2600468604 "Yes";
BA_ "MsgType" BO_ 2600468604 "NMH";
BA_ "CANFD_BRS" BO_ 2600468604 "0";
BA_ "VFrameFormat" BO_ 2600468604 "ExtendedCAN";
BA_ "GenMsgCycleTime" BO_ 2600468496 200;
BA_ "GenMsgCycleTimeFast" BO_ 2600468496 10;
BA_ "NmhMessage" BO_ 2600468496 "Yes";
BA_ "MsgType" BO_ 2600468496 "NMH";
BA_ "CANFD_BRS" BO_ 2600468496 "0";
BA_ "VFrameFormat" BO_ 2600468496 "ExtendedCAN";
BA_ "GenMsgCycleTime" BO_ 2600468664 200;
BA_ "GenMsgCycleTimeFast" BO_ 2600468664 10;
BA_ "NmhMessage" BO_ 2600468664 "Yes";
BA_ "MsgType" BO_ 2600468664 "NMH";
BA_ "CANFD_BRS" BO_ 2600468664 "0";
BA_ "VFrameFormat" BO_ 2600468664 "ExtendedCAN";
BA_ "GenMsgCycleTime" BO_ 2600468598 200;
BA_ "GenMsgCycleTimeFast" BO_ 2600468598 10;
BA_ "NmhMessage" BO_ 2600468598 "Yes";
BA_ "MsgType" BO_ 2600468598 "NMH";
BA_ "CANFD_BRS" BO_ 2600468598 "0";
BA_ "VFrameFormat" BO_ 2600468598 "ExtendedCAN";
BA_ "GenMsgCycleTime" BO_ 2600468733 200;
BA_ "GenMsgCycleTimeFast" BO_ 2600468733 10;
BA_ "NmhMessage" BO_ 2600468733 "Yes";
BA_ "MsgType" BO_ 2600468733 "NMH";
BA_ "CANFD_BRS" BO_ 2600468733 "0";
BA_ "VFrameFormat" BO_ 2600468733 "ExtendedCAN";
BA_ "DiagRequest" BO_ 2621440533 "Yes";
BA_ "MsgType" BO_ 2621440533 "ISO-TP";
BA_ "VFrameFormat" BO_ 2621440533 "ExtendedCAN_FD";
BA_ "DiagResponse" BO_ 2621571605 "Yes";
BA_ "MsgType" BO_ 2621571605 "ISO-TP";
BA_ "VFrameFormat" BO_ 2621571605 "ExtendedCAN_FD";
BA_ "DiagRequest" BO_ 2621440636 "Yes";
BA_ "MsgType" BO_ 2621440636 "ISO-TP";
BA_ "VFrameFormat" BO_ 2621440636 "ExtendedCAN_FD";
BA_ "DiagResponse" BO_ 2621571708 "Yes";
BA_ "MsgType" BO_ 2621571708 "ISO-TP";
BA_ "VFrameFormat" BO_ 2621571708 "ExtendedCAN_FD";
BA_ "DiagRequest" BO_ 2621440696 "Yes";
BA_ "MsgType" BO_ 2621440696 "ISO-TP";
BA_ "VFrameFormat" BO_ 2621440696 "ExtendedCAN_FD";
BA_ "DiagResponse" BO_ 2621571768 "Yes";
BA_ "MsgType" BO_ 2621571768 "ISO-TP";
BA_ "VFrameFormat" BO_ 2621571768 "ExtendedCAN_FD";
BA_ "DiagState" BO_ 2621506048 "Yes";
BA_ "MsgType" BO_ 2621506048 "ISO-TP";
BA_ "VFrameFormat" BO_ 2621506048 "ExtendedCAN_FD";
BA_ "DiagRequest" BO_ 2621440630 "Yes";
BA_ "MsgType" BO_ 2621440630 "ISO-TP";
BA_ "VFrameFormat" BO_ 2621440630 "ExtendedCAN_FD";
BA_ "DiagResponse" BO_ 2621571702 "Yes";
BA_ "MsgType" BO_ 2621571702 "ISO-TP";
BA_ "VFrameFormat" BO_ 2621571702 "ExtendedCAN_FD";
BA_ "DiagState" BO_ 2564502513 "Yes";
BA_ "MsgType" BO_ 2564502513 "ISO-TP";
BA_ "VFrameFormat" BO_ 2564502513 "ExtendedCAN_FD";
BA_ "DiagRequest" BO_ 2564425457 "Yes";
BA_ "MsgType" BO_ 2564425457 "ISO-TP";
BA_ "VFrameFormat" BO_ 2564425457 "ExtendedCAN_FD";
BA_ "DiagResponse" BO_ 2564485382 "Yes";
BA_ "MsgType" BO_ 2564485382 "ISO-TP";
BA_ "VFrameFormat" BO_ 2564485382 "ExtendedCAN_FD";
BA_ "DiagRequest" BO_ 2564425713 "Yes";
BA_ "MsgType" BO_ 2564425713 "ISO-TP";
BA_ "VFrameFormat" BO_ 2564425713 "ExtendedCAN_FD";
BA_ "DiagResponse" BO_ 2564485383 "Yes";
BA_ "MsgType" BO_ 2564485383 "ISO-TP";
BA_ "VFrameFormat" BO_ 2564485383 "ExtendedCAN_FD";
BA_ "DiagRequest" BO_ 2564424177 "Yes";
BA_ "MsgType" BO_ 2564424177 "ISO-TP";
BA_ "VFrameFormat" BO_ 2564424177 "ExtendedCAN_FD";
BA_ "DiagResponse" BO_ 2564485377 "Yes";
BA_ "MsgType" BO_ 2564485377 "ISO-TP";
BA_ "VFrameFormat" BO_ 2564485377 "ExtendedCAN_FD";
BA_ "GenMsgCycleTime" BO_ 627 100;
BA_ "GenMsgDelayTime" BO_ 627 10;
BA_ "GenMsgILSupport" BO_ 627 "Yes";
BA_ "GenMsgPDUConstants" BO_ 627 "0xc6,0x40,0x32,0xbe,0xc7,0x76,0x16,0x17,0x05,0xd8,0xab,0x52,0x45,0x35,0xf1,0x1d";
BA_ "GenMsgSendType" BO_ 627 "Cyclic";
BA_ "VFrameFormat" BO_ 627 "StandardCAN_FD";
BA_ "GenMsgCycleTime" BO_ 2463978709 500;
BA_ "GenMsgDelayTime" BO_ 2463978709 50;
BA_ "GenMsgILSupport" BO_ 2463978709 "Yes";
BA_ "GenMsgSendType" BO_ 2463978709 "Cyclic";
BA_ "VFrameFormat" BO_ 2463978709 "ExtendedCAN_FD";
BA_ "GenMsgCycleTime" BO_ 2589283656 500;
BA_ "GenMsgDelayTime" BO_ 2589283656 100;
BA_ "GenMsgILSupport" BO_ 2589283656 "Yes";
BA_ "GenMsgSendType" BO_ 2589283656 "Cyclic";
BA_ "VFrameFormat" BO_ 2589283656 "ExtendedCAN_FD";
BA_ "GenMsgCycleTime" BO_ 2527679741 240;
BA_ "GenMsgILSupport" BO_ 2527679741 "Yes";
BA_ "GenMsgPDUConstants" BO_ 2527679741 "0x9d,0xe8,0x36,0xa1,0xca,0x3b,0x1d,0x33,0xe0,0xd5,0xbb,0x5f,0xae,0x3c,0x31,0x9f";
BA_ "GenMsgSendType" BO_ 2527679741 "Cyclic";
BA_ "VFrameFormat" BO_ 2527679741 "ExtendedCAN_FD";
BA_ "GenMsgCycleTime" BO_ 518 20;
BA_ "GenMsgILSupport" BO_ 518 "Yes";
BA_ "GenMsgSendType" BO_ 518 "Cyclic";
BA_ "VFrameFormat" BO_ 518 "StandardCAN_FD";
BA_ "GenMsgCycleTime" BO_ 2527679685 2000;
BA_ "GenMsgDelayTime" BO_ 2527679685 100;
BA_ "GenMsgILSupport" BO_ 2527679685 "Yes";
BA_ "GenMsgSendType" BO_ 2527679685 "Cyclic";
BA_ "VFrameFormat" BO_ 2527679685 "ExtendedCAN_FD";
BA_ "GenMsgCycleTime" BO_ 319 200;
BA_ "GenMsgDelayTime" BO_ 319 20;
BA_ "GenMsgILSupport" BO_ 319 "Yes";
BA_ "GenMsgSendType" BO_ 319 "Cyclic";
BA_ "CANFD_BRS" BO_ 319 "0";
BA_ "GenMsgCycleTime" BO_ 1122 150;
BA_ "GenMsgILSupport" BO_ 1122 "Yes";
BA_ "GenMsgSendType" BO_ 1122 "Cyclic";
BA_ "VFrameFormat" BO_ 1122 "StandardCAN_FD";
BA_ "GenMsgCycleTime" BO_ 1123 150;
BA_ "GenMsgILSupport" BO_ 1123 "Yes";
BA_ "GenMsgSendType" BO_ 1123 "Cyclic";
BA_ "VFrameFormat" BO_ 1123 "StandardCAN_FD";
BA_ "GenMsgCycleTime" BO_ 1124 150;
BA_ "GenMsgILSupport" BO_ 1124 "Yes";
BA_ "GenMsgSendType" BO_ 1124 "Cyclic";
BA_ "VFrameFormat" BO_ 1124 "StandardCAN_FD";
BA_ "GenMsgCycleTime" BO_ 591 40;
BA_ "GenMsgILSupport" BO_ 591 "Yes";
BA_ "GenMsgSendType" BO_ 591 "Cyclic";
BA_ "VFrameFormat" BO_ 591 "StandardCAN_FD";
BA_ "DiagRequest" BO_ 2033 "Yes";
BA_ "MsgType" BO_ 2033 "ISO-TP";
BA_ "CANFD_BRS" BO_ 2033 "0";
BA_ "DiagResponse" BO_ 2041 "Yes";
BA_ "MsgType" BO_ 2041 "ISO-TP";
BA_ "CANFD_BRS" BO_ 2041 "0";
BA_ "GenMsgCycleTime" BO_ 980 1000;
BA_ "GenMsgCycleTimeFast" BO_ 980 100;
BA_ "GenMsgDelayTime" BO_ 980 50;
BA_ "GenMsgILSupport" BO_ 980 "Yes";
BA_ "GenMsgNrOfRepetition" BO_ 980 5;
BA_ "GenMsgPDUConstants" BO_ 980 "0xc3,0x79,0xbf,0xdb,0xe9,0x11,0x46,0x86,0x69,0xb6,0x9b,0x29,0x15,0x9c,0x45,0x0d";
BA_ "GenMsgSendType" BO_ 980 "Cyclic";
BA_ "VFrameFormat" BO_ 980 "StandardCAN_FD";
BA_ "GenMsgDelayTime" BO_ 2464153718 50;
BA_ "GenMsgILSupport" BO_ 2464153718 "Yes";
BA_ "VFrameFormat" BO_ 2464153718 "ExtendedCAN_FD";
BA_ "GenMsgDelayTime" BO_ 2464284790 50;
BA_ "GenMsgILSupport" BO_ 2464284790 "Yes";
BA_ "VFrameFormat" BO_ 2464284790 "ExtendedCAN_FD";
BA_ "GenMsgCycleTime" BO_ 1413 1000;
BA_ "GenMsgDelayTime" BO_ 1413 10;
BA_ "GenMsgILSupport" BO_ 1413 "Yes";
BA_ "GenMsgSendType" BO_ 1413 "Cyclic";
BA_ "VFrameFormat" BO_ 1413 "StandardCAN_FD";
BA_ "GenMsgCycleTime" BO_ 2589283396 500;
BA_ "GenMsgILSupport" BO_ 2589283396 "Yes";
BA_ "GenMsgSendType" BO_ 2589283396 "Cyclic";
BA_ "VFrameFormat" BO_ 2589283396 "ExtendedCAN_FD";
BA_ "GenMsgCycleTime" BO_ 1019 80;
BA_ "GenMsgILSupport" BO_ 1019 "Yes";
BA_ "GenMsgSendType" BO_ 1019 "Cyclic";
BA_ "VFrameFormat" BO_ 1019 "StandardCAN_FD";
BA_ "GenMsgCycleTime" BO_ 1716 200;
BA_ "GenMsgILSupport" BO_ 1716 "Yes";
BA_ "GenMsgSendType" BO_ 1716 "Cyclic";
BA_ "VFrameFormat" BO_ 1716 "StandardCAN_FD";
BA_ "GenMsgCycleTime" BO_ 261 20;
BA_ "GenMsgILSupport" BO_ 261 "Yes";
BA_ "GenMsgPDUConstants" BO_ 261 "0xde,0x0e,0xa7,0x1d,0xc3,0x83,0xbd,0x82,0x8c,0xa2,0x0c,0x7b,0x4d,0x3c,0x58,0x79";
BA_ "GenMsgSendType" BO_ 261 "Cyclic";
BA_ "VFrameFormat" BO_ 261 "StandardCAN_FD";
BA_ "GenMsgCycleTime" BO_ 313 20;
BA_ "GenMsgILSupport" BO_ 313 "Yes";
BA_ "GenMsgPDUConstants" BO_ 313 "0xed,0x03,0x1c,0x13,0xc6,0x23,0x78,0x7a,0x8b,0x40,0x14,0x51,0xbf,0x68,0x32,0xba";
BA_ "GenMsgSendType" BO_ 313 "Cyclic";
BA_ "VFrameFormat" BO_ 313 "StandardCAN_FD";
BA_ "GenMsgCycleTime" BO_ 2463978663 200;
BA_ "GenMsgDelayTime" BO_ 2463978663 40;
BA_ "GenMsgILSupport" BO_ 2463978663 "Yes";
BA_ "GenMsgSendType" BO_ 2463978663 "Cyclic";
BA_ "VFrameFormat" BO_ 2463978663 "ExtendedCAN_FD";
BA_ "GenMsgChkConstant" BO_ 181 228;
BA_ "GenMsgCycleTime" BO_ 181 10;
BA_ "GenMsgILSupport" BO_ 181 "Yes";
BA_ "GenMsgPDUConstants" BO_ 181 "0xe4,0xe4,0xe4,0xe4,0xe4,0xe4,0xe4,0xe4,0xe4,0xe4,0xe4,0xe4,0xe4,0xe4,0xe4,0xe4";
BA_ "GenMsgSendType" BO_ 181 "Cyclic";
BA_ "VFrameFormat" BO_ 181 "StandardCAN_FD";
BA_ "GenMsgCycleTime" BO_ 2463978687 1000;
BA_ "GenMsgDelayTime" BO_ 2463978687 100;
BA_ "GenMsgILSupport" BO_ 2463978687 "Yes";
BA_ "GenMsgSendType" BO_ 2463978687 "Cyclic";
BA_ "VFrameFormat" BO_ 2463978687 "ExtendedCAN_FD";
BA_ "GenMsgCycleTime" BO_ 916 160;
BA_ "GenMsgDelayTime" BO_ 916 10;
BA_ "GenMsgILSupport" BO_ 916 "Yes";
BA_ "GenMsgPDUConstants" BO_ 916 "0x47,0x94,0x92,0x6a,0x67,0xb5,0x0d,0x38,0xe3,0x8a,0x5d,0xb4,0x54,0xab,0xae,0x27";
BA_ "GenMsgSendType" BO_ 916 "Cyclic";
BA_ "VFrameFormat" BO_ 916 "StandardCAN_FD";
BA_ "GenMsgCycleTime" BO_ 1361 200;
BA_ "GenMsgDelayTime" BO_ 1361 50;
BA_ "GenMsgILSupport" BO_ 1361 "Yes";
BA_ "GenMsgSendType" BO_ 1361 "Cyclic";
BA_ "VFrameFormat" BO_ 1361 "StandardCAN_FD";
BA_ "MsgType" BO_ 2617028096 "EID";
BA_ "VFrameFormat" BO_ 2617028096 "ExtendedCAN_FD";
BA_ "MsgType" BO_ 2617028097 "EID";
BA_ "VFrameFormat" BO_ 2617028097 "ExtendedCAN_FD";
BA_ "MsgType" BO_ 2617239040 "EID";
BA_ "VFrameFormat" BO_ 2617239040 "ExtendedCAN_FD";
BA_ "MsgType" BO_ 2617239041 "EID";
BA_ "VFrameFormat" BO_ 2617239041 "ExtendedCAN_FD";
BA_ "MsgType" BO_ 2617239042 "EID";
BA_ "VFrameFormat" BO_ 2617239042 "ExtendedCAN_FD";
BA_ "MsgType" BO_ 2617239043 "EID";
BA_ "VFrameFormat" BO_ 2617239043 "ExtendedCAN_FD";
BA_ "MsgType" BO_ 2617239044 "EID";
BA_ "VFrameFormat" BO_ 2617239044 "ExtendedCAN_FD";
BA_ "MsgType" BO_ 2617122304 "EID";
BA_ "VFrameFormat" BO_ 2617122304 "ExtendedCAN_FD";
BA_ "MsgType" BO_ 2617122305 "EID";
BA_ "VFrameFormat" BO_ 2617122305 "ExtendedCAN_FD";
BA_ "MsgType" BO_ 2617122306 "EID";
BA_ "VFrameFormat" BO_ 2617122306 "ExtendedCAN_FD";
BA_ "MsgType" BO_ 2617122307 "EID";
BA_ "VFrameFormat" BO_ 2617122307 "ExtendedCAN_FD";
BA_ "MsgType" BO_ 2617122308 "EID";
BA_ "VFrameFormat" BO_ 2617122308 "ExtendedCAN_FD";
BA_ "MsgType" BO_ 2617226768 "EID";
BA_ "VFrameFormat" BO_ 2617226768 "ExtendedCAN_FD";
BA_ "MsgType" BO_ 2617226769 "EID";
BA_ "VFrameFormat" BO_ 2617226769 "ExtendedCAN_FD";
BA_ "GenMsgCycleTime" BO_ 1411 200;
BA_ "GenMsgCycleTimeFast" BO_ 1411 50;
BA_ "GenMsgDelayTime" BO_ 1411 20;
BA_ "GenMsgILSupport" BO_ 1411 "Yes";
BA_ "GenMsgNrOfRepetition" BO_ 1411 3;
BA_ "GenMsgSendType" BO_ 1411 "Cyclic";
BA_ "VFrameFormat" BO_ 1411 "StandardCAN_FD";
VAL_ 246 TS_Faktor_Radmomente 0 "Faktor_1NM" 1 "Faktor_2NM" 2 "Faktor_3NM" 3 "Faktor_4NM";
VAL_ 246 TS_Status_MomRad_Ist 0 "FuSi_hohe_Genauigkeit" 1 "FuSi_niedrige_Genauigkeit" 2 "QM_fehlerfrei" 3 "QM_mit_Fehlern";
VAL_ 246 TS_MomRad_verfuegb_maxReku_Summe 4094 "Init" 4095 "Fehler";
VAL_ 246 TS_MomRad_Ist 8190 "Init";
VAL_ 246 TS_MomRad_Soll_Summe 8190 "Init";
VAL_ 246 TS_MomRad_Wunsch 8190 "Init";
VAL_ 246 TS_MomRad_Wunsch_sek 8190 "Init" 8191 "Fehler";
VAL_ 246 TS_MomRad_verfuegb_max 4094 "Init";
VAL_ 246 TS_MomRad_verfuegb_max_sek 4094 "Init" 4095 "Fehler";
VAL_ 246 TS_MomRad_verfuegb_maxReku 4094 "Init";
VAL_ 246 TS_MomRad_verfuegb_maxReku_sek 4094 "Init" 4095 "Fehler";
VAL_ 246 TS_MomRad_Ist_sek 8190 "Init" 8191 "Fehler";
VAL_ 246 TS_Allrad_Anteil_sek 510 "Init" 511 "Fehler";
VAL_ 246 FDR_Allrad_Anteil_max_sek 510 "Init" 511 "Fehler";
VAL_ 246 FDR_Allrad_Anteil_min_sek 510 "Init" 511 "Fehler";
VAL_ 246 FDR_MomRad_Eingriff 8190 "Init" 8191 "Fehler";
VAL_ 246 FDR_Status_Eingriff 0 "kein_Eingriff" 1 "Eingriff";
VAL_ 246 FDR_MomRad_Eingriff_sek 8190 "Init" 8191 "Fehler";
VAL_ 246 FDR_Status_Eingriff_sek 0 "kein_Eingriff" 1 "Eingriff";
VAL_ 190 MO_EM1_MinDrehzahl 16383 "Init";
VAL_ 190 MO_EM1_MaxDrehzahl 16383 "Init";
VAL_ 190 MO_EM1_DynLimit_AR 255 "Init";
VAL_ 190 MO_EM1_Periode_AR 255 "Init";
VAL_ 190 MO_EM1_SollMoment 4094 "Init";
VAL_ 190 MO_EM1_Sollmodus 8 "Freilauf" 0 "Standby" 1 "Momentenreg" 2 "Int_Drehzahlreg" 3 "Spannungsreg" 4 "Ext_Drehzahlreg" 6 "Kalibrierung" 7 "Sonderbremsbetrieb" 15 "Initialisierung";
VAL_ 190 MO_EM1_Min_Leistung 16382 "Init";
VAL_ 190 MO_EM1_Max_Leistung 16382 "Init";
VAL_ 190 MO_EM1_Min_Strom_Lim 8190 "Init";
VAL_ 190 MO_EM1_Max_Strom_Lim 8190 "Init";
VAL_ 190 MO_EM1_AR_Anf 0 "AR_aus" 2 "AR_D2T2" 3 "AR_RDR" 4 "AR_IRDR";
VAL_ 190 MO_EM1_Kp_AR 511 "Init";
VAL_ 190 MO_EM1_SollSpannung 4095 "Init";
VAL_ 190 MO_EM2_MinDrehzahl 16383 "Init";
VAL_ 190 MO_EM2_MaxDrehzahl 16383 "Init";
VAL_ 190 MO_EM2_DynLimit_AR 255 "Init";
VAL_ 190 MO_EM2_Periode_AR 255 "Init";
VAL_ 190 MO_EM2_SollMoment 4094 "Init" 4095 "Fehler";
VAL_ 190 MO_EM2_Sollmodus 8 "Freilauf" 0 "Standby" 1 "Momentenreg" 2 "Int_Drehzahlreg" 3 "Spannungsreg" 4 "Ext_Drehzahlreg" 6 "Kalibrierung" 7 "Sonderbremsbetrieb" 15 "Initialisierung";
VAL_ 190 MO_EM2_Min_Leistung 16382 "Init";
VAL_ 190 MO_EM2_Max_Leistung 16382 "Init";
VAL_ 190 MO_EM2_Min_Strom_Lim 8190 "Init";
VAL_ 190 MO_EM2_Max_Strom_Lim 8190 "Init";
VAL_ 190 MO_EM2_AR_Anf 0 "AR_aus" 2 "AR_D2T2" 3 "AR_RDR" 4 "AR_IRDR";
VAL_ 190 MO_EM2_SollSpannung 4095 "Init";
VAL_ 190 MO_DC_Max_Strom_HV 255 "Init";
VAL_ 190 MO_DC_SollSpannung_HV 255 "Init";
VAL_ 190 MO_EM1_Max_Moment 4094 "Init";
VAL_ 190 MO_EM1_Min_Moment 4094 "Init";
VAL_ 190 MO_EM2_Max_Moment 4094 "Init" 4095 "Fehler";
VAL_ 190 MO_EM2_Min_Moment 4094 "Init" 4095 "Fehler";
VAL_ 2463978666 MO_EM1_Min_Spannung_Lim 1022 "Init";
VAL_ 2463978666 MO_EM1_Max_Spannung_Lim 1022 "Init";
VAL_ 2463978666 MO_EM1_Min_Leistung_Gesamt 8190 "Init";
VAL_ 2463978666 MO_EM1_Max_Leistung_Gesamt 8190 "Init";
VAL_ 2463978666 MO_EM2_Min_Leistung_Gesamt 8190 "Init";
VAL_ 2463978666 MO_EM2_Max_Leistung_Gesamt 8190 "Init";
VAL_ 2463978666 MO_EM2_Min_Spannung_Lim 1022 "Init";
VAL_ 2463978666 MO_EM2_Max_Spannung_Lim 1022 "Init";
VAL_ 2463978666 MO_EM1_Generator_Leistung 254 "Init" 255 "Fehler";
VAL_ 2463978666 MO_Verbrauch_EM_Ges_Ueberlauf 0 "kein_Ueberlauf" 1 "Ueberlauf_Verbrauchssignal";
VAL_ 2463978666 MO_Rekuperation_EM_Ges_Ueberlauf 0 "kein_Ueberlauf" 1 "Ueberlauf_Reku_Leistungssignal";
VAL_ 2463978666 MO_Drehzahl_EM 8190 "Init_nichtverbaut" 8191 "Fehler";
VAL_ 2463978666 MO_Uebersetzung_EM 0 "keine_sichere_Uebertragung" 1022 "Init_nichtverbaut" 1023 "Fehler";
VAL_ 2463978666 MO_Drehzahl_EM_sek 8190 "Init_nichtverbaut" 8191 "Fehler";
VAL_ 2463978666 MO_Uebersetzung_EM_sek 0 "keine_sichere_Uebertragung" 1022 "Init" 1023 "Fehler";
VAL_ 1601 MO_Faktor_Momente_02 0 "nicht_belegt";
VAL_ 1601 MO_Hybridfahrzeug 0 "kein_Hybridfahrzeug" 1 "Mild_Hybrid" 2 "Full_Hybrid" 3 "PlugIn_Hybrid";
VAL_ 1601 MO_Getriebe_Code 8 "AL552_Allrad" 0 "Init" 2 "DL501" 3 "DL800" 4 "VL381" 5 "DL382_Front" 6 "DL382_Allrad" 7 "DL702" 9 "AL552_Front" 10 "AL651" 11 "AL551__AL951__AL1000_8A" 12 "PDK_PAG" 13 "AL551_Hybrid" 15 "Handschalter_konventionell" 16 "AQ250_160" 17 "AQ450" 18 "DQ200" 19 "DQ250" 20 "DQ500" 21 "SQ100" 22 "SQ200" 23 "DQ400E" 24 "DQ381" 25 "AL550" 26 "AQ300" 31 "DL800E" 32 "Single_Gear__ohne_GSG_WH_am_MSG" 33 "EQ550_2P";
VAL_ 1601 MO_StartStopp_Codiert 0 "Start_Stopp_nicht_verbaut" 1 "Start_Stopp_verbaut";
VAL_ 1601 MO_Anzeige_StSt_gueltig 0 "MO_Text_Motorstart_gueltig" 1 "Signale_MO_Anzeige_StSt_gueltig";
VAL_ 1601 MO_Anzahl_Zyl 0 "kein_Zylinder" 1 "1_Zylinder" 2 "2_Zylinder" 3 "3_Zylinder" 4 "4_Zylinder" 5 "5_Zylinder" 6 "6_Zylinder" 7 "7_Zylinder" 8 "8_Zylinder" 9 "9_Zylinder" 10 "10_Zylinder" 11 "11_Zylinder" 12 "12_Zylinder" 13 "15_Zylinder" 14 "16_Zylinder" 15 "18_Zylinder";
VAL_ 1601 MO_Kraftstoffart 0 "Diesel" 1 "Benzin_inkl_E25_E85" 2 "CNG" 3 "LPG" 4 "Wasserstoff" 5 "E100_Ethanol" 15 "kein_Verbrennungskraftstoff";
VAL_ 1601 MO_Ansaugsystem 0 "Turbo" 1 "Sauger";
VAL_ 1601 MO_OBD_Typ 0 "NoOBD_RdW" 1 "EOBD" 2 "US_OBD" 3 "reserviert";
VAL_ 1601 MO_DPF_verbaut 0 "kein_DPF_verbaut" 1 "DPF_verbaut";
VAL_ 1601 TSK_Codierung 0 "kein_Fahrgeschwindigkeitsregler" 1 "GRA" 2 "GRA_Plus" 3 "Basis_ACC" 4 "ACC_Follow_to_Stop" 5 "ACC_Stop_and_Go" 7 "Codierung_in_Plausibilisierungsphase";
VAL_ 1155 Mo_Powermeter_Grenze 4093 "OFF";
VAL_ 1155 MO_Text_Aktivierung_Antrieb 0 "keine_Anzeige" 1 "Ladestecker_nicht_fahrbereit" 2 "erneute_Aktivierung_erforderlich" 3 "Warten_Antrieb_wird_aktiviert" 4 "zum_Fahren_Bremse_und_Fahrstufe" 15 "Init";
VAL_ 1155 MO_Powermeter_Inszenierung_aktiv 0 "keine_Anzeige" 1 "Inszenierung_aktiv";
VAL_ 1155 MO_Powermeter_Charge_Grenze 1022 "Init" 1023 "Fehler";
VAL_ 1155 MO_Powermeter_Grenze_strategisch 4094 "Init" 4095 "Fehler";
VAL_ 1155 MO_Powermeter_untere_E_Grenze 4094 "Init" 4095 "Fehler";
VAL_ 1155 MO_Powermeter_obere_E_Grenze 4094 "Init" 4095 "Fehler";
VAL_ 2527679686 MRR_HR_ASM_Ereignis 0 "No_Event" 255 "ASM_Trigger";
VAL_ 2527679686 MRR_HR_ASM_Zeitstempel 255 "Init";
VAL_ 339 MO_HVEM_Eskalation 0 "keine_Eskalation_HVEM" 1 "Eskalation_HVEM";
VAL_ 339 MO_ErwGrenzen_Anf 0 "normal" 1 "erweitert";
VAL_ 339 MO_Fehler_Notentladung_Anf 0 "Init";
VAL_ 339 MO_HVEM_MaxLeistung 510 "Init";
VAL_ 339 MO_HVK_EmIstzustand 128 "HvFailBattOffReq" 0 "HvOff" 129 "HvFailBattOffOk" 1 "HvStbyReq" 18 "HvOnDrvReq" 138 "HvFailUCtlReq" 10 "HvOnIdle" 130 "HvFailBattOff" 2 "HvStbyOk" 19 "HvOnDrvOk" 67 "HvChOffReq" 3 "HvBattOnReq" 68 "HvChOffOk" 4 "HvBattOnOk" 20 "HvOnDrvRdy" 28 "HvStepUpReq" 29 "HvStepUpOk" 30 "HvStepUp" 38 "HvStepDownReq" 39 "HvStepDownOk" 40 "HvStepDown" 110 "HvDcDcFail" 46 "HvAcChPreReq" 47 "HvAcChPreOk" 48 "HvAcChReq" 49 "HvAcChOk" 50 "HvAcCh" 120 "HvElmOff" 56 "HvDcChPreReq" 57 "HvDcChPreOk" 58 "HvDcChReq" 59 "HvDcChOk" 60 "HvDcCh" 69 "HvOnIdleReq" 70 "HvOnIdleOk" 96 "HvCpntOffReq" 97 "HvCpntOffOk" 98 "HvBattOffReq" 99 "HvBattOffOk" 109 "HvDcDcFailOffReq" 119 "HvElmOffReq" 126 "HvFailCpntOffReq" 255 "Init" 127 "HvFailCpntOffOk" 139 "HvFailUCtlOk" 140 "HvFailUCtl" 150 "HvEmgcyOff";
VAL_ 339 MO_HVK_AntriebFehlerstatus 0 "Komponente_IO" 6 "Keine_Komponentenfunktion" 7 "Init";
VAL_ 339 MO_MVK_Bordnetz_Anf 0 "keine_Anforderung" 1 "Bordnetzaktivitaet_gefordert";
VAL_ 339 MO_HVK_AntriebZustand 0 "Antrieb_AUS" 1 "Antrieb_Startphase" 2 "E_Fahren" 3 "Hybrid_Fahren" 7 "Init";
VAL_ 339 MO_HVK_EmFehlerstatus 0 "Komponente_IO" 1 "Eingeschr_KompFkt_Teilbetrieb" 3 "Eingeschr_KompFkt_Interlock" 6 "Keine_Komponentenfunktion" 7 "Init";
VAL_ 339 MO_MVK_AntriebFehlerstatus 0 "Komponente_IO" 6 "Keine_Komponentenfunktion" 7 "Init";
VAL_ 339 MO_MVK_AntriebZustand 0 "Antrieb_AUS" 1 "Antrieb_Startphase" 2 "FreilaufMotorAus" 7 "Init";
VAL_ 339 MO_MVK_EmFehlerstatus 0 "Komponente_IO" 1 "Eingeschr_KompFkt_Teilbetrieb" 6 "Keine_Komponentenfunktion" 7 "Init";
VAL_ 339 MO_MVK_EmIstzustand 128 "MvFailBattOffReq" 0 "MvOff" 129 "MvFailBattOffOk" 1 "MvStbyReq" 18 "MvOnDrvReq" 138 "MvFailUCtlReq" 10 "MvOnIdle" 130 "MvFailBattOff" 2 "MvStbyOk" 19 "MvOnDrvOk" 3 "MvBattOnReq" 4 "MvBattOnOk" 20 "MvOnDrv" 28 "MvStepUpReq" 29 "MvStepUpOk" 30 "MvStepUp" 38 "MvStepDownReq" 39 "MvStepDownOk" 40 "MvStepDown" 96 "MvCpntOffReq" 97 "MvCpntOffOk" 98 "MvBattOffReq" 99 "MvBattOffOk" 109 "MvDcDcFailOffReq" 110 "MvDcDcFail" 119 "MvElmFailOffReq" 120 "MvElmFail" 126 "MvFailCpntOffReq" 255 "Init" 127 "MvFailCpntOffOk" 139 "MvFailUCtlOk" 140 "MvFailUCtl" 150 "MvEmgcyOff";
VAL_ 2600468501 NM_Airbag_01_CBV_AWB 0 "Passiver_WakeUp" 1 "Aktiver_WakeUp";
VAL_ 2600468501 NM_Airbag_01_CBV_CRI 0 "Standard_Layout" 1 "TNB_Layout";
VAL_ 2600468501 NM_Airbag_01_NM_State 1 "NM_RM_aus_BSM" 2 "NM_RM_aus_PBSM" 4 "NM_NO_aus_RM" 8 "NM_NO_aus_RS";
VAL_ 2600468501 NM_Airbag_01_Car_Wakeup 0 "Inaktiv" 1 "Car_Wakeup";
VAL_ 2600468501 NM_Airbag_01_UDS_CC 0 "Init" 1 "CC_aktiv";
VAL_ 2600468501 NM_Airbag_01_NM_aktiv_KL15 0 "Inaktiv" 1 "KL15_EIN";
VAL_ 2600468501 NM_Airbag_01_NM_aktiv_Diagnose 0 "Init" 1 "Diagnose_aktiv";
VAL_ 2600468501 NM_Airbag_01_NM_aktiv_Tmin 0 "Inaktiv" 1 "Mindestaktivzeit";
VAL_ 2600468501 NM_Airbag_01_CAB_V10 32768 "CAB_16_Licht" 16384 "CAB_15_Laden" 128 "CAB_08_MIB" 0 "Init" 64 "CAB_07_Connect" 8192 "CAB_14_VLAN_Infotainment" 32 "CAB_06_Anzeige" 4096 "CAB_13_VLAN_Connect" 16 "CAB_05_Komfort" 8 "CAB_04_Fahrerassistenz" 1 "CAB_01_Antrieb" 2 "CAB_02_Hybrid_Laden" 4 "CAB_03_Fahrwerk" 256 "CAB_09_Standheizung" 1024 "CAB_11_VLAN_Fahrerassistenz";
VAL_ 2600468604 NM_EMotor_01_CBV_AWB 0 "Passiver_WakeUp" 1 "Aktiver_WakeUp";
VAL_ 2600468604 NM_EMotor_01_CBV_CRI 0 "Standard_Layout" 1 "TNB_Layout";
VAL_ 2600468604 NM_EMotor_01_NM_State 1 "NM_RM_aus_BSM" 2 "NM_RM_aus_PBSM" 4 "NM_NO_aus_RM" 8 "NM_NO_aus_RS";
VAL_ 2600468604 NM_EMotor_01_Car_Wakeup 0 "Inaktiv" 1 "Car_Wakeup";
VAL_ 2600468604 NM_EMotor_01_UDS_CC 0 "Init" 1 "CC_aktiv";
VAL_ 2600468604 NM_EMotor_01_NM_aktiv_KL15 0 "Inaktiv" 1 "KL15_EIN";
VAL_ 2600468604 NM_EMotor_01_NM_aktiv_Diagnose 0 "Init" 1 "Diagnose_aktiv";
VAL_ 2600468604 NM_EMotor_01_NM_aktiv_Tmin 0 "Inaktiv" 1 "Mindestaktivzeit";
VAL_ 2600468604 NM_EMotor_01_keine_HV_Entl 1 "keine_HV_Entladung_moeglich";
VAL_ 2600468604 NM_EMotor_01_CAB_V10 32768 "CAB_16_Licht" 16384 "CAB_15_Laden" 128 "CAB_08_MIB" 0 "Init" 64 "CAB_07_Connect" 8192 "CAB_14_VLAN_Infotainment" 32 "CAB_06_Anzeige" 4096 "CAB_13_VLAN_Connect" 16 "CAB_05_Komfort" 8 "CAB_04_Fahrerassistenz" 1 "CAB_01_Antrieb" 2 "CAB_02_Hybrid_Laden" 4 "CAB_03_Fahrwerk" 256 "CAB_09_Standheizung" 1024 "CAB_11_VLAN_Fahrerassistenz";
VAL_ 2600468496 NM_Gateway_CBV_AWB 0 "Passiver_WakeUp" 1 "Aktiver_WakeUp";
VAL_ 2600468496 NM_Gateway_CBV_CRI 0 "Standard_Layout" 1 "TNB_Layout";
VAL_ 2600468496 NM_Gateway_NM_State 1 "NM_RM_aus_BSM" 2 "NM_RM_aus_PBSM" 4 "NM_NO_aus_RM" 32 "NM_RM_aus_NO" 16 "NM_RM_aus_RS" 8 "NM_NO_aus_RS";
VAL_ 2600468496 NM_Gateway_Car_Wakeup 0 "Inaktiv" 1 "Car_Wakeup";
VAL_ 2600468496 NM_Gateway_UDS_CC 0 "Init" 1 "CC_aktiv";
VAL_ 2600468496 NM_Gateway_NM_aktiv_KL15 0 "Inaktiv" 1 "KL15_EIN";
VAL_ 2600468496 NM_Gateway_NM_aktiv_Diagnose 0 "Init" 1 "Diagnose_aktiv";
VAL_ 2600468496 NM_Gateway_NM_aktiv_Tmin 0 "Inaktiv" 1 "Mindestaktivzeit";
VAL_ 2600468496 NM_Gateway_CAB_V10 32768 "CAB_16_Licht" 16384 "CAB_15_Laden" 128 "CAB_08_MIB" 0 "Init" 64 "CAB_07_Connect" 8192 "CAB_14_VLAN_Infotainment" 32 "CAB_06_Anzeige" 4096 "CAB_13_VLAN_Connect" 16 "CAB_05_Komfort" 8 "CAB_04_Fahrerassistenz" 1 "CAB_01_Antrieb" 2 "CAB_02_Hybrid_Laden" 4 "CAB_03_Fahrwerk" 256 "CAB_09_Standheizung" 1024 "CAB_11_VLAN_Fahrerassistenz";
VAL_ 2600468664 NM_LE2_CBV_AWB 0 "Passiver_WakeUp" 1 "Aktiver_WakeUp";
VAL_ 2600468664 NM_LE2_CBV_CRI 0 "Standard_Layout" 1 "TNB_Layout";
VAL_ 2600468664 NM_LE2_NM_State 1 "NM_RM_aus_BSM" 2 "NM_RM_aus_PBSM" 4 "NM_NO_aus_RM" 32 "NM_RM_aus_NO" 16 "NM_RM_aus_RS" 8 "NM_NO_aus_RS";
VAL_ 2600468664 NM_LE2_Car_Wakeup 0 "Inaktiv" 1 "Car_Wakeup";
VAL_ 2600468664 NM_LE2_UDS_CC 0 "Init" 1 "CC_aktiv";
VAL_ 2600468664 NM_LE2_NM_aktiv_KL15 0 "Inaktiv" 1 "KL15_EIN";
VAL_ 2600468664 NM_LE2_NM_aktiv_Diagnose 0 "Init" 1 "Diagnose_aktiv";
VAL_ 2600468664 NM_LE2_NM_aktiv_Tmin 0 "Inaktiv" 1 "Mindestaktivzeit";
VAL_ 2600468664 NM_LE2_keine_HV_entl 0 "Inaktiv" 1 "keine_HV_Entladung_moeglich";
VAL_ 2600468664 NM_LE2_CAB_V10 32768 "CAB_16_Licht" 16384 "CAB_15_Laden" 128 "CAB_08_MIB" 0 "Init" 64 "CAB_07_Connect" 8192 "CAB_14_VLAN_Infotainment" 32 "CAB_06_Anzeige" 4096 "CAB_13_VLAN_Connect" 16 "CAB_05_Komfort" 8 "CAB_04_Fahrerassistenz" 1 "CAB_01_Antrieb" 2 "CAB_02_Hybrid_Laden" 4 "CAB_03_Fahrwerk" 256 "CAB_09_Standheizung" 1024 "CAB_11_VLAN_Fahrerassistenz";
VAL_ 2600468598 NM_MO_01_CBV_AWB 0 "Passiver_WakeUp" 1 "Aktiver_WakeUp";
VAL_ 2600468598 NM_MO_01_CBV_CRI 0 "Standard_Layout" 1 "TNB_Layout";
VAL_ 2600468598 NM_MO_01_NM_State 1 "NM_RM_aus_BSM" 2 "NM_RM_aus_PBSM" 4 "NM_NO_aus_RM" 32 "NM_RM_aus_NO" 16 "NM_RM_aus_RS" 8 "NM_NO_aus_RS";
VAL_ 2600468598 NM_MO_01_Car_Wakeup 0 "Inaktiv" 1 "Car_Wakeup";
VAL_ 2600468598 NM_MO_01_UDS_CC 0 "Init" 1 "CC_aktiv";
VAL_ 2600468598 NM_MO_01_NM_aktiv_KL15 0 "Inaktiv" 1 "KL15_EIN";
VAL_ 2600468598 NM_MO_01_NM_aktiv_Diagnose 0 "Init" 1 "Diagnose_aktiv";
VAL_ 2600468598 NM_MO_01_NM_aktiv_Tmin 0 "Inaktiv" 1 "Mindestaktivzeit";
VAL_ 2600468598 NM_MO_01_NM_aktiv_Betankung 0 "kein_Nachlauf" 1 "Betankung_Drucktank";
VAL_ 2600468598 NM_MO_01_NM_aktiv_Waehlhebel 0 "kein_Nachlauf" 1 "Kommunikation_Waehlhebel";
VAL_ 2600468598 NM_MO_01_NM_aktiv_HV_Abschaltung 0 "kein_Nachlauf" 1 "Abschaltung_aktiv";
VAL_ 2600468598 NM_MO_01_NM_aktiv_Hochvolt 0 "kein_Nachlauf" 1 "Hochvolt_aktiv";
VAL_ 2600468598 NM_MO_01_CAB_V10 32768 "CAB_16_Licht" 16384 "CAB_15_Laden" 128 "CAB_08_MIB" 0 "Init" 64 "CAB_07_Connect" 8192 "CAB_14_VLAN_Infotainment" 32 "CAB_06_Anzeige" 4096 "CAB_13_VLAN_Connect" 16 "CAB_05_Komfort" 8 "CAB_04_Fahrerassistenz" 1 "CAB_01_Antrieb" 2 "CAB_02_Hybrid_Laden" 4 "CAB_03_Fahrwerk" 256 "CAB_09_Standheizung" 1024 "CAB_11_VLAN_Fahrerassistenz";
VAL_ 2600468733 NM_Waehlhebel_CBV_AWB 0 "Passiver_WakeUp" 1 "Aktiver_WakeUp";
VAL_ 2600468733 NM_Waehlhebel_CBV_CRI 0 "Standard_Layout" 1 "TNB_Layout";
VAL_ 2600468733 NM_Waehlhebel_NM_State 32 "NM_RM_aus_NO" 16 "NM_RM_aus_RS" 8 "NM_NO_aus_RS" 0 "Init" 1 "NM_RM_aus_BSM" 2 "NM_RM_aus_PBSM" 4 "NM_NO_aus_RM";
VAL_ 2600468733 NM_Waehlhebel_Car_Wakeup 0 "Inaktiv" 1 "Car_Wakeup";
VAL_ 2600468733 NM_Waehlhebel_UDS_CC 0 "Init" 1 "CC_aktiv";
VAL_ 2600468733 NM_Waehlhebel_NM_aktiv_KL15 0 "Inaktiv" 1 "KL15_EIN";
VAL_ 2600468733 NM_Waehlhebel_NM_aktiv_Diagnose 0 "Init" 1 "Diagnose_aktiv";
VAL_ 2600468733 NM_Waehlhebel_NM_aktiv_Tmin 0 "Inaktiv" 1 "Mindestaktivzeit";
VAL_ 2600468733 NM_Waehlhebel_CAB_V10 32768 "CAB_16_Licht" 16384 "CAB_15_Laden" 128 "CAB_08_MIB" 0 "Init" 64 "CAB_07_Connect" 8192 "CAB_14_VLAN_Infotainment" 32 "CAB_06_Anzeige" 4096 "CAB_13_VLAN_Connect" 16 "CAB_05_Komfort" 8 "CAB_04_Fahrerassistenz" 1 "CAB_01_Antrieb" 2 "CAB_02_Hybrid_Laden" 4 "CAB_03_Fahrwerk" 256 "CAB_09_Standheizung" 1024 "CAB_11_VLAN_Fahrerassistenz";
VAL_ 627 OCC_Stecker_Status 0 "Init" 1 "kein_Stecker_erkannt" 2 "Stecker_erkannt" 3 "Fehler";
VAL_ 627 OCC_Status_Spgfreiheit 0 "Init__ohne_Funktion" 1 "HV_Komponente_Spannungsfrei" 2 "HV_Komponente_nichtSpannungsfrei" 3 "Fehler";
VAL_ 627 OCC_DC_IstStrom 2046 "Init" 2047 "Fehler";
VAL_ 627 OCC_CC_Latchstatus_DC_GBT 0 "nicht_betaetigt" 1 "betaetigt" 2 "nicht_vorhanden" 6 "Init" 7 "Fehler";
VAL_ 627 OCC_Status_EoHVL 0 "Init" 1 "Keine_offene_HV_Leitung_erkannt" 2 "offene_HV_Leitung_erkannt" 3 "Fehler";
VAL_ 627 OCC_I_istAC_Netz_L1 510 "Init" 511 "Fehler";
VAL_ 627 OCC_PP_Latchstatus_A 0 "nicht_betaetigt" 1 "betaetigt" 2 "nicht_vorhanden" 6 "Init" 7 "Fehler";
VAL_ 627 OCC_PP_Latchstatus_B 0 "nicht_betaetigt" 1 "betaetigt" 2 "nicht_vorhanden" 6 "Init" 7 "Fehler";
VAL_ 627 OCC_I_istAC_Netz_L2 510 "Init" 511 "Fehler";
VAL_ 627 OCC_I_istAC_Netz_L3 509 "nicht_vorhanden" 510 "Init" 511 "Fehler";
VAL_ 627 OCC_IstModus 0 "Standby" 1 "Netzladung_aktiv" 2 "Rueckspeisung_aktiv" 3 "reserve" 4 "reserve" 5 "reserve" 6 "Init" 7 "Fehler";
VAL_ 627 OCC_CP_Status_A 0 "CP_nicht_erkannt" 1 "CP_erkannt" 2 "Init" 3 "Fehler";
VAL_ 627 OCC_CP_Status_B 0 "CP_nicht_erkannt" 1 "CP_erkannt" 2 "Init" 3 "Fehler";
VAL_ 627 OCC_IstSpannung_HV 1022 "Init" 1023 "Fehler";
VAL_ 627 OCC_PP_Status_A 0 "nicht_erkannt" 1 "erkannt" 2 "Init" 3 "Fehler";
VAL_ 627 OCC_PP_Status_B 0 "nicht_erkannt" 1 "erkannt" 2 "Init" 3 "Fehler";
VAL_ 627 OCC_CC_Status_DC_GBT 0 "nicht_erkannt" 1 "erkannt" 2 "Init" 3 "Fehler";
VAL_ 627 OCC_CC_Fehlerstatus_DC_GBT 0 "Init" 1 "kein_Fehler" 2 "Aktiv_Kurzschluss_nach_Masse" 3 "Aktiv_Kurzschluss_nach_12V" 4 "Fehler_in_Hardwarschaltung" 5 "Fehler_Ladedose" 6 "Fehler_Ladestecker" 7 "keine_GBT_DC_Ladedose" 8 "Fehler_Zwischenbereich_erkannt";
VAL_ 627 OCC_Temp_Sensor_Fehlerstatus_DC 0 "Init" 1 "Fehler_Sensor_defekt" 2 "kein_Fehler";
VAL_ 627 OCC_Temp_Sensor_Fehlerstatus_AC 0 "Init" 1 "Fehler_Kurzschluss" 2 "Warnung" 3 "kein_Fehler";
VAL_ 627 OCC_Temp_Sensor_Status 0 "Init" 1 "kein_Fehler" 2 "DC_Plus_Fehler" 3 "DC_Minus_Fehler" 4 "DC_Plus_und_DC_Minus_Fehler" 5 "Reserve" 6 "Reserve";
VAL_ 2463978709 OCC_CP_Tastgrad_A 1022 "Init" 1023 "Fehler";
VAL_ 2463978709 OCC_CP_Tastgrad_B 1022 "Init" 1023 "Fehler";
VAL_ 2463978709 OCC_CP_Frequenz_A 253 "keine_Frequenz_erkannt" 254 "Init" 255 "Fehler";
VAL_ 2463978709 OCC_CP_Frequenz_B 253 "keine_Frequenz_erkannt" 254 "Init" 255 "Fehler";
VAL_ 2463978709 OCC_CP_Spannung_A 510 "Init" 511 "Fehler";
VAL_ 2463978709 OCC_CP_Spannung_B 510 "Init" 511 "Fehler";
VAL_ 2463978709 OCC_CP_Fehlerstatus_A 0 "Messsystem_niO" 1 "Spannung_niO" 2 "Frequenz_niO" 3 "Tastgrad_niO" 4 "Init" 5 "Kein_Fehler" 6 "keine_CP_Ladedose";
VAL_ 2463978709 OCC_CP_Fehlerstatus_B 0 "Messsystem_niO" 1 "Spannung_niO" 2 "Frequenz_niO" 3 "Tastgrad_niO" 4 "Init" 5 "kein_Fehler" 6 "keine_CP_Ladedose";
VAL_ 2463978709 OCC_Temp_Ladedose_A_AC 254 "Init" 255 "Fehler";
VAL_ 2463978709 OCC_Temp_Ladedose_A_DC_minus 254 "Init" 255 "Fehler";
VAL_ 2463978709 OCC_Temp_Ladedose_A_DC_plus 254 "Init" 255 "Fehler";
VAL_ 2463978709 OCC_U_istAC_Netz_L1 510 "Init" 511 "Fehler";
VAL_ 2463978709 OCC_U_istAC_Netz_L2 510 "Init" 511 "Fehler";
VAL_ 2463978709 OCC_U_istAC_Netz_L3 509 "nicht_vorhanden" 510 "Init" 511 "Fehler";
VAL_ 2463978709 OCC_StatusVerEntriegelungAktor_A 0 "keine_Ansteuerung" 1 "entriegeln_wird_angesteuert" 2 "verriegeln_wird_angesteuert" 3 "maximale_WdhVersuche_erreicht" 4 "reserve" 5 "reserve" 6 "Init" 7 "Fehler";
VAL_ 2463978709 OCC_SteckerEntriegelung_Verbot_A 0 "kein_Verbot" 1 "Entriegelungsverbot_des_Steckers" 2 "reserve" 3 "Init";
VAL_ 2463978709 OCC_StatusVerEntriegelungAktor_B 0 "keine_Ansteuerung" 1 "entriegeln_wird_angesteuert" 2 "verriegeln_wird_angesteuert" 3 "maximale_WdhVersuche_erreicht" 4 "reserve" 5 "reserve" 6 "Init" 7 "Fehler";
VAL_ 2463978709 OCC_SteckerEntriegelung_Verbot_B 0 "kein_Verbot" 1 "Entriegelungsverbot_des_Steckers" 2 "reserve" 3 "Init";
VAL_ 2463978709 OCC_Verriegelung_Status_A 0 "entriegelt" 1 "verriegelt" 2 "zu_weit_gefahren_erkannt" 3 "verklemmt_erkannt" 4 "reserve" 5 "reserve" 6 "Init" 7 "Fehler";
VAL_ 2463978709 OCC_Verriegelung_Status_B 0 "entriegelt" 1 "verriegelt" 2 "zu_weit_gefahren_erkannt" 3 "verklemmt_erkannt" 4 "reserve" 5 "reserve" 6 "Init" 7 "Fehler";
VAL_ 2463978709 OCC_RtmWarnLadeKommunikation 0 "kein_Fehler" 1 "Fehler_Stufe_1" 2 "Fehler_Stufe_2" 3 "Fehler_Stufe_3" 4 "reserviert" 5 "reserviert" 6 "reserviert" 7 "reserviert";
VAL_ 2463978709 OCC_Ist_Wirkungsgrad 126 "Init" 127 "Fehler";
VAL_ 2463978709 OCC_PP_Max_Strom_A 0 "nicht_vorhanden" 1 "Wert_10A" 2 "Wert_13A" 3 "Wert_16A" 4 "Wert_20A" 5 "Wert_32A" 6 "Wert_63A" 7 "reserve" 8 "Init" 9 "Fehler";
VAL_ 2463978709 OCC_PP_Max_Strom_B 0 "nicht_vorhanden" 1 "Wert_10A" 2 "Wert_13A" 3 "Wert_16A" 4 "Wert_20A" 5 "Wert_32A" 6 "Wert_63A" 7 "reserve" 8 "Init" 9 "Fehler";
VAL_ 2463978709 OCC_DC_MaxStrom 2046 "Init" 2047 "Fehler";
VAL_ 2463978709 OCC_Derating_Temperatur 0 "kein_Derating_aktiv" 1 "Derating_aktiv";
VAL_ 2463978709 OCC_Fehlerzustand 0 "kein_Fehler_aktiv" 1 "Fehler_aktiv_Laden_beendet";
VAL_ 2463978709 OCC_Ladest_Entriegelungs_Verbot 0 "kein_Entriegelungsverbot" 1 "Entriegelungsverbot_Ladedose_A" 2 "Entriegelungsverbot_Ladedose_B" 3 "Entriegelungsverbot_beide_Ladedo" 4 "reserve" 5 "reserve" 6 "Init" 7 "Fehler";
VAL_ 2463978709 OCC_Netzfrequenz_EVU 509 "kein_Frequenz_erkannt" 510 "Init" 511 "Fehler";
VAL_ 2463978709 OCC_Warnzustand 0 "keine_Warnung" 1 "Warnung_aktiv";
VAL_ 2463978709 OCC_Kuehltemperatur 254 "Init" 255 "Fehler";
VAL_ 2463978709 OCC_PP_Fehlerstatus_A 0 "keinen_Fehler" 1 "Fehler_Zwischenbereich_erkannt" 2 "Aktiv_Kurzschluss_nach_Masse" 3 "Aktiv_Kurzschluss_nach_12V" 4 "Fehler_in_Hardwareschaltung" 5 "Fehler_Ladedose" 6 "Fehler_Ladestecker" 7 "keine_PP_Ladedose" 8 "Init";
VAL_ 2463978709 OCC_PP_Fehlerstatus_B 0 "kein_Fehler" 1 "Fehler_Zwischenbereich_erkannt" 2 "Aktiv_Kurzschluss_nach_Masse" 3 "Aktiv_Kurzschluss_nach_12V" 4 "Fehler_in_Hardwareschaltung" 5 "Fehler_Ladedose" 6 "Fehler_Ladestecker" 7 "keine_PP_Ladedose" 8 "Init";
VAL_ 2589283656 ORU_EM_Anfrage_freigegebeneNetze 0 "only_12V" 1 "networks_48V_and_12V" 2 "networks_HV_and_12V" 3 "networks_HV_and_48V_and_12V";
VAL_ 2589283656 ORU_Warnung 0 "keine_Anzeige" 1 "Update_unvollstaendig_Prio1" 2 "reserviert" 3 "reserviert";
VAL_ 2589283656 ORU_Status 0 "IDLE" 1 "PENDING" 2 "PREPARATION" 3 "PREPARATION_HV" 4 "RUNNING" 5 "RUNNING_HV" 6 "PENDING_NOTREADY";
VAL_ 2527679741 PAO_ON_Status 0 "LED_aus" 1 "LED_an" 2 "LED_blinkt" 3 "LED_defekt";
VAL_ 2527679741 PAO_OFF_Status 0 "LED_aus" 1 "LED_an" 2 "LED_blinkt" 3 "LED_defekt";
VAL_ 518 Parken_BKD_Anf 14 "Neutralwert" 15 "Fehler";
VAL_ 518 Parken_Verz_Anf 126 "Neutralwert" 127 "reserved";
VAL_ 518 Parken_Prefill_Anf 0 "keine_Anforderung" 1 "Prefill_Anforderung";
VAL_ 518 Parken_Warnruck_Anf 0 "Keine_Anforderung" 1 "schwacher_Warnruck" 2 "mittlerer_Warnruck" 3 "starker_Warnruck";
VAL_ 518 Parken_Verz_Anf_ASIL 0 "ASIL_QM" 1 "ASIL_A" 2 "ASIL_B" 3 "ASIL_C";
VAL_ 518 Parken_Warnruckeln_Anf 0 "keine_Anforderung" 1 "schwaches_Warnruckeln" 2 "mittleres_Warnruckeln" 3 "starkes_Warnruckeln";
VAL_ 518 Parken_beibehalten 0 "Parken_nicht_beibehalten" 1 "Parken_beibehalten" 2 "Init" 3 "Fehler";
VAL_ 518 Parken_Anforderung_HMS 0 "keine_Anforderung" 1 "Halten" 2 "Parken" 3 "Halten_standby" 4 "Anfahren" 5 "Loesen_ueber_Rampe" 6 "Parken_mit_P" 7 "reserviert";
VAL_ 518 Parken_Notstopp_Anf 0 "Ueberwachung_aus" 1 "Ueberwachung_ein" 2 "Notstopp_ausloesen";
VAL_ 518 Parken_Anhalteweg_Anf 1022 "Neutralwert" 1023 "Fehler";
VAL_ 518 Parken_aktives_System 0 "kein_aktives_System" 1 "Manoevrierassistent_Ueberwachung" 2 "IPA" 3 "fernbedientes_Parken" 4 "Manoevrierassistent" 5 "Manoevrierassistent_quer" 6 "Anhaengerrangierassistent" 7 "fernbedienter_Anhaengerrangierassistent";
VAL_ 518 Parken_max_Beschleunigung 0 "Inaktiv" 122 "Init" 127 "Fehler";
VAL_ 518 Parken_Blinker_li_Anf 0 "keine_Anforderung" 1 "Blinker_links_aktivieren";
VAL_ 518 Parken_QFK_KruemmSoll_VZ 0 "positiv" 1 "negativ";
VAL_ 518 Parken_QFK_AnfStat 1 "Init" 2 "Bereit" 4 "Eingriff";
VAL_ 518 Parken_Sollbeschleunigung 0 "Neutralwert";
VAL_ 518 Parken_Blinker_re_Anf 0 "keine_Anforderung" 1 "Blinker_rechts_aktivieren";
VAL_ 518 Parken_Status_IPA_TSK 1 "IPA_TSK_Init" 2 "IPA_TSK_Fehler" 4 "IPA_TSK_aktivierbar" 5 "IPA_TSK_pausiert" 6 "IPA_TSK_aktiv" 8 "IPA_TSK_funktionsbereit";
VAL_ 518 Parken_erhoehtes_Moment 0 "keine_Anforderung" 1 "Anforderung_Rampe1" 2 "Anforderung_Rampe2" 3 "Anforderung_Rampe3" 4 "Anforderung_Rampe4" 5 "Anforderung_Rampe5" 6 "Anforderung_Rampe6" 7 "Anforderung_Rampe7" 8 "Anforderung_Rampe8" 9 "Anforderung_Rampe9" 10 "Anforderung_Rampe10" 11 "Anforderung_Rampe11" 12 "Anforderung_Rampe12" 13 "Anforderung_Rampe13" 14 "Anforderung_Rampe14" 15 "Anforderung_Rampe15";
VAL_ 518 Parken_max_Geschwindigkeit 0 "Inaktiv" 251 "Init" 255 "Fehler";
VAL_ 518 Parken_Soll_Anhalteweg_Anf 1022 "Neutralwert" 1023 "Fehler";
VAL_ 518 Parken_Fahrstufenwunsch 0 "Init" 1 "Fahrstufe_beibehalten" 2 "Position_R" 3 "Position_D" 4 "Position_N";
VAL_ 518 IPA_TPA_Remote 0 "nicht_aktiv" 1 "aktiv" 2 "Uebergabe" 3 "Uebernahme";
VAL_ 518 IPA_TPA_Remote_Anf 0 "keine_Anforderung" 1 "Remote_Anforderung";
VAL_ 518 IPA_TPA_Fehler 0 "Init" 1 "ESC_Fehler" 2 "PPF_Fehler" 3 "VMM_Fehler" 4 "sonstiger_Fehler" 5 "temporaerer_Fehler";
VAL_ 518 IPA_TPA_Abbruch 8 "Ueberschreitung_vMax" 0 "Init" 1 "ESC_Fehler" 2 "PPF_Fehler" 3 "VMM_Fehler" 4 "sonstiger_Fehler" 5 "temporaerer_Fehler" 7 "Hindernis" 9 "Lenkeingriff_Fahrer" 10 "Tuer_offen" 11 "MH_HD_offen";
VAL_ 518 IPA_TPA_Status 8 "funktionsbereit" 0 "deaktiv" 1 "Init" 4 "startbereit" 6 "Regelung_aktiv" 15 "Error" 7 "Parkvorgang_abgeschlossen" 10 "Abbruch";
VAL_ 2527679685 PDC_ASM_Ereignis 0 "No_Event" 255 "ASM_Trigger";
VAL_ 2527679685 PDC_ASM_Zeitstempel 255 "Init";
VAL_ 319 PreCrash_Charisma_FahrPr 0 "keine_Funktion" 1 "Programm_1" 2 "Programm_2" 3 "Programm_3" 4 "Programm_4" 5 "Programm_5" 6 "Programm_6" 7 "Programm_7" 8 "Programm_8" 9 "Programm_9" 10 "Programm_10" 11 "Programm_11" 12 "Programm_12" 13 "Programm_13" 14 "Programm_14" 15 "Programm_15";
VAL_ 319 PreCrash_Charisma_Status 0 "Init" 1 "verfuegbar" 2 "nicht_verfuegbar" 3 "asynchron_durch_Fahrerwunsch";
VAL_ 319 PreCrash_Schiebedach_schliessen 0 "keine_Schliessung" 1 "Schliessung_angefordert";
VAL_ 319 PreCrash_Fenster_schliessen 0 "keine_Schliessung" 1 "Schliessung_angefordert";
VAL_ 319 PreCrash_Blinken 0 "keine_Blinkanforderung" 1 "Warnblinken" 2 "RECAS_Blinken" 3 "Notbremsblinken";
VAL_ 319 SC_PreSense_FCWP 0 "Warnung_gilt_fuer_Objekte" 1 "Warnung_gitl_fuer_Fussgaenger";
VAL_ 319 PreCrash_Tueren_Verriegeln 0 "keine_Anforderung" 1 "Tueren_Verriegeln";
VAL_ 319 PreCrash_FS_Laengsverstellung 0 "nicht_angefordert" 1 "angefordert";
VAL_ 319 PreCrash_Anforderung_AFR 0 "keine_Anforderung" 1 "linke_Seite" 2 "rechte_Seite" 3 "Vorderachse" 4 "Hinterachse" 5 "Vorwarnung" 7 "Init";
VAL_ 319 SC_PreCrash_LED 0 "keine_Anzeige" 1 "Stufe_1_glimmen" 2 "Stufe_2_leuchten" 3 "Stufe_3_blinken";
VAL_ 319 PreCrash_FS_Pneumatik_ansteuern 0 "keine_Anforderung" 1 "Pneumatik_ansteuern";
VAL_ 319 PreCrash_BFS_Pneumatik_ansteuern 0 "keine_Anforderung" 1 "Pneumatik_ansteuern";
VAL_ 319 PreCrash_Fo_Pneumatik_ansteuern 0 "keine_Anforderung" 1 "Pneumatik_ansteuern";
VAL_ 319 PreCrash_FS_Sitzlehne_verfahren 0 "keine_Anforderung" 1 "Sitzlehne_in_pos_x-Richtung_verfahren(vor)" 2 "Sitzlehne_in_neg_x-Richtung_verfahren(zurueck)" 3 "Sitzlehnenkopf_in_pos_x-Richtung_verfahren(vor)" 4 "Sitzlehnenkopf_in_neg_x-Richtung_verfahren(zurueck)" 6 "Lehnenverstellung_ansteuern" 7 "Lehnenkopfverstellung_ansteuern";
VAL_ 319 PreCrash_BFS_Sitzlehne_verfahren 0 "keine_Anforderung" 1 "Sitzlehne_in_pos_x-Richtung_verfahren(vor)" 2 "Sitzlehne_in_neg_x-Richtung_verfahren(zurueck)" 3 "Sitzlehnenkopf_in_pos_x-Richtung_verfahren(vor)" 4 "Sitzlehnenkopf_in_neg_x-Richtung_verfahren(zurueck)" 6 "Lehnenverstellung_ansteuern" 7 "Lehnenkopfverstellung_ansteuern";
VAL_ 319 PreCrash_Fo_Sitzlehne_verfahren 0 "keine_Anforderung" 1 "Sitzlehne_in_pos_x-Richtung_verfahren(vor)" 2 "Sitzlehne_in_neg_x-Richtung_verfahren(zurueck)" 3 "Sitzlehnenkopf_in_pos_x-Richtung_verfahren(vor)" 4 "Sitzlehnenkopf_in_neg_x-Richtung_verfahren(zurueck)";
VAL_ 319 PreCrash_FS_KSV_verfahren 0 "keine_Anforderung" 1 "in_pos_x-Richtung_verfahren" 2 "in_neg_x-Richung_verfahren" 3 "in_pos_z-Richtung_verfahren" 4 "in_neg_z-Richtung_verfahren" 5 "in_pos_x-Richtung_und_neg_z-Richtung_verfahren" 6 "in_pos_x_Richtung_und_pos_z-Richtung_verfahren" 7 "in_neg_x-Richtung_und_neg_z-Richtung_verfahren" 8 "in_neg_x-Richtung_und_pos_z-Richtung_verfahren" 9 "Kopfstuetze_ansteuern";
VAL_ 319 PreCrash_BFS_KSV_verfahren 0 "keine_Anforderung" 1 "in_pos_x-Richtung_verfahren" 2 "in_neg_x-Richung_verfahren" 3 "in_pos_z-Richtung_verfahren" 4 "in_neg_z-Richtung_verfahren" 5 "in_pos_x-Richtung_und_neg_z-Richtung_verfahren" 6 "in_pos_x_Richtung_und_pos_z-Richtung_verfahren" 7 "in_neg_x-Richtung_und_neg_z-Richtung_verfahren" 8 "in_neg_x-Richtung_und_pos_z-Richtung_verfahren" 9 "Kopfstuetze_ansteuern";
VAL_ 319 PreCrash_Fo_KSV_verfahren 0 "keine_Anforderung" 1 "in_pos_x-Richtung_verfahren" 2 "in_neg_x-Richung_verfahren" 3 "in_pos_z-Richtung_verfahren" 4 "in_neg_z-Richtung_verfahren" 5 "in_pos_x-Richtung_und_neg_z-Richtung_verfahren" 6 "in_pos_x_Richtung_und_pos_z-Richtung_verfahren" 7 "in_neg_x-Richtung_und_neg_z-Richtung_verfahren" 8 "in_neg_x-Richtung_und_pos_z-Richtung_verfahren";
VAL_ 319 PreCrash_BFS_Laengsverstellung 0 "nicht_angefordert" 1 "angefordert";
VAL_ 319 SC_PreCrash_Warnung 0 "keine_Anzeige" 1 "latente_Vorwarnung" 2 "Vorwarnung" 3 "Akutwarnung" 4 "Eingriff" 5 "Fahreruebernahmeaufforderung" 6 "Abbiegewarnung" 7 "Basiseingriff" 8 "Heckeingriff";
VAL_ 319 SC_PreCrash_Texte 0 "keine_Anzeige" 1 "Systemstoerung" 2 "keine_Sensorsicht" 3 "Demomodus" 4 "System_aus" 5 "Anhaengerbetrieb" 6 "ESC_aus" 7 "zurzeit_eingeschraenkt" 8 "zurzeit_eingeschraenkt_ESP_Aus" 9 "Initialisierung";
VAL_ 1122 PSD_Segment_ID 0 "keine Segmentinformationen vorhanden" 1 "Fehlerwert";
VAL_ 1122 PSD_Vorgaenger_Segment_ID 0 "keine Segmentinformation vorhanden" 1 "Fehlerwert";
VAL_ 1122 PSD_Strassenkategorie 0 "Rest_Feldweg_Schotterweg_Privatweg" 1 "Ortsstraße" 2 "Kreisstraße" 3 "Landstraße" 4 "Bundesstraße" 5 "Autobahn" 7 "Init";
VAL_ 1122 PSD_Endkruemmung 255 "Gerade";
VAL_ 1122 PSD_Endkruemmung_Vorz 0 "Kruemmung_positiv" 1 "Kruemmung_negativ";
VAL_ 1122 PSD_Idenditaets_ID 0 "keine_Segment_Informationen_vorhanden" 1 "Fehler";
VAL_ 1122 PSD_ADAS_Qualitaet 0 "keine_ADAS_Qualitaet" 1 "ADAS_Qualitaet";
VAL_ 1122 PSD_wahrscheinlichster_Pfad 0 "Pfad_mit_geringer_Wahrscheinlichkeit" 1 "wahrscheinlichster_Pfad";
VAL_ 1122 PSD_Geradester_Pfad 0 "nicht_geradester_PFad" 1 "geradester_Pfad";
VAL_ 1122 PSD_Fahrspuren_Anzahl 0 "Einbahnstrasse_in_falsche_Richtung" 1 "eine_Fahrspur" 2 "zwei_Fahrspuren" 3 "drei_Fahrspuren" 4 "vier_Fahrspuren" 5 "fuenf_Fahrspuren" 6 "sechs_Fahrspuren" 7 "mehr_als_sechs_Fahrspuren";
VAL_ 1122 PSD_Bebauung 0 "ausserhalb_bebauten_Gebietes" 1 "innerhalb_bebauten_Gebietes";
VAL_ 1122 PSD_Segment_Komplett 0 "Segment_Attribute_nicht_komplett" 1 "Segment_Attribute_komplett";
VAL_ 1122 PSD_Rampe 0 "Strasse_mit_Gegenverkehr" 1 "Auffahrt_Einbahnstr" 2 "Abfahrt_Einbahnstr" 3 "Einbahnstrasse";
VAL_ 1122 PSD_Anfangskruemmung 255 "Gerade";
VAL_ 1122 PSD_Anfangskruemmung_Vorz 0 "positiv" 1 "negativ";
VAL_ 1122 PSD_Abzweigerichtung 0 "rects_abzweigende_Strasse" 1 "links_abzweigende_Strasse";
VAL_ 1123 PSD_Pos_Segment_ID 0 "keine Position gegeben" 1 "Fehlerwert";
VAL_ 1123 PSD_Pos_Standort_Eindeutig 0 "mehrdeutiger_Standort" 1 "eindeutiger_Standort";
VAL_ 1123 PSD_Pos_Fehler_Laengsrichtung 0 "Init" 1 "< 2m" 2 "< 5m" 3 "< 10m" 4 "< 20m" 5 "< 50m" 6 "> 50m" 7 "Off-Road";
VAL_ 1123 PSD_Pos_Fahrspur 0 "unbekannt" 1 "Erste_Spur_von_rechts" 2 "Zweite_Spur_von_rechts" 3 "Dritte_Spur_von_rechts" 4 "Vierte_Spur_von_rechts" 5 "Fuenfte_Spur_von_rechts" 6 "Sechte_Spur_von_rechts" 7 "Siebte_oder_weitere_Spur_von_rechts";
VAL_ 1123 PSD_Attribut_Segment_ID_05 0 "keine_Segment_Information" 1 "Fehler";
VAL_ 1123 PSD_Attribut_1_ID 0 "keine_Information";
VAL_ 1123 PSD_Attribut_2_ID 0 "keine_Information";
VAL_ 1123 PSD_Attribute_Komplett_05 0 "Attribute_nicht_komplett" 1 "Attribute_komplett";
VAL_ 1124 PSD_06_Mux 0 "Init";
VAL_ 1124 PSD_Sys_Segment_ID 0 "keine Segmentinformationen vorhanden" 1 "nicht zulaessig";
VAL_ 1124 PSD_Attribut_Segment_ID 0 "keine_Segment_Information_vorhanden" 1 "Fehler";
VAL_ 1124 PSD_Ges_Segment_ID 0 "keine Segmentinformationen vorhanden" 1 "nicht zulaessig";
VAL_ 1124 PSD_Baum_Laenge_VZ 0 "Ost" 1 "West";
VAL_ 1124 PSD_Steigung_1_Segment_ID 0 "keine_Segment_Information_vorhanden" 1 "Fehler";
VAL_ 1124 PSD_Baum_Laenge 33554431 "keine_GPS_Information";
VAL_ 1124 PSD_Attribut_3_ID 0 "keine_Information";
VAL_ 1124 PSD_Steigung_1_A_Steigung 126 "mehr_als_15_Prozent" 127 "Steigung_unbekannt";
VAL_ 1124 PSD_Ges_Geschwindigkeit 0 "Kein Geschwindigkeitsgebot" 1 "0 km/h < v_max <  5 km/h" 2 "5 km/h < v_max < 10km/h" 3 "10 km/h < v_max < 15 km/h" 4 "15 km/h < v_max < 20 km/h" 5 "20 km/h < v_max < 25 km/h" 6 "25 km/h < v_max < 30 km/h" 7 "30 km/h < v_max < 35 km/h" 8 "35 km/h < v_max < 40 km/h" 9 "40 km/h < v_max < 45 km/h" 10 "45 km/h < v_max < 50 km/h" 11 "50 km/h < v_max < 60 km/h" 12 "60 km/h < v_max < 70 km/h" 13 "70 km/h < v_max < 80 km/h" 14 "80 km/h < v_max < 90 km/h" 15 "90 km/h < v_max < 100 km/h" 16 "100 km/h < v_max < 110 km/h" 17 "110 km/h < v_max < 120 km/h" 18 " 120 km/h < v_max < 130 km/h" 19 "130 km/h < v_max < 140 km/h" 20 "140 km/h < v_max < 150 km/h" 21 "150 km/h < v_max < 160 km/h" 22 "160 km/h < v_max" 23 "Geschwindigkeitsgebot aufgehoben" 24 "..0x1F ungültig";
VAL_ 1124 PSD_Steigung_1_A_Vorz 0 "Gefaelle" 1 "Steigung";
VAL_ 1124 PSD_Sys_Geschwindigkeit_Einheit 0 "km/h" 1 "mph";
VAL_ 1124 PSD_Sys_Verkehrsrichtung 0 "Rechtsverkehr" 1 "Linksverkehr";
VAL_ 1124 PSD_Sys_Geometrieguete 0 "Geringe_Guete" 1 "tbd" 2 "tbd" 3 "Hohe_Guete";
VAL_ 1124 PSD_Sys_Mapmatchingguete 0 "geringe_Guete" 1 "res" 2 "res" 3 "hohe_Guete";
VAL_ 1124 PSD_Ges_Typ 0 "Geschw_Klasse_des_Kartendatensuppliers" 1 "Explizit_abgeleiteten_Begrenzung" 2 "Durch_Gesetzg_vorgeg_allgem_Gebot_fuer_uebertr_Rahmenbed" 3 "Init";
VAL_ 1124 PSD_Sys_Alter_Karte 0 "kleiner_1_Jahr" 1 "1_Jahr" 2 "2_Jahre" 3 "3_Jahre" 4 "4_Jahre" 5 "5_Jahre" 6 "6_Jahre" 7 "groesser_7_Jahre";
VAL_ 1124 PSD_Ges_Spur_Geschw_Begrenzung 0 "Gebot_fuer_alle_spuren_gueltig";
VAL_ 1124 PSD_Steigung_1_B_Steigung 126 "mehr_als_15_Prozent" 127 "Steigung_unbekannt";
VAL_ 1124 PSD_Attribut_4_ID 0 "keine_Information";
VAL_ 1124 PSD_Sys_Zielfuehrung 0 "Zielfuehrung nicht aktiv" 1 "Zielfuehrung aktiv";
VAL_ 1124 PSD_Sys_US_State 0 "kein_US_State" 1 "Alabama" 2 "Alaska" 3 "Arkansas" 4 "Arizona" 5 "California" 6 "Colorado" 7 "Conneticut" 8 "District_of_Columbia" 9 "Delaware" 10 "Florida" 11 "Georgia" 12 "Hawaii" 13 "Idaho" 14 "Illinois" 15 "Iowa" 16 "Indiana" 17 "Kansas" 18 "Kentucky" 19 "Louisiana" 20 "Massachusetts" 21 "Maryland" 22 "Maine" 23 "Michigan" 24 "Minnesota" 25 "Missouri" 26 "Mississippi" 27 "Montana" 28 "North_Carolina" 29 "North_Dakota" 30 "Nebraska" 31 "Nevada" 32 "New_Hampshire" 33 "New_Jersey" 34 "New_Mexico" 35 "New_York" 36 "Ohio" 37 "Oklahoma" 38 "Oregon" 39 "Pennsylvania" 40 "Puerto_Rico" 41 "Rhode_Island" 42 "South_Carolina" 43 "South_Dakota" 44 "Tennessee" 45 "Texas" 46 "Utah" 47 "Virginia" 48 "Virgin_Islands" 49 "Vermont" 50 "Washington" 51 "Wisconsin" 52 "West_Virginia" 53 "Wyoming";
VAL_ 1124 PSD_Ges_Geschwindigkeit_Gespann 0 "alle Fahrzeuge" 1 "PKW mit Gespann" 2 "LKW, Busse, etc.";
VAL_ 1124 PSD_Baum_Breite_VZ 0 "Nord" 1 "Sued";
VAL_ 1124 PSD_Ges_Geschwindigkeit_Witter 0 "Witterungsunabhängig" 1 "Nässe, Regen, Niederschlag" 2 "Glätte" 3 "Nebel";
VAL_ 1124 PSD_Steigung_1_B_Vorz 0 "Gefaelle" 1 "Steigung";
VAL_ 1124 PSD_Ges_Geschwindigkeit_Tag_Anf 0 "kein Beginn definiert" 1 "Montag" 2 "Dienstag" 3 "Mittwoch" 4 "Donnerstag" 5 "Freitag" 6 "Samstag" 7 "Sonntag";
VAL_ 1124 PSD_Ges_Geschwindigkeit_Tag_Ende 0 "kein Ende definiert" 1 "Montag" 2 "Dienstag" 3 "Mittwoch" 4 "Donnerstag" 5 "Freitag" 6 "Samstag" 7 "Sonntag";
VAL_ 1124 PSD_Sys_Quali_verfuegbar 0 "Qualitaetskriterien_nicht_verfuegbar" 1 "Qualitaetskriterien_verfuegbar";
VAL_ 1124 PSD_Sys_Zielfuehrung_geaendert 0 "Zielfuehrung_nicht_geaendert" 1 "Zielfuehrung_geaendert";
VAL_ 1124 PSD_Ges_Geschwindigkeit_Std_Anf 25 "kein Beginn für stundenweise Einschränkungen";
VAL_ 1124 PSD_Steigung_1_Attribute_kompl 0 "Steigungen_nicht_komplett" 1 "Steigungen_komplett";
VAL_ 1124 PSD_Sys_Geometrieguete_erweitert 0 "Init";
VAL_ 1124 PSD_Steigung_2_Segment_ID 0 "keine_Segment_Information_vorhanden" 1 "Fehler";
VAL_ 1124 PSD_Attribut_5_ID 0 "keine_Information";
VAL_ 1124 PSD_Ges_Geschwindigkeit_Std_Ende 25 "kein Ende für stundenweise Einschränkungen";
VAL_ 1124 PSD_Steigung_2_Steigung 126 "mehr_als_15_Prozent" 127 "Steigung_unbekannt";
VAL_ 1124 PSD_Ges_Ueberholverbot 0 "kein Überholverbot" 1 "alle Fahrzeuge" 2 "Überholverbot für PKW mit Gespann" 3 "Überholverbot für LKW, Busse, etc.";
VAL_ 1124 PSD_Ges_Wechselverkehrszeichen 0 "Kein Wechselverkehrszeichen" 1 "Wechselverkehrszeichen links" 2 "Wechselverkehrszeichen rechts" 3 "Wechselverkehrszeichen links und rechts" 4 "Wechselverkerhszeichen über der Fahrbahn";
VAL_ 1124 PSD_Steigung_2_Vorz 0 "Gefaelle" 1 "Steigung";
VAL_ 1124 PSD_Wechselverkehrszeichen_Typ 0 "kein_Wechselverkehrszeichen" 1 "LED_Wechselverkehrszeichen" 2 "nicht_LED_Wechselverkehrszeichen";
VAL_ 1124 PSD_Ges_Gesetzlich_Kategorie 0 "kein_legales_Verbot" 1 "innerorts" 2 "ausserorts" 3 "Autobahn";
VAL_ 1124 PSD_Attribute_Komplett_06 0 "Attribute_nicht_komplett" 1 "Attribute_komplett";
VAL_ 1124 PSD_Ges_Gesetzlich_Zusatz 0 "kein_Zusatz_zu_legalem_Gebot" 1 "Anhaenger_Klasse_1" 2 "Anhaenger_Klasse_2";
VAL_ 1124 PSD_Ges_Verkehrszeichen_Quelle 0 "VZA_kein_Onlinedienst" 1 "nur_VZA" 2 "nur_VZO" 3 "VZA_und_VZO";
VAL_ 1124 PSD_Steigung_2_Attribute_kompl 0 "Steigungen_nicht_komplett" 1 "Steigungen_komplett";
VAL_ 1124 PSD_Ges_Attribute_Komplett 0 "Attribute_nicht_komplett" 1 "Attribute_komplett";
VAL_ 591 RDR1_relevanter_Fehler 0 "kein_relevanter_Fehler" 1 "relevanter_Fehler";
VAL_ 591 RDR1_Blindheit_erkannt 0 "keine_Blindheit_erkannt" 1 "Blindheit_erkannt";
VAL_ 591 RDR1_relev_Nichtverfuegbarkeit 0 "verfuegbar" 1 "nicht_verfuegbar";
VAL_ 591 RDR1_Verkehrssinn 0 "init" 1 "Linksverkehr" 2 "Rechtsverkehr" 3 "Unbekannt";
VAL_ 591 RDR1_Objekte_02_Datenalter 1023 "Daten_aelter_als_Maximum";
VAL_ 591 RDR1_Obj_01_ax_v 255 "Init";
VAL_ 591 RDR1_Obj_01_ax_StdA 63 "Init";
VAL_ 591 RDR1_Obj_01_vx_StdA 127 "Init";
VAL_ 591 RDR1_Obj_01_dx_StdA 127 "Init";
VAL_ 591 RDR1_Obj_01_dy_StdA 127 "Init";
VAL_ 980 BH_Blinker_li 0 "nicht_betaetigt" 1 "Blinkerhebel_Richtung_links_betaetigt";
VAL_ 980 BH_Blinker_re 0 "nicht_betaetigt" 1 "Blinkerhebel_Richtung_rechts_betaetigt";
VAL_ 980 BH_Lichthupe 0 "nicht_betaetigt" 1 "Blinkerhebel in Richtung Lichthupe betaetigt";
VAL_ 980 BH_Fernlicht 0 "nicht_betaetigt" 1 "Blinkerhebel_in_Richtung_Fernlicht_betaetigt";
VAL_ 980 WH_Tipwischen 0 "nicht_betaetigt" 1 "betaetigt";
VAL_ 980 WH_Intervall 0 "aus" 1 "Wischerhebel in Stellung Intervall";
VAL_ 980 WH_WischerStufe1 0 "aus" 1 "Wischerhebel in Stufe Wischen 1";
VAL_ 980 WH_WischerStufe2 0 "aus" 1 "Wischerhebel in Stufe Wischen 2";
VAL_ 980 WH_Frontwaschen 0 "aus" 1 "Wischerhebel in Stellung Wisch Wasch vorne";
VAL_ 980 WH_Heckintervall 0 "nicht_betaetigt" 1 "Wischerhebel in Stellung Heckintervall";
VAL_ 980 WH_Heckwaschen 0 "nicht_betaetigt" 1 "Wischerhebel in Stellung Wisch Wasch hinten";
VAL_ 980 WH_Intervallstufen 0 "Init / Default" 9 "Intervallstufe 3" 1 "Intervallstufe 1" 13 "Intervallstufe 4" 5 "Intervallstufe 2" 15 "Fehler";
VAL_ 980 FAS_Taster 0 "nicht_betaetigt" 1 "betaetigt";
VAL_ 980 FAS_Taster_Fehler 0 "kein_Fehler" 1 "Fehler";
VAL_ 980 SMLS_Hupe 0 "nicht_betaetigt" 1 "Hupe_gedrueckt";
VAL_ 980 LRH_on_off 0 "LRH_aus__keine Anzeige" 1 "LRH_aus" 2 "LRH_ein" 3 "Fehler";
VAL_ 980 LSS_Tastencode 0 "Key_Released__No_Key" 4 "Up" 5 "Down" 7 "OK__ThumbWheel_Button";
VAL_ 980 LRH_aktiv 0 "inaktiv" 1 "aktiv";
VAL_ 980 SMLS_P_verriegelt 0 "Init" 1 "nicht_verriegelt" 2 "verriegelt" 3 "Fehler";
VAL_ 980 SMLS_P_verriegelt_plausibel 0 "unplausibel" 1 "plausibel";
VAL_ 980 WH_SRA 0 "SRA_Aus" 1 "SRA_Ein";
VAL_ 980 WH_Wischer_Fehler 0 "kein_Fehler" 1 "Fehler";
VAL_ 980 BH_Blinker_Fehler 0 "kein_Fehler" 1 "Fehler";
VAL_ 980 SMLS_PTT 0 "nicht_betaetigt" 1 "PTT_gedrueckt";
VAL_ 980 WH_Tipwischen_lang 0 "nicht_betaetigt" 1 "betaetigt";
VAL_ 1413 SI_Sammel_SG_Fehler 61 "Reserviert" 62 "Overflow" 63 "ungueltig";
VAL_ 1413 SI_P_Mode_gueltig 0 "dezentraler_Produktionsmode" 1 "zentraler_Produktionsmode";
VAL_ 1413 SI_Diagnose_Aktiv 0 "inaktiv" 1 "aktiv";
VAL_ 1413 SI_QRS_Mode 0 "QRS_Messmodus_nicht_aktiv" 1 "QRS_Messmodus_aktiv";
VAL_ 1413 SI_T_Mode 0 "Transportmodus_nicht_aktiv" 1 "Transportmodus_aktiv";
VAL_ 1413 SI_NWDF 0 "Ueberwachung_nicht_freigegeben" 1 "Ueberwachung_freigegeben";
VAL_ 1413 SI_NWDF_gueltig 0 "NWDF_wird_nicht_unterstuetzt" 1 "NWDF_wird_unterstuetzt";
VAL_ 1413 SI_Sammelfehler 0 "kein_Sammelfehler" 1 "Sammelfehler";
VAL_ 1413 GW_KD_Fehler 0 "kein_KD_Fehler" 1 "KD_Fehler";
VAL_ 1413 SI_T_Schutz 0 "Transportschutz_nicht_aktiv" 1 "Transportschutz_aktiv";
VAL_ 1413 SI_P_Mode 0 "inaktiv" 1 "aktiv";
VAL_ 1413 SI_BUS_01 0 "keine_Busruhe" 1 "Busruhe";
VAL_ 1413 SI_BUS_02 0 "keine_Busruhe" 1 "Busruhe";
VAL_ 1413 SI_BUS_03 0 "keine_Busruhe" 1 "Busruhe";
VAL_ 1413 SI_BUS_04 0 "keine_Busruhe" 1 "Busruhe";
VAL_ 1413 SI_BUS_05 0 "keine_Busruhe" 1 "Busruhe";
VAL_ 1413 SI_BUS_06 0 "keine_Busruhe" 1 "Busruhe";
VAL_ 1413 SI_BUS_07 0 "keine_Busruhe" 1 "Busruhe";
VAL_ 1413 SI_BUS_08 0 "keine_Busruhe" 1 "Busruhe";
VAL_ 1413 SI_BUS_09 0 "keine_Busruhe" 1 "Busruhe";
VAL_ 1413 SI_BUS_10 0 "keine_Busruhe" 1 "Busruhe";
VAL_ 1413 SI_BUS_11 0 "keine_Busruhe" 1 "Busruhe";
VAL_ 1413 SI_BUS_12 0 "keine_Busruhe" 1 "Busruhe";
VAL_ 1413 SI_BUS_13 0 "keine_Busruhe" 1 "Busruhe";
VAL_ 1413 SI_BUS_14 0 "keine_Busruhe" 1 "Busruhe";
VAL_ 1413 SI_BUS_15 0 "keine_Busruhe" 1 "Busruhe";
VAL_ 1413 SI_Bus_Identifikation 16 "CAN_Diagnose" 17 "CAN_Antrieb" 18 "CAN_Komfort" 19 "CAN_Infotainment" 20 "CAN_Fahrwerk" 21 "CAN_Extended" 22 "CAN_Hybrid" 23 "CAN_Lade" 24 "CAN_Kombi" 25 "CAN_Komfort_2" 26 "CAN_AFS" 97 "VLAN_FAS" 33 "CAN_FahrerAssistenzSysteme" 98 "VLAN_Infotainment" 34 "CAN_Migration" 99 "VLAN_Connect" 35 "CAN_Connect" 100 "VLAN_Komfort" 36 "CAN_AnzeigeBedienung" 101 "VLAN_Antrieb" 37 "CAN_ElectricalVehicle" 104 "VLAN_Gateway" 40 "CAN_Telematik" 105 "VLAN_Remote_FC" 41 "CAN_MFL" 48 "FlexRay_A" 49 "FlexRay_B" 102 "VLAN_Diagnose" 103 "VLAN_Internet" 106 "VLAN_Connect_2";
VAL_ 1413 SI_CAB_V10 32768 "CAB_16_Licht" 16384 "CAB_15_Laden" 128 "CAB_08_MIB" 0 "Init" 64 "CAB_07_Connect" 8192 "CAB_14_VLAN_Infotainment" 32 "CAB_06_Anzeige" 4096 "CAB_13_VLAN_Connect" 16 "CAB_05_Komfort" 8 "CAB_04_Fahrerassistenz" 1 "CAB_01_Antrieb" 2 "CAB_02_Hybrid_Laden" 4 "CAB_03_Fahrwerk" 256 "CAB_09_Standheizung" 1024 "CAB_11_VLAN_Fahrerassistenz";
VAL_ 2589283396 TSK_vMax_EfficiencyMode1 254 "kein_Limit_aktiv" 255 "Init";
VAL_ 2589283396 TSK_vMax_EfficiencyMode2 254 "kein_Limit_aktiv" 255 "Init";
VAL_ 2589283396 TSK_vMax_StandardMode 254 "kein_Limit_aktiv" 255 "Init";
VAL_ 1019 TSK_Ausrollkurve_Schub_Reku_01 127 "Init";
VAL_ 1019 TSK_Ausrollkurve_Schub_Reku_05 127 "Init";
VAL_ 1019 TSK_Ausrollkurve_Schub_Reku_09 127 "Init";
VAL_ 1019 TSK_Ausrollkurve_Schub_Reku_13 127 "Init";
VAL_ 1019 TSK_Ausrollkurve_Schub_Reku_17 127 "Init";
VAL_ 1019 TSK_Ausrollkurve_Schub_Reku_02 127 "Init";
VAL_ 1019 TSK_Ausrollkurve_Schub_Reku_06 127 "Init";
VAL_ 1019 TSK_Ausrollkurve_Schub_Reku_10 127 "Init";
VAL_ 1019 TSK_Ausrollkurve_Schub_Reku_14 127 "Init";
VAL_ 1019 TSK_Ausrollkurve_Schub_Reku_18 127 "Init";
VAL_ 1019 TSK_Ausrollkurve_Schub_Reku_03 127 "Init";
VAL_ 1019 TSK_Ausrollkurve_Schub_Reku_07 127 "Init";
VAL_ 1019 TSK_Ausrollkurve_Schub_Reku_11 127 "Init";
VAL_ 1019 TSK_Ausrollkurve_Schub_Reku_15 127 "Init";
VAL_ 1019 TSK_Ausrollkurve_Schub_Reku_19 127 "Init";
VAL_ 1019 TSK_Ausrollkurve_Schub_Reku_04 127 "Init";
VAL_ 1019 TSK_Ausrollkurve_Schub_Reku_08 127 "Init";
VAL_ 1019 TSK_Ausrollkurve_Schub_Reku_12 127 "Init";
VAL_ 1019 TSK_Ausrollkurve_Schub_Reku_16 127 "Init";
VAL_ 1019 TSK_Ausrollkurve_Schub_Reku_20 127 "Init";
VAL_ 1019 TSK_Ausrollkurve_Segeln_01 127 "Init";
VAL_ 1019 TSK_Ausrollkurve_Segeln_05 127 "Init";
VAL_ 1019 TSK_Ausrollkurve_Segeln_09 127 "Init";
VAL_ 1019 TSK_Ausrollkurve_Segeln_13 127 "Init";
VAL_ 1019 TSK_Ausrollkurve_Segeln_17 127 "Init";
VAL_ 1019 TSK_Ausrollkurve_Segeln_02 127 "Init";
VAL_ 1019 TSK_Ausrollkurve_Segeln_06 127 "Init";
VAL_ 1019 TSK_Ausrollkurve_Segeln_10 127 "Init";
VAL_ 1019 TSK_Ausrollkurve_Segeln_14 127 "Init";
VAL_ 1019 TSK_Ausrollkurve_Segeln_18 127 "Init";
VAL_ 1019 TSK_Ausrollkurve_Segeln_03 127 "Init";
VAL_ 1019 TSK_Ausrollkurve_Segeln_07 127 "Init";
VAL_ 1019 TSK_Ausrollkurve_Segeln_11 127 "Init";
VAL_ 1019 TSK_Ausrollkurve_Segeln_15 127 "Init";
VAL_ 1019 TSK_Ausrollkurve_Segeln_19 127 "Init";
VAL_ 1019 TSK_Ausrollkurve_Segeln_04 127 "Init";
VAL_ 1019 TSK_Ausrollkurve_Segeln_08 127 "Init";
VAL_ 1019 TSK_Ausrollkurve_Segeln_12 127 "Init";
VAL_ 1019 TSK_Ausrollkurve_Segeln_16 127 "Init";
VAL_ 1019 TSK_Ausrollkurve_Segeln_20 127 "Init";
VAL_ 1019 TSK_Ausrollkurve_Reku 0 "Rekuperation_nicht_beruecksichtigt" 1 "Rekuperation_beruecksichtigt";
VAL_ 1019 TSK_Ausrollkurve_Schrittweite 0 "Normale_Schrittweite" 1 "Grosse_Schrittweite";
VAL_ 261 HMS_P_beibehalten_GE 0 "P_nicht_beibehalten" 1 "P_beibehalten" 2 "Init" 3 "Fehler";
VAL_ 261 VZM_Unterdrueckung_Antriebsmom 0 "Pos_Antriebsmoment_moeglich" 1 "Pos_Antriebsmoment_unterdruecken";
VAL_ 261 HMS_halten_nicht_verfuegbar 0 "verfuegbar" 1 "nicht_verfuegbar";
VAL_ 261 HMS_parken_nicht_verfuegbar 0 "verfuegbar" 1 "nicht_verfuegbar";
VAL_ 261 HMS_Anforderung_GE 0 "keine_Anforderung" 1 "P_einlegen";
VAL_ 261 HMS_Systemstatus 0 "keine_Funktion_aktiv" 1 "Halten_aktiv" 2 "Parken_angefordert" 3 "Parken_aktiv" 4 "Parken_beibehalten_aktiv" 5 "Anfahren_aktiv" 6 "Loeseanforderung_aktiv" 7 "Loeseanforderung_durch_Fahrer" 8 "Abrutschen_erkannt" 9 "Halten_Standby_aktiv" 10 "Anfahren_Standby_aktiv" 14 "Init" 15 "Fehler";
VAL_ 261 HMS_Stillstand 0 "kein_Stillstand" 1 "Stillstand_frueh" 2 "Stillstand" 6 "Init" 7 "Fehler";
VAL_ 261 HMS_aktives_System 0 "kein_System__Init_Fehler" 1 "Fahreranforderung_aktiv" 2 "HMS_intern_aktiv" 3 "ACC_aktiv" 4 "Autohold_aktiv" 5 "HHC_aktiv" 6 "HVLM_aktiv" 7 "Getriebe_aktiv" 8 "EBKV_aktiv" 9 "ParkAssist_aktiv" 10 "ARA_aktiv" 12 "autonomous_Hold_aktiv" 13 "STA_aktiv" 14 "Motor_aktiv" 15 "EA_aktiv" 16 "VLK_aktiv";
VAL_ 261 VMM_Inkonsistenz_GE 0 "konsistent" 1 "nicht_konsistent";
VAL_ 261 VMM_Inkonsistenz_HVLM 0 "konsistent" 1 "nicht_konsistent";
VAL_ 261 HMS_Fehlerstatus 0 "kein_Fehler" 1 "Halten_nicht_moeglich" 2 "Sonderbetriebsmodus_aktiv" 3 "Systemeinschraenkung" 4 "Systemstoerung";
VAL_ 261 HMS_Index_Haltemoment 0 "Bremsmoment" 1 "Antriebsmoment";
VAL_ 261 HMS_Haltemoment 1022 "Init" 1023 "Fehler";
VAL_ 313 VZM_aktiver_Basisservice 0 "Keine_Aktivitaet" 1 "Bremsenkonditionierung" 2 "Bremsruck" 3 "Verzoegerungsregelung" 4 "Wegregelung";
VAL_ 313 VZM_Anhalteweg_nicht_verfuegbar 0 "verfuegbar" 1 "nicht_verfuegbar";
VAL_ 313 VZM_Fahrer_bremst 0 "Bremsdruckschwelle_nicht_ueberschritten" 1 "Bremsdruckschwelle_ueberschritten";
VAL_ 313 VZM_QBit_Fahrer_bremst 0 "gueltiger_Wert" 1 "Ersatz_Init_oder_Fehlerwert";
VAL_ 313 VMM_MKB_codiert 0 "MKB_nicht_codiert" 1 "MKB_codiert";
VAL_ 313 VMM_Inkonsistenz_EBKV 0 "konsistent" 1 "nicht_konsistent";
VAL_ 313 VMM_Notstopp_Status 0 "Init" 1 "verfuegbar" 2 "warten_auf_sekundaer_System" 3 "passiv_Ueberwachung" 4 "aktiv_ausgeloest" 7 "Fehler";
VAL_ 313 VZM_Warnruck_nicht_verfuegbar 0 "verfuegbar" 1 "nicht_verfuegbar";
VAL_ 313 VZM_Warnruckeln_nicht_verfuegbar 0 "verfuegbar" 1 "nicht_verfuegbar";
VAL_ 313 VZM_Bkd_nicht_verfuegbar 0 "verfuegbar" 1 "nicht_verfuegbar";
VAL_ 313 VMM_Bremslicht_defekt 0 "Bremslichter_nicht_defekt" 1 "Bremslichter_defekt";
VAL_ 313 VZM_Fahrer_bremst_deutlich 0 "Fahrer_bremst_nicht_deutlich" 1 "Fahrer_bremst_deutlich";
VAL_ 313 VZM_TSK_SRBM_Anf 0 "keine_Aktivitaet" 1 "Aktivitaet_durch_TSK";
VAL_ 313 VZM_TSK_SRBM_nicht_verfuegbar 0 "verfuegbar" 1 "nicht_verfuegbar";
VAL_ 313 VZM_Verz_Reg_aktiv 8 "Aktivitaet_durch_ARA" 0 "keine_Aktivitaet" 2 "Aktivitaet_durch_AWV_PCF" 3 "Aktivitaet_durch_EA" 4 "Aktivitaet_durch_TSK" 5 "Aktivitaet_durch_RCTA" 6 "Aktivitaet_durch_ParkAssist" 7 "Aktivitaet_durch_ACC" 9 "Aktivitaet_durch_NV" 10 "Aktivitaet_durch_KAS" 11 "Aktivitaet_durch_FAS_VK" 12 "Aktivitaet_durch_vESC" 13 "Aktivitaet_durch_KAM" 14 "Aktivitaet_durch_BRS_intern" 15 "Aktivitaet_durch_AEB" 16 "Aktivitaet_durch_MKB";
VAL_ 313 VZM_Verz_Reg_nicht_verfuegbar 0 "verfuegbar" 1 "nicht_verfuegbar";
VAL_ 313 VMM_Inkonsistenz_KAS 0 "konsistent" 1 "nicht_konsistent";
VAL_ 313 VMM_Bremslicht_unplausibel 0 "plausibel" 1 "unplausibel";
VAL_ 313 VMM_Inkonsistenz_ACC 0 "konsistent" 1 "nicht_konsistent";
VAL_ 313 VMM_Inkonsistenz_AWV_PCF 0 "konsistent" 1 "nicht_konsistent";
VAL_ 313 VMM_Inkonsistenz_ARA 0 "konsistent" 1 "nicht_konsistent";
VAL_ 313 VMM_Inkonsistenz_ParkAssist 0 "konsistent" 1 "nicht_konsistent";
VAL_ 313 VMM_Inkonsistenz_FAS_VK 0 "konsistent" 1 "nicht_konsistent";
VAL_ 313 VMM_Inkonsistenz_NV 0 "konsistent" 1 "nicht_konsistent";
VAL_ 313 VMM_Inkonsistenz_RCTA 0 "konsistent" 1 "nicht_konsistent";
VAL_ 313 VMM_Inkonsistenz_TSK 0 "konsistent" 1 "nicht_konsistent";
VAL_ 313 VMM_Inkonsistenz_MO 0 "konsistent" 1 "nicht_konsistent";
VAL_ 313 VMM_Inkonsistenz_AEB 0 "konsistent" 1 "nicht_konsistent";
VAL_ 313 VMM_Fahrer_Bremskraft_bestimmend 0 "Nicht_Bremskraft_bestimmend" 1 "Bremskraft_bestimmend";
VAL_ 313 VMM_Inkonsistenz_EA 0 "konsistent" 1 "nicht_konsistent";
VAL_ 313 VZM_Status_Wegregelung 0 "Inaktiv" 1 "Passiv" 2 "Aktiv" 3 "Passiv_Ueberwachend";
VAL_ 313 VZM_Verz_ASIL_Verfuegbarkeit 0 "Nicht_verfuegbar" 1 "Verfuegbar_ab_ASIL_QM" 2 "Verfuegbar_ab_ASIL_A" 3 "Verfuegbar_ab_ASIL_B" 4 "Verfuegbar_ab_ASIL_C";
VAL_ 313 VZM_aktives_System 0 "Kein_aktiver_Teilnehmer" 1 "VZM_intern" 2 "AWV_PCF" 3 "EA" 4 "TSK" 5 "RCTA" 6 "ParkAssist" 7 "ACC" 8 "ARA" 9 "NV" 10 "KAS" 11 "FAS_VK" 12 "vESC" 13 "KAM" 14 "reserviert" 15 "AEB" 16 "MKB";
VAL_ 313 VZM_Verz_Begrenzung 0 "keine_Begrenzung" 1 "Begrenzung_aktiv";
VAL_ 313 VZM_Systemstatus 0 "Initialisierung" 1 "Verfuegbar" 2 "Verfuegbar_eingeschr_Performance" 3 "Nicht_Verfuegbar" 4 "Fehler" 5 "Sonderbetriebsmodus";
VAL_ 313 VZM_SRBM_Soll 4094 "Init" 4095 "Fehler";
VAL_ 313 VZM_SRBM_Ist 4094 "Init" 4095 "Fehler";
VAL_ 313 VZM_SRBM_max_Gradient 126 "Init" 127 "Fehler";
VAL_ 313 VMM_Inkonsistenz_KAM 0 "konsistent" 1 "nicht_konsistent";
VAL_ 2463978663 VZE_Anzeigemodus 0 "EU_RDW" 1 "USA" 2 "Canada" 3 "China";
VAL_ 2463978663 VZE_Hinweistext 0 "kein_Hinweistext";
VAL_ 2463978663 VZE_Verkehrszeichen_Einheit 0 "kmh" 1 "mph";
VAL_ 2463978663 VZE_Anzeigeunterdrueck_Zeichen_3 0 "anzeigerelevant" 1 "nicht_anzeigerelevant";
VAL_ 2463978663 VZE_Anzeigeunterdrueck_Zeichen_2 0 "anzeigerelevant" 1 "nicht_anzeigerelevant";
VAL_ 2463978663 VZE_Verkehrszeichen_1 0 "kein_Verkehrszeichen";
VAL_ 2463978663 VZE_Verkehrszeichen_2 0 "kein_Verkehrszeichen";
VAL_ 2463978663 VZE_Verkehrszeichen_3 0 "kein_Verkehrszeichen";
VAL_ 2463978663 VZE_Warnung_Verkehrszeichen_1 0 "keine_Warnung_Initialwert_Fehlerwert" 1 "Warnung";
VAL_ 2463978663 VZE_Warnung_Verkehrszeichen_2 0 "keine_Warnung_Initialwert_Fehlerwert" 1 "Warnung";
VAL_ 2463978663 VZE_Warnung_Verkehrszeichen_3 0 "keine_Warnung_Initialwert_Fehlerwert" 1 "Warnung";
VAL_ 2463978663 VZE_Zusatzschild_1 0 "keine_Zusatzschild_Initialwert_Fehlerwert";
VAL_ 2463978663 VZE_Zusatzschild_2 0 "keine_Zusatzschild_Initialwert_Fehlerwert";
VAL_ 2463978663 VZE_Zusatzschild_3 0 "keine_Zusatzschild_Initialwert_Fehlerwert";
VAL_ 2463978663 VZE_Anzeigeunterdrueck_Zeichen_1 0 "anzeigerelevant" 1 "nicht_anzeigerelevant";
VAL_ 2463978663 VZE_Zeichen_01_KameraWied 0 "inaktiv" 1 "aktiv";
VAL_ 2463978663 VZE_Zeichen_02_KameraWied 0 "inaktiv" 1 "aktiv";
VAL_ 2463978663 VZE_Zeichen_03_KameraWied 0 "inaktiv" 1 "aktiv";
VAL_ 2463978663 VZE_Zeichen_01_Kamera 0 "nicht_erkannt" 1 "erkannt";
VAL_ 2463978663 VZE_Zeichen_01_Karte 0 "inaktiv" 1 "aktiv";
VAL_ 2463978663 VZE_Zeichen_01_Gesetz 0 "nicht_erkannt" 1 "erkannt";
VAL_ 2463978663 VZE_Zeichen_02_Kamera 0 "nicht_erkannt" 1 "erkannt";
VAL_ 2463978663 VZE_Zeichen_02_Karte 0 "inaktiv" 1 "aktiv";
VAL_ 2463978663 VZE_Zeichen_02_Gesetz 0 "nicht_erkannt" 1 "erkannt";
VAL_ 2463978663 VZE_Zeichen_03_Kamera 0 "nicht_erkannt" 1 "erkannt";
VAL_ 2463978663 VZE_Zeichen_03_Karte 0 "inaktiv" 1 "aktiv";
VAL_ 2463978663 VZE_Zeichen_03_Gesetz 0 "nicht_erkannt" 1 "erkannt";
VAL_ 2463978663 VZE_Gong 0 "Gong_deaktiv" 1 "Gong_aktiv";
VAL_ 2463978663 VZE_Anzeigeunterdrueck_Zeichen_5 0 "anzeigerelevant" 1 "nicht_anzeigerelevant";
VAL_ 2463978663 VZE_Zeichen_05_KameraWied 0 "inaktiv" 1 "aktiv";
VAL_ 2463978663 VZE_Zeichen_05_Kamera 0 "nicht_erkannt" 1 "erkannt";
VAL_ 2463978663 VZE_Verkehrszeichen_4 0 "kein_Verkehrszeichen";
VAL_ 2463978663 VZE_Verkehrszeichen_5 0 "kein_Verkehrszeichen";
VAL_ 2463978663 VZE_Anhaenger_Vmax 14 "Init" 15 "Fehler";
VAL_ 2463978663 VZE_Zeichen_04_Gesetz 0 "nicht_erkannt" 1 "erkannt";
VAL_ 2463978663 VZE_Zeichen_04_Kamera 0 "nicht_erkannt" 1 "erkannt";
VAL_ 2463978663 VZE_Zeichen_04_KameraWied 0 "inaktiv" 1 "aktiv";
VAL_ 2463978663 VZE_Zeichen_04_Karte 0 "inaktiv" 1 "aktiv";
VAL_ 2463978663 VZE_Warnung_Verkehrszeichen_4 0 "keine_Warnung_Initialwert_Fehlerwert" 1 "Warnung";
VAL_ 2463978663 VZE_Warnung_Verkehrszeichen_5 0 "keine_Warnung_Initialwert_Fehlerwert" 1 "Warnung";
VAL_ 2463978663 VZE_Zeichen_05_Gesetz 0 "nicht_erkannt" 1 "erkannt";
VAL_ 2463978663 VZE_Zusatzschild_4 0 "keine_Zusatzschild_Initialwert_Fehlerwert";
VAL_ 2463978663 VZE_Zusatzschild_5 0 "keine_Zusatzschild_Initialwert_Fehlerwert";
VAL_ 2463978663 VZE_Baustelle 0 "Keine_Baustelle" 1 "Baustelle_erkannt";
VAL_ 2463978663 VZE_Zeichen_05_Karte 0 "inaktiv" 1 "aktiv";
VAL_ 2463978663 VZE_Zeichen_05_Entfernung 0 "Init";
VAL_ 2463978663 VZE_Zeichen_05_Entfernung_StdA 0 "Init";
VAL_ 2463978663 VZE_Anzeigeunterdrueck_Zeichen_4 0 "anzeigerelevant" 1 "nicht_anzeigerelevant";
VAL_ 2463978663 VZE_Verkehrszeichen_6 0 "kein_Verkehrszeichen";
VAL_ 2463978663 VZE_Zusatzschild_6 0 "keine_Zusatzschild_Initialwert_Fehlerwert";
VAL_ 2463978663 VZE_Zeichen_06_Entfernung 0 "Init";
VAL_ 2463978663 VZE_Zeichen_06_Entfernung_StdA 0 "Init";
VAL_ 2463978663 VZE_Umweltinfo_Naesse 0 "inaktiv" 1 "aktiv";
VAL_ 2463978663 VZE_Umweltinfo_Nebel 0 "inaktiv" 1 "aktiv";
VAL_ 2463978663 VZE_Umweltinfo_Anhaengerbetrieb 0 "inaktiv" 1 "aktiv";
VAL_ 2463978663 VZE_Erweiterte_Information 0 "keine_Information";
VAL_ 2463978663 VZE_Tempowarnung_Status 0 "inaktiv" 1 "aktiv";
VAL_ 2463978663 VZE_Tempowarnung_Einheit 0 "kmh" 1 "mph";
VAL_ 2463978663 VZE_Tempowarnung_Offset 0 "Init";
VAL_ 2463978663 VZE_FoD_Status 0 "Init" 1 "Funktion_inaktiv" 2 "Funktion_aktiv";
VAL_ 2463978663 VZE_Anzeige_ZS_1 0 "Init";
VAL_ 2463978663 VZE_Anzeige_ZS_2 0 "Init";
VAL_ 2463978663 VZE_Anzeige_ZS_3 0 "Init";
VAL_ 2463978663 VZE_Hinweistext_03 0 "kein_Hinweistext";
VAL_ 2463978663 VZE_Land 0 "Init";
VAL_ 2463978663 VZE_Warnung_VZ_1 0 "keine_Warnung" 1 "Warnung";
VAL_ 2463978663 VZE_Warnung_VZ_2 0 "keine_Warnung" 1 "Warnung";
VAL_ 2463978663 VZE_Warnung_VZ_3 0 "keine_Warnung" 1 "Warnung";
VAL_ 2463978663 VZE_Anzeige_VZ_1 0 "kein_Verkehrszeichen";
VAL_ 2463978663 VZE_Anzeige_VZ_2 0 "kein_Verkehrszeichen";
VAL_ 2463978663 VZE_Anzeige_VZ_3 0 "kein_Verkehrszeichen";
VAL_ 181 WH_gespeicherte_Fahrstufe 0 "keine_Speicherung" 1 "P" 2 "R" 3 "N" 4 "D" 5 "S" 6 "Tipp_Gasse";
VAL_ 181 WH_Initialisierung 0 "keine Initphase" 1 "Initphase";
VAL_ 181 WH_SensorPos_roh 0 "Init" 1 "Pos_1" 2 "Pos_2" 3 "Pos_3" 4 "Pos_4" 5 "Pos_5" 6 "Pos_6" 7 "Pos_7" 8 "Pos_8" 9 "Pos_9" 10 "Pos_10" 11 "Pos_11" 12 "Pos_12" 13 "Pos_13" 14 "Pos_14" 15 "Fehler";
VAL_ 181 WH_SensorPos_roh_inv 0 "Fehler" 1 "Pos_14" 2 "Pos_13" 3 "Pos_12" 4 "Pos_11" 5 "Pos_10" 6 "Pos_9" 7 "Pos_8" 8 "Pos_7" 9 "Pos_6" 10 "Pos_5" 11 "Pos_4" 12 "Pos_3" 13 "Pos_2" 14 "Pos_1" 15 "Init";
VAL_ 181 WH_Test_Aktiv 0 "kein Testergebnis" 1 "Testergebnis";
VAL_ 181 WH_Ist_Haltemagnet 0 "Init__nicht_verbaut" 1 "haelt_nicht" 2 "haelt" 3 "Fehler";
VAL_ 181 WH_Variante 0 "Init" 1 "Rastierter_Waehlhebel" 2 "Tasten" 4 "Monostabil_2x2" 5 "Sport_Tasten" 6 "Monostabil_2x2_reduziert" 7 "Monostabil_2x2_Walzensegment";
VAL_ 181 WH_Entsperrtaste_02 0 "Init_nicht_verbaut" 1 "nicht_betaetigt" 2 "betaetigt" 3 "Fehler";
VAL_ 181 WH_P_Taste 0 "Init" 1 "nicht_betaetigt" 2 "betaetigt" 3 "Fehler";
VAL_ 181 WH_Ende_N_Haltephase 0 "nicht_aktiv" 1 "aktiv";
VAL_ 181 WH_Fahrstufe 8 "P" 0 "Init" 4 "nicht_betaetigt" 5 "D" 6 "N" 7 "R" 9 "N_ohne_Spotausleuchtung" 10 "Tipp_Plus" 11 "Tipp_Minus" 12 "S" 14 "Tipp_Gasse" 15 "Fehler";
VAL_ 181 WH_Status_Shiftlock 0 "Init" 2 "WH_freigegeben" 3 "WH_gesperrt" 6 "Shiftlock_nicht_verbaut" 7 "Fehler";
VAL_ 181 WH_Zustand_N_Haltephase 0 "inaktiv" 1 "aktiv__Timer_laeuft" 2 "beendet__Timer_abgelaufen" 3 "beendet__P_Taste_betaetigt";
VAL_ 2463978687 WH_Fehler_Haltemagnet_Status 0 "Test_nicht_durchgefuehrt" 1 "Test_durchgefuehrt";
VAL_ 2463978687 WH_Fehler_CRC_SBM 0 "Fehler_passiv" 1 "Fehler_aktiv";
VAL_ 2463978687 WH_Fehler_CRC_SBM_Status 0 "Test_nicht_durchgefuehrt" 1 "Test_durchgefuehrt";
VAL_ 2463978687 WH_Fehler_Timeout_SBM 0 "Fehler_passiv" 1 "Fehler_aktiv";
VAL_ 2463978687 WH_Fehler_Timeout_SBM_Status 0 "Test_nicht_durchgefuehrt" 1 "Test_durchgefuehrt";
VAL_ 2463978687 WH_Fehler_Ueberspannung 0 "Fehler_passiv" 1 "Fehler_aktiv";
VAL_ 2463978687 WH_Fehler_Ueberspannung_Status 0 "Test_nicht_durchgefuehrt" 1 "Test_durchgefuehrt";
VAL_ 2463978687 WH_Fehler_BZ_SBM 0 "Fehler_passiv" 1 "Fehler_aktiv";
VAL_ 2463978687 WH_Fehler_BZ_SBM_Status 0 "Test_nicht_durchgefuehrt" 1 "Test_durchgefuehrt";
VAL_ 2463978687 WH_Fehler_Unterspannung 0 "Fehler_passiv" 1 "Fehler_aktiv";
VAL_ 2463978687 WH_Fehler_Unterspannung_Status 0 "Test_nicht_durchgefuehrt" 1 "Test_durchgefuehrt";
VAL_ 2463978687 WH_Fehler_Ausleuchtung 0 "Fehler_passiv" 1 "Fehler_aktiv";
VAL_ 2463978687 WH_Fehler_Ausleuchtung_Status 0 "Test_nicht_durchgefuehrt" 1 "Test_durchgefuehrt";
VAL_ 2463978687 WH_Fehler_Entsperrtaste 0 "Fehler_passiv" 1 "Fehler_aktiv";
VAL_ 2463978687 WH_Fehler_Entsperrtaste_Status 0 "Test_nicht_durchgefuehrt" 1 "Test_durchgefuehrt";
VAL_ 2463978687 WH_Fehler_P_Taste 0 "Fehler_passiv" 1 "Fehler_aktiv";
VAL_ 2463978687 WH_Fehler_P_Taste_Status 0 "Test_nicht_durchgefuehrt" 1 "Test_durchgefuehrt";
VAL_ 2463978687 WH_Fehler_Sensor_einfach 0 "Fehler_passiv" 1 "Fehler_aktiv";
VAL_ 2463978687 WH_Fehler_Sensor_einfach_Status 0 "Test_nicht_durchgefuehrt" 1 "Test_durchgefuehrt";
VAL_ 2463978687 WH_Fehler_Sensor_mehrfach 0 "Fehler_passiv" 1 "Fehler_aktiv";
VAL_ 2463978687 WH_Fehler_Sensor_mehrfach_Status 0 "Test_nicht_durchgefuehrt" 1 "Test_durchgefuehrt";
VAL_ 2463978687 WH_Fehler_Shiftlock 0 "Fehler_passiv" 1 "Fehler_aktiv";
VAL_ 2463978687 WH_Fehler_Shiftlock_Status 0 "Test_nicht_durchgefuehrt" 1 "Test_durchgefuehrt";
VAL_ 916 WBA_Fahrstufe_02 0 "Zwischenstellung_keine_Position" 1 "Position_P" 2 "Position_R" 3 "Position_N" 4 "Position_D" 5 "Position_S" 6 "Position_M_Tippfunktion" 7 "Kurzzeit_M" 8 "Position_E" 9 "Position_MS" 10 "Position_S_Plus" 11 "Position_MS_Plus" 12 "Position_Offroad" 13 "Position_B";
VAL_ 916 WBA_ZielFahrstufe 0 "keine_Gangempfehlung_kein_Gang_eingelegt" 1 "Pfeil_nach_S" 2 "Pfeil_nach_D" 3 "Pfeil_nach_M" 4 "Pfeil_nach_E";
VAL_ 916 WBA_GE_Warnung_02 0 "keine_Anzeige" 1 "Fehlereskalationsstufe_I" 2 "Fehlereskalationsstufe_II" 3 "Weiterfahrt_nur_eingeschraenkt_moeglich__Kein_R_Gang" 4 "Getriebefehler_Weiterfahrt_nur_in_D_moeglich__P_bei_Motor_aus" 5 "Wegrollgefahr__P_nicht_moeglich" 6 "Paddlenotbetrieb_Schema+Warnung" 7 "Paddlenotbetrieb_Schema" 8 "Geschwindigkeitsbegrenzung_Notlauf" 9 "Fehlereskalationsst_o_Einschr" 10 "Fehlereskalationsstufe_v_Limit" 11 "Parksperre_Infostufe" 12 "Parksperre_Warnstufe_I" 13 "Parksperre_Warnstufe_II";
VAL_ 916 WBA_eing_Gang_02 0 "keine_Ganganzeige" 1 "Gang_1" 2 "Gang_2" 3 "Gang_3" 4 "Gang_4" 5 "Gang_5" 6 "Gang_6" 7 "Gang_7" 8 "Gang_8" 9 "Gang_9" 10 "Funktion_Ganganzeigeunterdrueckung" 11 "Gang_10";
VAL_ 916 WBA_GE_Texte 0 "keine_Anzeige" 1 "zum_Einlegen_einer_Fahrstufe_Fussbremse_betaetigen__ShiftLock_Information" 2 "zum_Einlegen_von_R_N_D_Fussbremse_betaetigen_und_Motor_starten" 3 "Wegrollgefahr_bitte_P_einlegen" 4 "Achtung_Zeitueberschreitung_P_wird_eingelegt" 5 "Wiederanmeldeprozedur_Bremse_betaetigen" 6 "P_nur_im_Stillstand_moeglich" 7 "Rennstart_aktiv";
VAL_ 916 WBA_Segeln_aktiv 0 "inaktiv" 1 "aktiv";
VAL_ 916 WBA_Schaltschema_02 0 "kein_Schaltschema" 1 "R_N_DS" 2 "R_N_ES" 3 "R_N_DB" 4 "R_N_D";
VAL_ 916 WBA_Schaltschema_FS_inaktiv 0 "alle_Fahrstufen_aktiv" 1 "Fahrstufe_Rueckwaerts_inaktiv" 2 "nur_P_und_N_aktiv" 3 "alle_Fahrstufen_inaktiv";
VAL_ 916 WBA_GE_Zusatzwarnungen 0 "keine_Anzeige" 1 "Getriebeueberhitzung_Warnstufe_I" 2 "Getriebeueberhitzung_Warnstufe_II" 3 "Getriebefehler_Bitte_anhalten_und_P_einlegen";
VAL_ 916 GE_Sollgang 0 "keine_Empfehlung" 1 "Gang_1" 2 "Gang_2" 3 "Gang_3" 4 "Gang_4" 5 "Gang_5" 6 "Gang_6" 7 "Gang_7" 8 "Gang_8" 9 "Gang_9" 11 "Gang_10";
VAL_ 916 GE_Tipschaltempf_verfuegbar 0 "nicht_verfuegbar" 1 "verfuegbar";
VAL_ 916 WBA_GE_Texte_02 0 "Keine_Anzeige" 1 "Fahrtrichtungswechsel_nur_nach_Stillstandt" 2 "Ladestecker_gesteckt" 3 "zusaetzlicher_Service_erforderlich" 4 "eLaunch_Aktiv" 5 "eLaunch_nicht_moeglich" 6 "WH_S_nicht_moeglich_Offroad" 7 "WH_S_nicht_moeglich_RangeMode";
VAL_ 916 WBA_Schaltschema_Tippgasse 0 "keine_Tippgasse_vorhanden" 1 "Tippgasse_vorhanden";
VAL_ 916 WBA_Schaltschema_Fahreraktion 0 "keine_Fahreraktion" 1 "Fahreraktion";
VAL_ 916 WBA_Schaltschema_FS_vorwaerts 0 "FS1_aktiv__FS2_moeglich" 1 "FS2_aktiv__FS1_moeglich" 2 "FS1_aktiv__FS2_nicht_moeglich" 3 "FS2_aktiv__FS1_nicht_moeglich";
VAL_ 916 WBA_Shiftlock_Lampe 0 "Shiftlock_Lampe_AUS" 1 "Shiftlock_Lampe_EIN";
VAL_ 916 WBA_Anforderung_Akustik 0 "Akustik_aus" 1 "Akustik_ein";
VAL_ 916 WBA_Blinken 0 "kein_WBA_Blinken" 1 "WBA_Blinken";
VAL_ 916 GE_Wiederstart_Anz_Std 0 "keine_Anzeige" 1 "Standard_Wiederstartgrund";
VAL_ 916 GE_Stoppverbot_Anz_01 0 "keine_Anzeige" 1 "Temperaturbedingung";
VAL_ 916 GE_Stoppverbot_Anz_02 0 "keine_Anzeige" 1 "Drucksensorausfall";
VAL_ 916 GE_Stoppverbot_Anz_03 0 "keine_Anzeige" 1 "Grundeinstellung";
VAL_ 916 GE_Stoppverbot_Anz_04 0 "keine_Anzeige" 1 "Demontagestellung";
VAL_ 916 GE_Stoppverbot_Anz_05 0 "keine_Anzeige" 1 "Eingeschraenkte_Fahrfunktion_Notlauf_Liegenbleiber";
VAL_ 916 GE_Stoppverbot_Anz_06 0 "keine_Anzeige" 1 "Stoppverbot_ueber_Applikation";
VAL_ 916 GE_Stoppverbot_Anz_07 0 "keine_Anzeige" 1 "Schaltung_aktiv";
VAL_ 916 GE_Stoppverbot_Anz_Std 0 "keine_Anzeige" 1 "Standard_Stoppvetogrund";
VAL_ 1361 WFS_Schluessel_Fahrberecht 0 "kein authorisierter Schluessel erkannt" 1 "aktive_Funkschluessel_Nr_01" 2 "aktive_Funkschluessel_Nr_02" 3 "aktive_Funkschluessel_Nr_03" 4 "aktive_Funkschluessel_Nr_04" 5 "aktive_Funkschluessel_Nr_05" 6 "aktive_Funkschluessel_Nr_06" 7 "aktive_Funkschluessel_Nr_07" 8 "aktive_Funkschluessel_Nr_08" 9 "ungueltig_09" 10 "ungueltig_10" 11 "ungueltig_11" 12 "ungueltig_12" 13 "ungueltig_13" 14 "ungueltig_14" 15 "digitaler_Schluessel_aktiv";
VAL_ 1361 WFS_Verbauinfo_ELV 0 "ELV_nicht_verbaut" 1 "ELV_verbaut";
VAL_ 1361 WFS_ID_Geb_autorisiert 0 "Schluessel_nicht_authorisiert" 1 "Schluessel authorisiert";
VAL_ 1361 WFS_ID_Geb_autorisiert_in_Kl15 0 "nicht_authorisiert_in_Kl15" 1 "authorisiert_in_Kl15";
VAL_ 1361 WFS_ID_Geb_steckt 0 "kein_Schluessel_im_Zuendschloss" 1 " Schluessel steckt im Zuendschloss";
VAL_ 1361 WFS_Safe 1 "WFS nicht deaktiviert";
VAL_ 1361 WFS_LZ 0 "nicht def." 1 "LZ 1" 2 "LZ 2" 3 "LZ 3";
VAL_ 1361 WFS_ELV_authorisiert 0 "ELV_nicht_authorisiert" 1 "ELV_authorisiert";
VAL_ 1361 WFS_LF_Aktiv 0 "Funktempfang_nicht_aktiv" 1 "LF_Funkempfang_aktiv";
VAL_ 1361 WFS_Betrieb_Lesespule 0 "keine_Schluesselkomm_Lesespule" 1 "Schluesselkomm_Lesespule";
VAL_ 1361 WFS_Klemmenfreigabe 0 "keine_Freigabe" 1 "Freigabe";
VAL_ 1361 WFS_Fahrerhinweise 0 "Keine_Anzeigeanforderung" 1 "Schuessel_Auth_niO" 2 "Notlauf_aktiv" 3 "Schluessel_Kessy_nicht_gefunden";
VAL_ 1361 WFS_Parken_Status 0 "Limitierung_inaktiv" 1 "Limitierung_aktiv" 2 "Abbruch";
VAL_ 1411 ZV_verriegeln_Anf 0 "nicht_betaetigt" 1 "betaetigt";
VAL_ 1411 ZV_STSG_HFS_Anf 0 "keine_Anforderung" 1 "Anforderung";
VAL_ 1411 ZV_STSG_HBFS_Anf 0 "keine_Anforderung" 1 "Anforderung";
VAL_ 1411 ZV_Anf_Challenge_Auth 0 "nicht_aktiv" 1 "aktiv";
VAL_ 1411 BCM_FH_Freigabe 1 "Funktionsfreigabe Fensterheber";
VAL_ 1411 BCM_Komfortfkt_Freigabe 0 "Komfortfunktion gesperrt" 1 "globale Freigabe der Komfortfunktion erteilt";
VAL_ 1411 BCM_HSK_Freigabe 0 "erlauben" 1 "sperren";
VAL_ 1411 BCM_Verdeck_Freigabe 0 "Verdeckbetrieb nicht erlaubt" 1 "Verdeckbetrieb erlaubt";
VAL_ 1411 ZV_verriegelt_intern_ist 1 "Fahrzeug innen verriegelt; Istzustand";
VAL_ 1411 ZV_verriegelt_extern_ist 1 "Fahrzeug_aussen_verriegelt_Istzustand";
VAL_ 1411 ZV_verriegelt_intern_soll 1 "Fahrzeug verriegelt intern; Sollzusstand";
VAL_ 1411 ZV_verriegelt_extern_soll 1 "Fahrzeug verriegelt extern; Sollzusstand";
VAL_ 1411 ZV_gesafet_extern_ist 1 "Fahrzeug aussen gesafet; Istzustand";
VAL_ 1411 ZV_gesafet_extern_soll 1 "Fahrzeug_aussen_gesafet_Sollzustand";
VAL_ 1411 ZV_Einzeltuerentriegelung 1 "Fahrzeug an Einzeltuer entriegelt";
VAL_ 1411 ZV_Heckeinzelentriegelung 1 "Heckdeckeleinzelentriegelung";
VAL_ 1411 ZV_FT_offen 1 "FT_geoeffnet";
VAL_ 1411 ZV_BT_offen 1 "BT_geoeffnet";
VAL_ 1411 ZV_HFS_offen 0 "geschlossen" 1 "offen";
VAL_ 1411 ZV_HBFS_offen 0 "geschlossen" 1 "offen";
VAL_ 1411 ZV_HD_offen 1 "Heckdeckel_auf";
VAL_ 1411 ZV_HS_offen 0 "Heckscheibe_geschlossen" 1 "Heckscheibe auf";
VAL_ 1411 IRUE_aktiv 0 "unscharf" 1 "scharf";
VAL_ 1411 DWA_aktiv 0 "unscharf" 1 "scharf";
VAL_ 1411 FFB_HDF_Taste 0 "Taste_nicht_betaetigt" 1 "HDF_Taste_am_Funkschluessel_betaetigt";
VAL_ 1411 FFB_Panik_Taste 0 "Taste_nicht_betaetigt" 1 "Panik_Taste_am_Funkschluessel_betaetigt";
VAL_ 1411 FFB_Auf_Taste 0 "Taste_nicht_betaetigt" 1 "Oeffnentaste_betaetigt";
VAL_ 1411 FFB_Zu_Taste 0 "Taste_nicht_betaetigt" 1 "Zu_Taste_am_Funkschluessel_betaetigt";
VAL_ 1411 FFB_CarFinder 0 "nicht aktiv" 1 "aktiv";
VAL_ 1411 FFB_Komfortoeffnen 0 "kein_Komfortoeffnen_empfangen" 1 "Komfortoeffnen ueber Funk empfangen";
VAL_ 1411 FFB_Komfortschliessen 0 "kein_Komfortschliessen_empfangen" 1 "Komfortschliessen ueber Funk empfangen";
VAL_ 1411 FBS_IDG_in_Reichweite 0 "ausser_Reichweite_bzw_nicht_ermittelbar" 1 "innerhalb_Reichweite";
VAL_ 1411 ZV_Schluessel_Zugang 0 "kein authorisierter Schluessel erkannt " 1 "aktive_Funkschluessel_Nr_01" 2 "aktive_Funkschluessel_Nr_02" 3 "aktive_Funkschluessel_Nr_03" 4 "aktive_Funkschluessel_Nr_04" 5 "aktive_Funkschluessel_Nr_05" 6 "aktive_Funkschluessel_Nr_06" 7 "aktive_Funkschluessel_Nr_07" 8 "aktive_Funkschluessel_Nr_08" 9 "ungueltig_09" 10 "ungueltig_10" 11 "ungueltig_11" 12 "ungueltig_12" 13 "ungueltig_13" 14 "ungueltig_14" 15 "ungueltig_15";
VAL_ 1411 ZV_SafeFunktion_aktiv 0 "inaktiv" 1 "aktiv";
VAL_ 1411 FBS_Warn_Schluessel_Batt 0 "i.O." 1 "defekt";
VAL_ 1411 ZV_Oeffnungsmodus 0 "globale_Oeffnung" 1 "ZV_mit_Einzeltuerentr" 2 "ZV_individuell_selektiv" 3 "ZV_seitenselektiv";
VAL_ 1411 ZV_ist_Zustand_verfuegbar 0 "nicht_verfuegbar" 1 "verfuegbar_alle_TSGs_am_Bus";
VAL_ 1411 IRUE_Taster_Fkts_LED 0 "LED_aus" 1 "LED_ein";
VAL_ 1411 ZV_Tankklappe_offen 0 "Tankklappe_geschlossen" 1 "Tankklappe_offen";
VAL_ 1411 ZV_Rollo_auf 0 "inaktiv" 1 "aktiv";
VAL_ 1411 ZV_Rollo_zu 0 "inaktiv" 1 "aktiv";
VAL_ 1411 ZV_SAD_auf 0 "inaktiv" 1 "aktiv";
VAL_ 1411 ZV_SAD_zu 0 "inaktiv" 1 "aktiv";
VAL_ 1411 ZV_verriegelt_soll 0 "Init" 1 "nicht_verriegelt" 2 "verriegelt";
